VERSION ""

NS_ :

BS_:

BU_: SCM BC1 BC2 ECM PSC ABS Brakes__Drive_Axle_1 EPS IC GPS WCM VCM Seat_Control_1 ISC1 HCU IDT GMRS XM RH AUTON LHC CIM IMU BC3 IC2 EPC1 EPC2 EPC3 EPC4 BMC1 BMC2 APU2 APU1 SRVTOOL RHC RCM

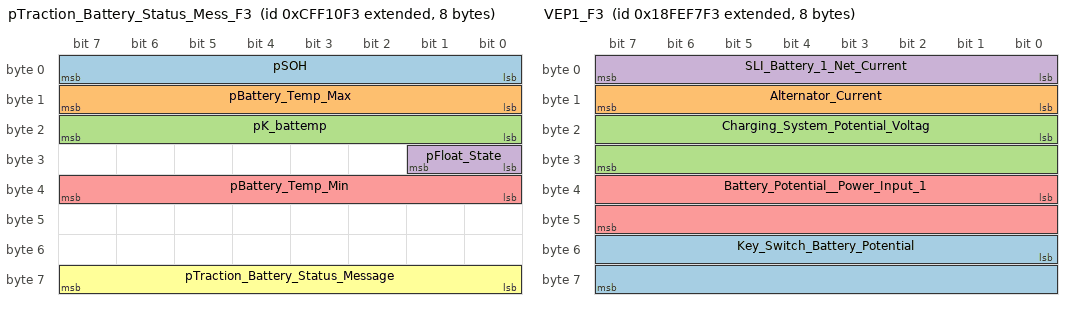
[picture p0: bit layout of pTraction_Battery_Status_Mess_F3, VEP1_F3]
BO_ 2365526259 pTraction_Battery_Status_Mess_F3: 8 BMC1
 SG_ pSOH : 0|8@1+ (0.5,0) [0|127] "%" Vector__XXX
 SG_ pBattery_Temp_Max : 8|8@1+ (1,-40) [-40|295] "deg C" Vector__XXX
 SG_ pK_battemp : 16|8@1+ (0.5,0) [0|127] "%" Vector__XXX
 SG_ pFloat_State : 24|2@1+ (1,0) [0|3] "state" Vector__XXX
 SG_ pBattery_Temp_Min : 32|8@1+ (1,-40) [-40|295] "deg C" Vector__XXX
 SG_ pTraction_Battery_Status_Message : 56|8@1+ (1,0) [0|255] "" Vector__XXX

BO_ 2566846451 VEP1_F3: 8 BMC1
 SG_ Key_Switch_Battery_Potential : 48|16@1+ (0.05,0) [0|3275.8] "V" Vector__XXX
 SG_ Alternator_Current : 8|8@1+ (1,0) [0|255] "A" Vector__XXX
 SG_ Charging_System_Potential_Voltag : 16|16@1+ (0.05,0) [0|3275.8] "V" Vector__XXX
 SG_ SLI_Battery_1_Net_Current : 0|8@1+ (1,-125) [-125|380] "A" Vector__XXX
 SG_ Battery_Potential__Power_Input_1 : 32|16@1+ (0.05,0) [0|3275.8] "V" Vector__XXX

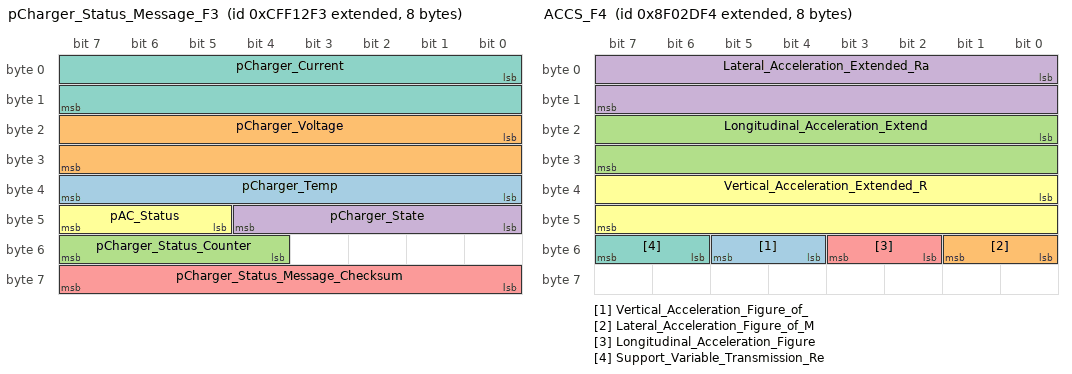
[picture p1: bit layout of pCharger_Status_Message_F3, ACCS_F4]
BO_ 2365526771 pCharger_Status_Message_F3: 8 BMC1
 SG_ pCharger_Temp : 32|8@1+ (1,-40) [-40|295] "deg C" Vector__XXX
 SG_ pCharger_Voltage : 16|16@1+ (0.05,0) [0|3275.8] "V" Vector__XXX
 SG_ pCharger_Status_Counter : 52|4@1+ (1,0) [0|15] "count" Vector__XXX
 SG_ pCharger_State : 40|5@1+ (1,0) [0|31] "state" Vector__XXX
 SG_ pCharger_Status_Message_Checksum : 56|8@1+ (1,0) [0|255] "" Vector__XXX
 SG_ pAC_Status : 45|3@1+ (1,0) [0|7] "state" Vector__XXX
 SG_ pCharger_Current : 0|16@1+ (0.05,-1600) [-1600|4875.8] "A" Vector__XXX

BO_ 2297441780 ACCS_F4: 8 BMC2
 SG_ Vertical_Acceleration_Figure_of_ : 52|2@1+ (1,0) [0|3] "bit" Vector__XXX
 SG_ Lateral_Acceleration_Figure_of_M : 48|2@1+ (1,0) [0|3] "bit" Vector__XXX
 SG_ Longitudinal_Acceleration_Extend : 16|16@1+ (0.01,-320) [-320|974.36] "m/s2" Vector__XXX
 SG_ Lateral_Acceleration_Extended_Ra : 0|16@1+ (0.01,-320) [-320|974.36] "m/s2" Vector__XXX
 SG_ Longitudinal_Acceleration_Figure : 50|2@1+ (1,0) [0|3] "bit" Vector__XXX
 SG_ Vertical_Acceleration_Extended_R : 32|16@1+ (0.01,-320) [-320|974.36] "m/s2" Vector__XXX
 SG_ Support_Variable_Transmission_Re : 54|2@1+ (1,0) [0|3] "bit" Vector__XXX

BO_ 2365526004 pEnergy_Message_F4: 8 BMC2
 SG_ pSOC : 0|8@1+ (0.5,0) [0|127] "%" Vector__XXX
 SG_ pAvailable_Wh : 8|16@1+ (4,0) [0|262143] "kWh" Vector__XXX
 SG_ pWh_in_Since_key_on : 24|32@1+ (1,-131.072) [-131.072|4294967426.072] "Watt-hour" Vector__XXX
 SG_ pEnergy_Message_Checksum : 56|8@1+ (1,0) [0|255] "" Vector__XXX

BO_ 2365525748 pBMC_Power_Message_F4: 8 BMC2
 SG_ pPack_Voltage : 16|16@1+ (0.05,0) [0|3275.8] "V" Vector__XXX
 SG_ pDischarge_Limit : 40|12@1+ (0.5,0) [0|2047] "A" Vector__XXX
 SG_ pPack_Current : 0|16@1+ (0.05,-1600) [-1600|4875.8] "A" Vector__XXX
 SG_ pBMC_Power_Message_Checksum : 56|8@1+ (1,0) [0|255] "" Vector__XXX
 SG_ pCharge_Limit : 44|12@1+ (0.5,0) [0|2047] "A" Vector__XXX

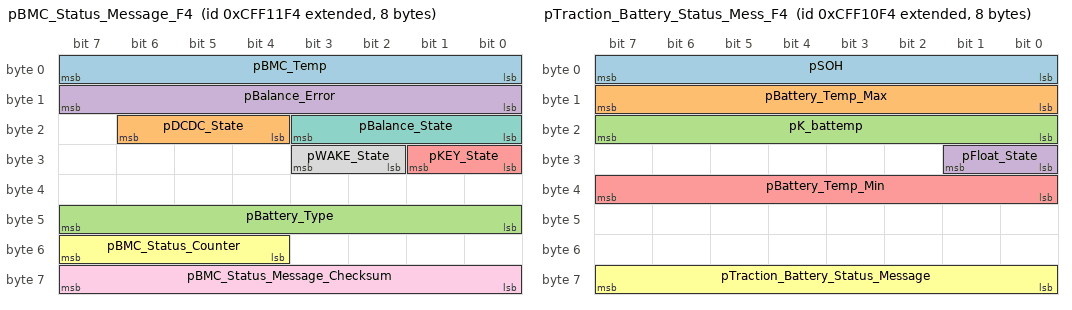
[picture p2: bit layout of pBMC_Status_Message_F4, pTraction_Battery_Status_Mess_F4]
BO_ 2365526516 pBMC_Status_Message_F4: 8 BMC2
 SG_ pBMC_Temp : 0|8@1+ (1,-40) [-40|295] "deg C" Vector__XXX
 SG_ pDCDC_State : 20|3@1+ (1,0) [0|7] "state" Vector__XXX
 SG_ pBattery_Type : 40|8@1+ (1,0) [0|255] "state" Vector__XXX
 SG_ pBalance_Error : 8|8@1+ (0.5,-6.4) [-6.4|133.4] "%" Vector__XXX
 SG_ pKEY_State : 24|2@1+ (1,0) [0|3] "state" Vector__XXX
 SG_ pBMC_Status_Counter : 52|4@1+ (1,0) [0|15] "count" Vector__XXX
 SG_ pBalance_State : 16|4@1+ (1,0) [0|15] "state" Vector__XXX
 SG_ pWAKE_State : 26|2@1+ (1,0) [0|3] "state" Vector__XXX
 SG_ pBMC_Status_Message_Checksum : 56|8@1+ (1,0) [0|255] "" Vector__XXX

BO_ 2365526260 pTraction_Battery_Status_Mess_F4: 8 BMC2
 SG_ pSOH : 0|8@1+ (0.5,0) [0|127] "%" Vector__XXX
 SG_ pBattery_Temp_Max : 8|8@1+ (1,-40) [-40|295] "deg C" Vector__XXX
 SG_ pK_battemp : 16|8@1+ (0.5,0) [0|127] "%" Vector__XXX
 SG_ pFloat_State : 24|2@1+ (1,0) [0|3] "state" Vector__XXX
 SG_ pBattery_Temp_Min : 32|8@1+ (1,-40) [-40|295] "deg C" Vector__XXX
 SG_ pTraction_Battery_Status_Message : 56|8@1+ (1,0) [0|255] "" Vector__XXX

BO_ 2566846452 VEP1_F4: 8 BMC2
 SG_ Key_Switch_Battery_Potential : 48|16@1+ (0.05,0) [0|3275.8] "V" Vector__XXX
 SG_ Alternator_Current : 8|8@1+ (1,0) [0|255] "A" Vector__XXX
 SG_ Charging_System_Potential_Voltag : 16|16@1+ (0.05,0) [0|3275.8] "V" Vector__XXX
 SG_ SLI_Battery_1_Net_Current : 0|8@1+ (1,-125) [-125|380] "A" Vector__XXX
 SG_ Battery_Potential__Power_Input_1 : 32|16@1+ (0.05,0) [0|3275.8] "V" Vector__XXX

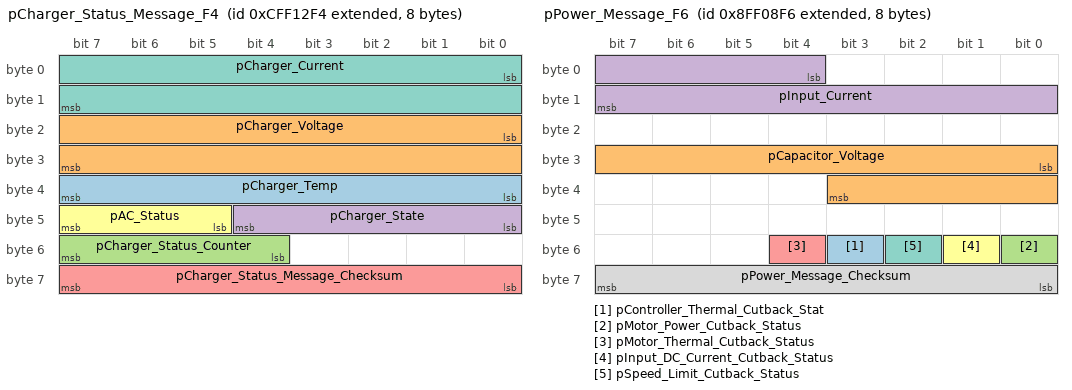
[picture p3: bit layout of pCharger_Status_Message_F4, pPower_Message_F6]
BO_ 2365526772 pCharger_Status_Message_F4: 8 BMC2
 SG_ pCharger_Temp : 32|8@1+ (1,-40) [-40|295] "deg C" Vector__XXX
 SG_ pCharger_Voltage : 16|16@1+ (0.05,0) [0|3275.8] "V" Vector__XXX
 SG_ pCharger_Status_Counter : 52|4@1+ (1,0) [0|15] "count" Vector__XXX
 SG_ pCharger_State : 40|5@1+ (1,0) [0|31] "state" Vector__XXX
 SG_ pCharger_Status_Message_Checksum : 56|8@1+ (1,0) [0|255] "" Vector__XXX
 SG_ pAC_Status : 45|3@1+ (1,0) [0|7] "state" Vector__XXX
 SG_ pCharger_Current : 0|16@1+ (0.05,-1600) [-1600|4875.8] "A" Vector__XXX

BO_ 2298415350 pPower_Message_F6: 8 APU2
 SG_ pController_Thermal_Cutback_Stat : 51|1@1+ (1,0) [0|1] "state" Vector__XXX
 SG_ pCapacitor_Voltage : 24|12@1+ (1,0) [0|4095] "V" Vector__XXX
 SG_ pMotor_Power_Cutback_Status : 48|1@1+ (1,0) [0|1] "state" Vector__XXX
 SG_ pInput_Current : 4|12@1+ (1,-2048) [-2048|6143] "A" Vector__XXX
 SG_ pMotor_Thermal_Cutback_Status : 52|1@1+ (1,0) [0|1] "state" Vector__XXX
 SG_ pInput_DC_Current_Cutback_Status : 49|1@1+ (1,0) [0|1] "state" Vector__XXX
 SG_ pSpeed_Limit_Cutback_Status : 50|1@1+ (1,0) [0|1] "state" Vector__XXX
 SG_ pPower_Message_Checksum : 56|8@1+ (1,0) [0|255] "" Vector__XXX

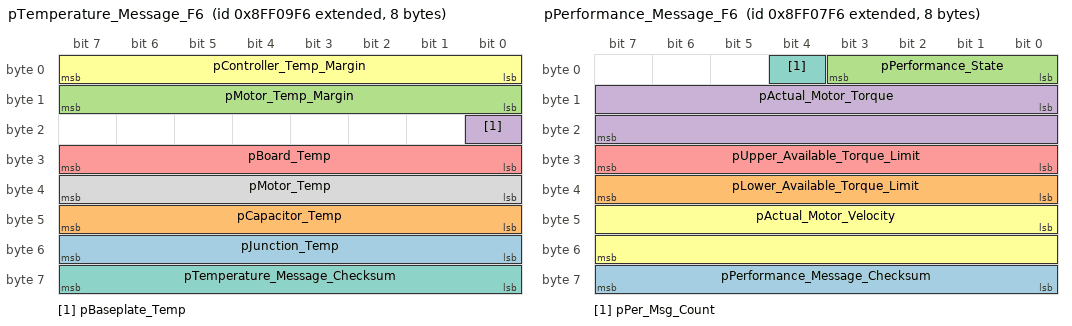
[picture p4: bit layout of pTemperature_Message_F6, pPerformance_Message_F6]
BO_ 2298415606 pTemperature_Message_F6: 8 APU2
 SG_ pJunction_Temp : 48|8@1+ (1,-40) [-40|295] "deg C" Vector__XXX
 SG_ pCapacitor_Temp : 40|8@1+ (1,-40) [-40|295] "deg C" Vector__XXX
 SG_ pMotor_Temp_Margin : 8|8@1+ (1,0) [0|255] "deg C" Vector__XXX
 SG_ pBaseplate_Temp : 16|1@1+ (1,-40) [-40|40] "deg C" Vector__XXX
 SG_ pBoard_Temp : 24|8@1+ (1,-40) [-40|295] "deg C" Vector__XXX
 SG_ pController_Temp_Margin : 0|8@1+ (1,0) [0|255] "deg C" Vector__XXX
 SG_ pTemperature_Message_Checksum : 56|8@1+ (1,0) [0|255] "" Vector__XXX
 SG_ pMotor_Temp : 32|8@1+ (1,-40) [-40|295] "deg C" Vector__XXX

BO_ 2298415094 pPerformance_Message_F6: 8 APU2
 SG_ pPerformance_Message_Checksum : 56|8@1+ (1,0) [0|255] "" Vector__XXX
 SG_ pLower_Available_Torque_Limit : 32|8@1+ (2.5,-312.5) [-312.5|951.5] "Nm" Vector__XXX
 SG_ pPerformance_State : 0|4@1+ (1,0) [0|15] "state" Vector__XXX
 SG_ pActual_Motor_Torque : 8|16@1+ (0.1,-3276.8) [-3276.8|9829.4] "Nm" Vector__XXX
 SG_ pUpper_Available_Torque_Limit : 24|8@1+ (2.5,-312.5) [-312.5|951.5] "Nm" Vector__XXX
 SG_ pActual_Motor_Velocity : 40|16@1+ (1,-32768) [-32768|98303] "rpm" Vector__XXX
 SG_ pPer_Msg_Count : 4|1@1+ (1,0) [0|0] "unknown" Vector__XXX

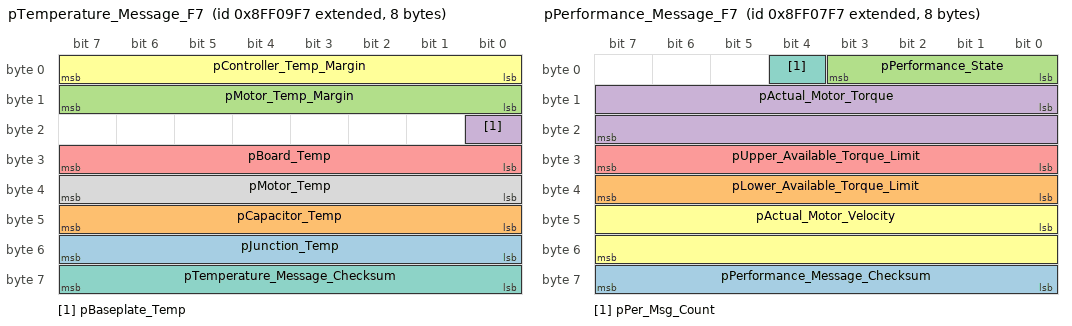
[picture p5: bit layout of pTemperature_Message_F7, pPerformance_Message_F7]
BO_ 2298415607 pTemperature_Message_F7: 8 APU1
 SG_ pJunction_Temp : 48|8@1+ (1,-40) [-40|295] "deg C" Vector__XXX
 SG_ pCapacitor_Temp : 40|8@1+ (1,-40) [-40|295] "deg C" Vector__XXX
 SG_ pMotor_Temp_Margin : 8|8@1+ (1,0) [0|255] "deg C" Vector__XXX
 SG_ pBaseplate_Temp : 16|1@1+ (1,-40) [-40|40] "deg C" Vector__XXX
 SG_ pBoard_Temp : 24|8@1+ (1,-40) [-40|295] "deg C" Vector__XXX
 SG_ pController_Temp_Margin : 0|8@1+ (1,0) [0|255] "deg C" Vector__XXX
 SG_ pTemperature_Message_Checksum : 56|8@1+ (1,0) [0|255] "" Vector__XXX
 SG_ pMotor_Temp : 32|8@1+ (1,-40) [-40|295] "deg C" Vector__XXX

BO_ 2298415095 pPerformance_Message_F7: 8 APU1
 SG_ pPerformance_Message_Checksum : 56|8@1+ (1,0) [0|255] "" Vector__XXX
 SG_ pLower_Available_Torque_Limit : 32|8@1+ (2.5,-312.5) [-312.5|951.5] "Nm" Vector__XXX
 SG_ pPerformance_State : 0|4@1+ (1,0) [0|15] "state" Vector__XXX
 SG_ pActual_Motor_Torque : 8|16@1+ (0.1,-3276.8) [-3276.8|9829.4] "Nm" Vector__XXX
 SG_ pUpper_Available_Torque_Limit : 24|8@1+ (2.5,-312.5) [-312.5|951.5] "Nm" Vector__XXX
 SG_ pActual_Motor_Velocity : 40|16@1+ (1,-32768) [-32768|98303] "rpm" Vector__XXX
 SG_ pPer_Msg_Count : 4|1@1+ (1,0) [0|0] "unknown" Vector__XXX

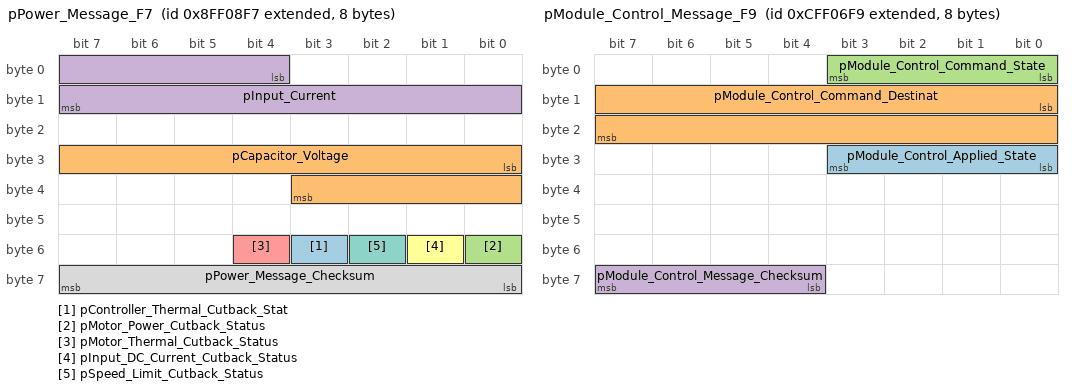
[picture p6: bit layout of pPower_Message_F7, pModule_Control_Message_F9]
BO_ 2298415351 pPower_Message_F7: 8 APU1
 SG_ pController_Thermal_Cutback_Stat : 51|1@1+ (1,0) [0|1] "state" Vector__XXX
 SG_ pCapacitor_Voltage : 24|12@1+ (1,0) [0|4095] "V" Vector__XXX
 SG_ pMotor_Power_Cutback_Status : 48|1@1+ (1,0) [0|1] "state" Vector__XXX
 SG_ pInput_Current : 4|12@1+ (1,-2048) [-2048|6143] "A" Vector__XXX
 SG_ pMotor_Thermal_Cutback_Status : 52|1@1+ (1,0) [0|1] "state" Vector__XXX
 SG_ pInput_DC_Current_Cutback_Status : 49|1@1+ (1,0) [0|1] "state" Vector__XXX
 SG_ pSpeed_Limit_Cutback_Status : 50|1@1+ (1,0) [0|1] "state" Vector__XXX
 SG_ pPower_Message_Checksum : 56|8@1+ (1,0) [0|255] "" Vector__XXX

BO_ 2566834937 DM1_F9: 42 SRVTOOL
 SG_ Flash_Malfunction_Indicator_Lamp : 14|2@1+ (1,0) [0|3] "" Vector__XXX
 SG_ Malfunction_Indicator_Lamp_Statu : 6|2@1+ (1,0) [0|3] "" Vector__XXX
 SG_ Red_Stop_Lamp_Status : 4|2@1+ (1,0) [0|3] "" Vector__XXX
 SG_ Amber_Warning_Lamp_Status : 2|2@1+ (1,0) [0|3] "" Vector__XXX
 SG_ Flash_Red_Stop_Lamp_RSL : 12|2@1+ (1,0) [0|3] "" Vector__XXX
 SG_ Flash_Amber_Warning_Lamp_AWL : 10|2@1+ (1,0) [0|3] "" Vector__XXX
 SG_ Flash_Protect_Lamp : 8|2@1+ (1,0) [0|3] "" Vector__XXX
 SG_ Protect_Lamp_Status : 0|2@1+ (1,0) [0|3] "" Vector__XXX
 SG_ DTC_1 : 16|32@1+ (1,0) [0|4294967295] "value" Vector__XXX
 SG_ DTC_2 : 48|32@1+ (1,0) [0|4294967295] "value" Vector__XXX
 SG_ DTC_3 : 80|32@1+ (1,0) [0|4294967295] "value" Vector__XXX
 SG_ DTC_4 : 112|32@1+ (1,0) [0|4294967295] "value" Vector__XXX
 SG_ DTC_5 : 144|32@1+ (1,0) [0|4294967295] "value" Vector__XXX
 SG_ DTC_6 : 176|32@1+ (1,0) [0|4294967295] "value" Vector__XXX
 SG_ DTC_7 : 208|32@1+ (1,0) [0|4294967295] "value" Vector__XXX
 SG_ DTC_8 : 240|32@1+ (1,0) [0|4294967295] "value" Vector__XXX
 SG_ DTC_9 : 272|32@1+ (1,0) [0|4294967295] "value" Vector__XXX
 SG_ DTC_10 : 304|32@1+ (1,0) [0|4294967295] "value" Vector__XXX

BO_ 2365523705 pModule_Control_Message_F9: 8 SRVTOOL
 SG_ pModule_Control_Applied_State : 24|4@1+ (1,0) [0|15] "state" Vector__XXX
 SG_ pModule_Control_Command_Destinat : 8|16@1+ (1,0) [0|65535] "count" Vector__XXX
 SG_ pModule_Control_Command_State : 0|4@1+ (1,0) [0|15] "state" Vector__XXX
 SG_ pModule_Control_Message_Checksum : 60|4@1+ (1,0) [0|15] "bit" Vector__XXX

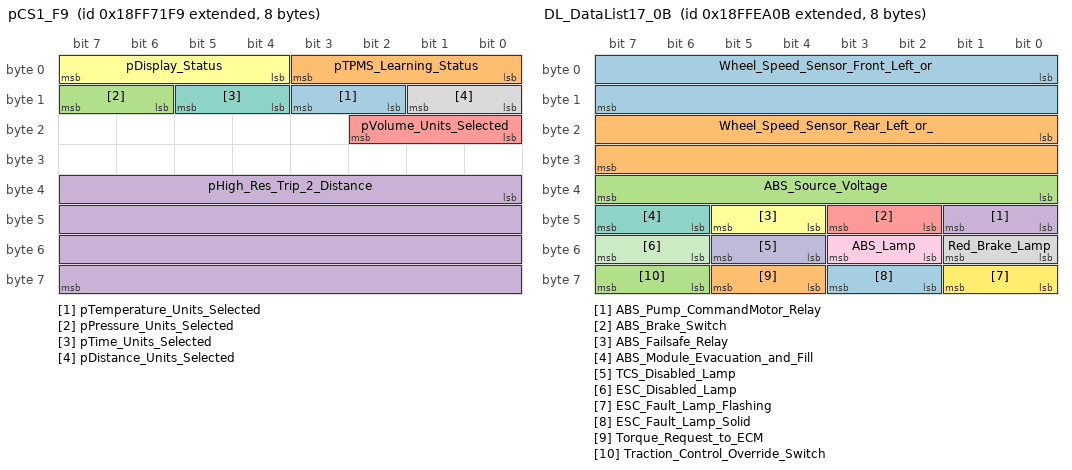
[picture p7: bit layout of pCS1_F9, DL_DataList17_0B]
BO_ 2566877689 pCS1_F9: 8 SRVTOOL
 SG_ pTemperature_Units_Selected : 10|2@1+ (1,0) [0|3] "state" Vector__XXX
 SG_ pTPMS_Learning_Status : 0|4@1+ (1,0) [0|15] "state" Vector__XXX
 SG_ pPressure_Units_Selected : 14|2@1+ (1,0) [0|3] "state" Vector__XXX
 SG_ pHigh_Res_Trip_2_Distance : 32|32@1+ (5,0) [0|21474836479] "km" Vector__XXX
 SG_ pVolume_Units_Selected : 16|3@1+ (1,0) [0|7] "state" Vector__XXX
 SG_ pDisplay_Status : 4|4@1+ (1,0) [0|15] "state" Vector__XXX
 SG_ pTime_Units_Selected : 12|2@1+ (1,0) [0|3] "state" Vector__XXX
 SG_ pDistance_Units_Selected : 8|2@1+ (1,0) [0|3] "state" Vector__XXX

BO_ 2566860071 pISM_27: 8 VCM
 SG_ pSpecial_Msg_12 : 22|2@1+ (1,0) [0|3] "state" Vector__XXX
 SG_ pSpecial_Msg_28 : 54|2@1+ (1,0) [0|3] "state" Vector__XXX
 SG_ pSpecial_Msg_11 : 20|2@1+ (1,0) [0|3] "state" Vector__XXX
 SG_ pSpecial_Msg_26 : 50|2@1+ (1,0) [0|3] "state" Vector__XXX
 SG_ pSpecial_Msg_24 : 46|2@1+ (1,0) [0|3] "state" Vector__XXX
 SG_ pSpecial_Msg_21 : 40|2@1+ (1,0) [0|3] "state" Vector__XXX
 SG_ pSpecial_Msg_18 : 34|2@1+ (1,0) [0|3] "state" Vector__XXX
 SG_ pSpecial_Msg_19 : 36|2@1+ (1,0) [0|3] "state" Vector__XXX
 SG_ pSpecial_Msg_1_Riding_with_Brake : 0|2@1+ (1,0) [0|3] "state" Vector__XXX
 SG_ pSpecial_Msg_2_Regulator_Overhea : 2|2@1+ (1,0) [0|3] "state" Vector__XXX
 SG_ pSpecial_Msg_3_Regulator_Overhea : 4|2@1+ (1,0) [0|3] "state" Vector__XXX
 SG_ pSpecial_Msg_4_Regulator_Overhea : 6|2@1+ (1,0) [0|3] "state" Vector__XXX
 SG_ pSpecial_Msg_5_Engine_Warmup_Com : 8|2@1+ (1,0) [0|3] "state" Vector__XXX
 SG_ pSpecial_Msg_6_Engine_Knock__Mod : 10|2@1+ (1,0) [0|3] "state" Vector__XXX
 SG_ pSpecial_Msg_8_Low_Coolant_Warni : 14|2@1+ (1,0) [0|3] "state" Vector__XXX
 SG_ pSpecial_Msg_7_Engine_Knock__Mos : 12|2@1+ (1,0) [0|3] "state" Vector__XXX
 SG_ pSpecial_Msg_9_Transmission_Temp : 16|2@1+ (1,0) [0|3] "state" Vector__XXX
 SG_ pSpecial_Msg_10_Reverse_Speed_Li : 18|2@1+ (1,0) [0|3] "state" Vector__XXX
 SG_ pSpecial_Msg_13_Belt_Burn_Warnin : 24|2@1+ (1,0) [0|3] "state" Vector__XXX
 SG_ pSpecial_Msg_14_Park_Brake_Warni : 26|2@1+ (1,0) [0|3] "state" Vector__XXX
 SG_ pSpecial_Msg_15_TCM_Comm_Loss : 28|2@1+ (1,0) [0|3] "state" Vector__XXX
 SG_ pSpecial_Msg_16_TCM_Pump_Priming : 30|2@1+ (1,0) [0|3] "state" Vector__XXX
 SG_ pSpecial_Msg_17_Request_User_to_ : 32|2@1+ (1,0) [0|3] "state" Vector__XXX
 SG_ pSpecial_MSG_20_Fuel_Door_Open_E : 38|2@1+ (1,0) [0|3] "state" Vector__XXX
 SG_ pSpecial_MSG_22_Clutch_Overtemp : 42|2@1+ (1,0) [0|3] "state" Vector__XXX
 SG_ pSpecial_MSG_23_Exhaust_Valve_Ch : 44|2@1+ (1,0) [0|3] "state" Vector__XXX
 SG_ pSpecial_MSG_25_Engine_Idle_Shut : 48|2@1+ (1,0) [0|3] "state" Vector__XXX
 SG_ pSpecial_MSG_27_Overboost_Condit : 52|2@1+ (1,0) [0|3] "state" Vector__XXX
 SG_ pSpecial_Msg_31_Engine_Tip_Over_ : 60|2@1+ (1,0) [0|3] "state" Vector__XXX
 SG_ pSpecial_Msg_32_Engine_Tip_Over_ : 62|2@1+ (1,0) [0|3] "state" Vector__XXX

BO_ 2566908427 DL_DataList17_0B: 8 ABS
 SG_ Wheel_Speed_Sensor_Front_Left_or : 0|16@1+ (0.00390625,0) [0|255] "km/h" Vector__XXX
 SG_ Wheel_Speed_Sensor_Rear_Left_or_ : 16|16@1+ (0.00390625,0) [0|255] "km/h" Vector__XXX
 SG_ ABS_Source_Voltage : 32|8@1+ (0.1,0) [0|24.6] "V" Vector__XXX
 SG_ ABS_Pump_CommandMotor_Relay : 40|2@1+ (0,0) [0|-1] "state" Vector__XXX
 SG_ ABS_Brake_Switch : 42|2@1+ (0,0) [0|-1] "state" Vector__XXX
 SG_ ABS_Failsafe_Relay : 44|2@1+ (0,0) [0|-1] "state" Vector__XXX
 SG_ ABS_Module_Evacuation_and_Fill : 46|2@1+ (0,0) [0|-1] "state" Vector__XXX
 SG_ Red_Brake_Lamp : 48|2@1+ (0,0) [0|-1] "state" Vector__XXX
 SG_ ABS_Lamp : 50|2@1+ (0,0) [0|-1] "state" Vector__XXX
 SG_ TCS_Disabled_Lamp : 52|2@1+ (0,0) [0|-1] "state" Vector__XXX
 SG_ ESC_Disabled_Lamp : 54|2@1+ (0,0) [0|-1] "state" Vector__XXX
 SG_ ESC_Fault_Lamp_Flashing : 56|2@1+ (0,0) [0|-1] "state" Vector__XXX
 SG_ ESC_Fault_Lamp_Solid : 58|2@1+ (0,0) [0|-1] "state" Vector__XXX
 SG_ Torque_Request_to_ECM : 60|2@1+ (0,0) [0|-1] "state" Vector__XXX
 SG_ Traction_Control_Override_Switch : 62|2@1+ (0,0) [0|-1] "state" Vector__XXX

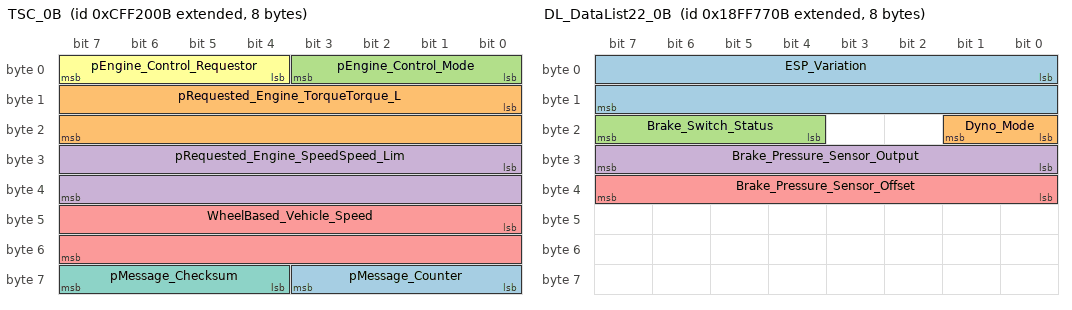
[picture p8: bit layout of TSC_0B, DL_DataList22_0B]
BO_ 2365530123 TSC_0B: 8 ABS
 SG_ pMessage_Counter : 56|4@1+ (1,0) [0|15] "count" Vector__XXX
 SG_ pRequested_Engine_TorqueTorque_L : 8|16@1+ (0.03125,-400) [-400|2447] "Nm" Vector__XXX
 SG_ pEngine_Control_Mode : 0|4@1+ (1,0) [0|15] "state" Vector__XXX
 SG_ pRequested_Engine_SpeedSpeed_Lim : 24|16@1+ (1,0) [0|65535] "rpm" Vector__XXX
 SG_ WheelBased_Vehicle_Speed : 40|16@1+ (0.00390625,0) [0|255] "km/h" Vector__XXX
 SG_ pEngine_Control_Requestor : 4|4@1+ (1,0) [0|15] "state" Vector__XXX
 SG_ pMessage_Checksum : 60|4@1+ (1,0) [0|15] "count" Vector__XXX

BO_ 2566879243 DL_DataList_0B: 8 ABS
 SG_ Wheel_Speed_Sensor_Front_Right : 0|16@1+ (0.00390625,0) [0|255] "km/h" Vector__XXX
 SG_ Wheel_Speed_Sensor_Rear_Right : 16|16@1+ (0.00390625,0) [0|255] "km/h" Vector__XXX
 SG_ Steering_Angle : 32|16@1+ (0.000976563,0) [0|63.000032768] "rad" Vector__XXX
 SG_ Yaw_Rate : 48|16@1+ (0.00012207,0) [0|6.99997952] "rad/s" Vector__XXX

BO_ 2566878987 DL_DataList22_0B: 8 ABS
 SG_ ESP_Variation : 0|16@1+ (0,0) [0|-1] "value" Vector__XXX
 SG_ Dyno_Mode : 16|2@1+ (0,0) [0|-1] "state" Vector__XXX
 SG_ Brake_Switch_Status : 20|4@1+ (0,0) [0|-1] "unknown" Vector__XXX
 SG_ Brake_Pressure_Sensor_Output : 24|8@1+ (100,0) [0|25599] "kPa" Vector__XXX
 SG_ Brake_Pressure_Sensor_Offset : 32|8@1+ (100,0) [0|25599] "kPa" Vector__XXX

BO_ 2566834721 DM1_21: 42 BC1
 SG_ Flash_Malfunction_Indicator_Lamp : 14|2@1+ (1,0) [0|3] "" Vector__XXX
 SG_ Malfunction_Indicator_Lamp_Statu : 6|2@1+ (1,0) [0|3] "" Vector__XXX
 SG_ Red_Stop_Lamp_Status : 4|2@1+ (1,0) [0|3] "" Vector__XXX
 SG_ Amber_Warning_Lamp_Status : 2|2@1+ (1,0) [0|3] "" Vector__XXX
 SG_ Flash_Red_Stop_Lamp_RSL : 12|2@1+ (1,0) [0|3] "" Vector__XXX
 SG_ Flash_Amber_Warning_Lamp_AWL : 10|2@1+ (1,0) [0|3] "" Vector__XXX
 SG_ Flash_Protect_Lamp : 8|2@1+ (1,0) [0|3] "" Vector__XXX
 SG_ Protect_Lamp_Status : 0|2@1+ (1,0) [0|3] "" Vector__XXX
 SG_ DTC_1 : 16|32@1+ (1,0) [0|4294967295] "value" Vector__XXX
 SG_ DTC_2 : 48|32@1+ (1,0) [0|4294967295] "value" Vector__XXX
 SG_ DTC_3 : 80|32@1+ (1,0) [0|4294967295] "value" Vector__XXX
 SG_ DTC_4 : 112|32@1+ (1,0) [0|4294967295] "value" Vector__XXX
 SG_ DTC_5 : 144|32@1+ (1,0) [0|4294967295] "value" Vector__XXX
 SG_ DTC_6 : 176|32@1+ (1,0) [0|4294967295] "value" Vector__XXX
 SG_ DTC_7 : 208|32@1+ (1,0) [0|4294967295] "value" Vector__XXX
 SG_ DTC_8 : 240|32@1+ (1,0) [0|4294967295] "value" Vector__XXX
 SG_ DTC_9 : 272|32@1+ (1,0) [0|4294967295] "value" Vector__XXX
 SG_ DTC_10 : 304|32@1+ (1,0) [0|4294967295] "value" Vector__XXX

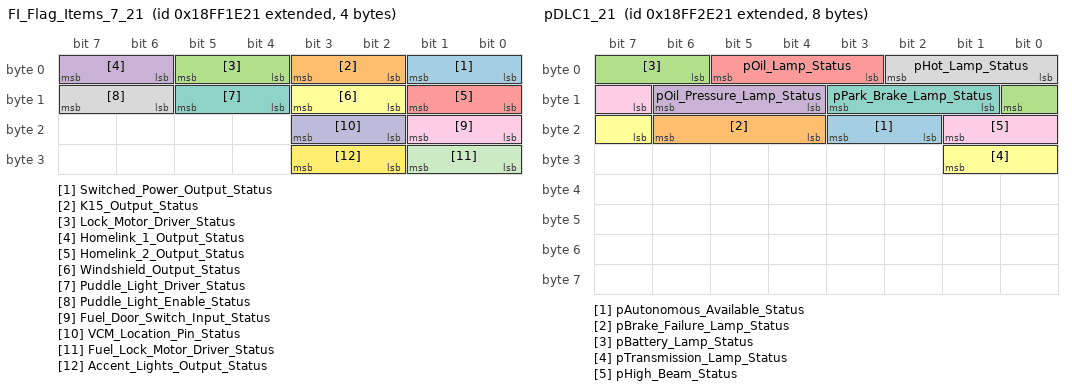
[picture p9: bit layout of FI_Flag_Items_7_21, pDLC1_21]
BO_ 2566856225 FI_Flag_Items_7_21: 4 BC1
 SG_ Switched_Power_Output_Status : 0|2@1+ (1,0) [0|3] "state" Vector__XXX
 SG_ K15_Output_Status : 2|2@1+ (1,0) [0|3] "state" Vector__XXX
 SG_ Lock_Motor_Driver_Status : 4|2@1+ (1,0) [0|3] "state" Vector__XXX
 SG_ Homelink_1_Output_Status : 6|2@1+ (1,0) [0|3] "state" Vector__XXX
 SG_ Homelink_2_Output_Status : 8|2@1+ (1,0) [0|3] "state" Vector__XXX
 SG_ Windshield_Output_Status : 10|2@1+ (1,0) [0|3] "state" Vector__XXX
 SG_ Puddle_Light_Driver_Status : 12|2@1+ (1,0) [0|3] "state" Vector__XXX
 SG_ Puddle_Light_Enable_Status : 14|2@1+ (1,0) [0|3] "state" Vector__XXX
 SG_ Fuel_Door_Switch_Input_Status : 16|2@1+ (1,0) [0|3] "state" Vector__XXX
 SG_ VCM_Location_Pin_Status : 18|2@1+ (1,0) [0|3] "state" Vector__XXX
 SG_ Fuel_Lock_Motor_Driver_Status : 24|2@1+ (1,0) [0|3] "state" Vector__XXX
 SG_ Accent_Lights_Output_Status : 26|2@1+ (1,0) [0|3] "state" Vector__XXX

BO_ 2566860321 pDLC1_21: 8 BC1
 SG_ pAutonomous_Available_Status : 18|2@1+ (1,0) [0|3] "state" Vector__XXX
 SG_ pBrake_Failure_Lamp_Status : 20|3@1+ (1,0) [0|7] "state" Vector__XXX
 SG_ pBattery_Lamp_Status : 6|3@1+ (1,0) [0|7] "state" Vector__XXX
 SG_ pOil_Pressure_Lamp_Status : 12|3@1+ (1,0) [0|7] "state" Vector__XXX
 SG_ pOil_Lamp_Status : 3|3@1+ (1,0) [0|7] "state" Vector__XXX
 SG_ pTransmission_Lamp_Status : 23|3@1+ (1,0) [0|7] "state" Vector__XXX
 SG_ pPark_Brake_Lamp_Status : 9|3@1+ (1,0) [0|7] "state" Vector__XXX
 SG_ pHot_Lamp_Status : 0|3@1+ (1,0) [0|7] "state" Vector__XXX
 SG_ pHigh_Beam_Status : 15|3@1+ (1,0) [0|7] "state" Vector__XXX

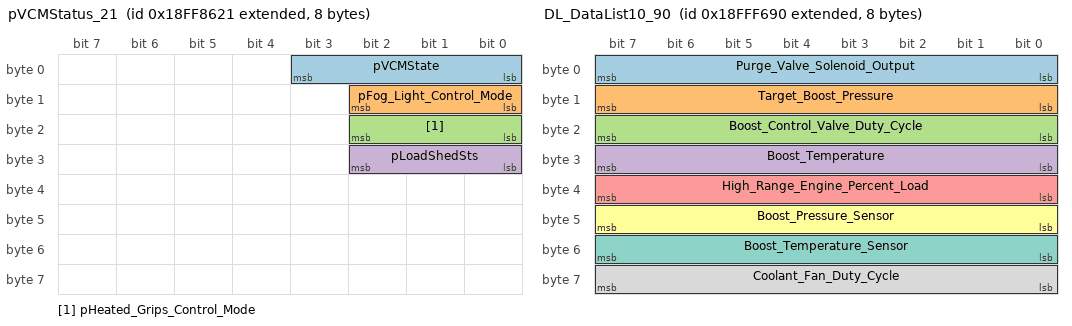
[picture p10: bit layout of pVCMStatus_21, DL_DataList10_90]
BO_ 2566882849 pVCMStatus_21: 8 BC1
 SG_ pVCMState : 0|4@1+ (1,0) [0|15] "state" Vector__XXX
 SG_ pFog_Light_Control_Mode : 8|3@1+ (1,0) [0|7] "state" Vector__XXX
 SG_ pHeated_Grips_Control_Mode : 16|3@1+ (1,0) [0|7] "state" Vector__XXX
 SG_ pLoadShedSts : 24|3@1+ (1,0) [0|7] "state" Vector__XXX

BO_ 2566910497 FI_FlagItems4_21: 8 BC1
 SG_ Hazard_Switch_Input : 0|2@1+ (1,0) [0|3] "state" Vector__XXX
 SG_ LowHigh_Beam_Input : 2|2@1+ (1,0) [0|3] "state" Vector__XXX
 SG_ Fog_Light_Input : 4|2@1+ (1,0) [0|3] "state" Vector__XXX
 SG_ Horn_Input : 6|2@1+ (1,0) [0|3] "state" Vector__XXX
 SG_ High_Beam_Output : 8|2@1+ (1,0) [0|3] "state" Vector__XXX
 SG_ Low_Beam_Output : 10|2@1+ (1,0) [0|3] "state" Vector__XXX
 SG_ Left_Fog_Light_Output : 12|2@1+ (1,0) [0|3] "state" Vector__XXX
 SG_ Right_Fog_Light_Output : 14|2@1+ (1,0) [0|3] "state" Vector__XXX
 SG_ Unlock_Input : 16|2@1+ (1,0) [0|3] "state" Vector__XXX
 SG_ Lock_Input : 18|2@1+ (1,0) [0|3] "state" Vector__XXX
 SG_ Windsheild_Switch_Up_Input : 20|2@1+ (1,0) [0|3] "state" Vector__XXX
 SG_ Windsheild_Switch_Down_Input : 22|2@1+ (1,0) [0|3] "state" Vector__XXX
 SG_ Horn_Output : 24|2@1+ (1,0) [0|3] "state" Vector__XXX
 SG_ Hazard_Light_Output : 26|2@1+ (1,0) [0|3] "state" Vector__XXX
 SG_ Tail_Light_Output : 28|2@1+ (1,0) [0|3] "state" Vector__XXX
 SG_ Brake_Light_Output : 30|2@1+ (1,0) [0|3] "state" Vector__XXX
 SG_ Left_Front_Turn_Signal_Output : 32|2@1+ (1,0) [0|3] "state" Vector__XXX
 SG_ Right_Front_Turn_Signal_Output : 34|2@1+ (1,0) [0|3] "state" Vector__XXX
 SG_ Left_Rear_Turn_Signal_Output : 36|2@1+ (1,0) [0|3] "state" Vector__XXX
 SG_ Right_Rear_Turn_Signal_Output : 38|2@1+ (1,0) [0|3] "state" Vector__XXX
 SG_ Secondary_Air_Valve_Output : 40|2@1+ (1,0) [0|3] "state" Vector__XXX
 SG_ Secondary_Air_Valve_Command : 42|2@1+ (1,0) [0|3] "state" Vector__XXX
 SG_ Heated_Grip_Heat_Increase_Switch : 44|2@1+ (1,0) [0|3] "state" Vector__XXX
 SG_ Heated_Grip_Heat_Decrease_Switch : 46|2@1+ (1,0) [0|3] "state" Vector__XXX
 SG_ pOperator_Button_1 : 48|2@1+ (1,0) [0|3] "state" Vector__XXX
 SG_ pOperator_Button_2 : 50|2@1+ (1,0) [0|3] "state" Vector__XXX
 SG_ pSide_Stand_Switch : 52|2@1+ (1,0) [0|3] "state" Vector__XXX
 SG_ Coolant_Fluid_Level_Switch : 54|2@1+ (1,0) [0|3] "state" Vector__XXX
 SG_ Driveline_Momentary_Left : 56|2@1+ (1,0) [0|3] "bit" Vector__XXX
 SG_ Driveline_Momentary_Right : 58|2@1+ (1,0) [0|3] "bit" Vector__XXX
 SG_ Seatbelt_Switch : 60|2@1+ (1,0) [0|3] "bit" Vector__XXX
 SG_ Brake_Fluid_Level_Switch : 62|2@1+ (1,0) [0|3] "bit" Vector__XXX

BO_ 2566911632 DL_DataList10_90: 8 BC2
 SG_ Purge_Valve_Solenoid_Output : 0|8@1+ (0.4,0) [0|101.4] "%" Vector__XXX
 SG_ Target_Boost_Pressure : 8|8@1+ (2,0) [0|511] "kPa" Vector__XXX
 SG_ Boost_Control_Valve_Duty_Cycle : 16|8@1+ (0.4,0) [0|101.4] "%" Vector__XXX
 SG_ Boost_Temperature : 24|8@1+ (1,0) [0|255] "deg C" Vector__XXX
 SG_ High_Range_Engine_Percent_Load : 32|8@1+ (2,0) [0|511] "%" Vector__XXX
 SG_ Boost_Pressure_Sensor : 40|8@1+ (0.025,0) [0|5.4] "V" Vector__XXX
 SG_ Boost_Temperature_Sensor : 48|8@1+ (0.025,0) [0|5.4] "V" Vector__XXX
 SG_ Coolant_Fan_Duty_Cycle : 56|8@1+ (0.4,0) [0|101.4] "%" Vector__XXX

BO_ 2566834832 DM1_90: 42 BC2
 SG_ Flash_Malfunction_Indicator_Lamp : 14|2@1+ (1,0) [0|3] "" Vector__XXX
 SG_ Malfunction_Indicator_Lamp_Statu : 6|2@1+ (1,0) [0|3] "" Vector__XXX
 SG_ Red_Stop_Lamp_Status : 4|2@1+ (1,0) [0|3] "" Vector__XXX
 SG_ Amber_Warning_Lamp_Status : 2|2@1+ (1,0) [0|3] "" Vector__XXX
 SG_ Flash_Red_Stop_Lamp_RSL : 12|2@1+ (1,0) [0|3] "" Vector__XXX
 SG_ Flash_Amber_Warning_Lamp_AWL : 10|2@1+ (1,0) [0|3] "" Vector__XXX
 SG_ Flash_Protect_Lamp : 8|2@1+ (1,0) [0|3] "" Vector__XXX
 SG_ Protect_Lamp_Status : 0|2@1+ (1,0) [0|3] "" Vector__XXX
 SG_ DTC_1 : 16|32@1+ (1,0) [0|4294967295] "value" Vector__XXX
 SG_ DTC_2 : 48|32@1+ (1,0) [0|4294967295] "value" Vector__XXX
 SG_ DTC_3 : 80|32@1+ (1,0) [0|4294967295] "value" Vector__XXX
 SG_ DTC_4 : 112|32@1+ (1,0) [0|4294967295] "value" Vector__XXX
 SG_ DTC_5 : 144|32@1+ (1,0) [0|4294967295] "value" Vector__XXX
 SG_ DTC_6 : 176|32@1+ (1,0) [0|4294967295] "value" Vector__XXX
 SG_ DTC_7 : 208|32@1+ (1,0) [0|4294967295] "value" Vector__XXX
 SG_ DTC_8 : 240|32@1+ (1,0) [0|4294967295] "value" Vector__XXX
 SG_ DTC_9 : 272|32@1+ (1,0) [0|4294967295] "value" Vector__XXX
 SG_ DTC_10 : 304|32@1+ (1,0) [0|4294967295] "value" Vector__XXX

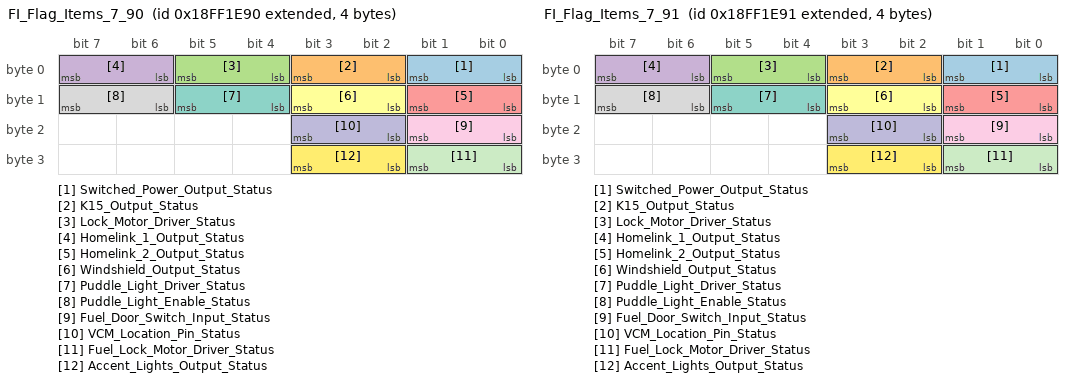
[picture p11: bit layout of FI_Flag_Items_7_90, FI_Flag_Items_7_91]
BO_ 2566856336 FI_Flag_Items_7_90: 4 BC2
 SG_ Switched_Power_Output_Status : 0|2@1+ (1,0) [0|3] "state" Vector__XXX
 SG_ K15_Output_Status : 2|2@1+ (1,0) [0|3] "state" Vector__XXX
 SG_ Lock_Motor_Driver_Status : 4|2@1+ (1,0) [0|3] "state" Vector__XXX
 SG_ Homelink_1_Output_Status : 6|2@1+ (1,0) [0|3] "state" Vector__XXX
 SG_ Homelink_2_Output_Status : 8|2@1+ (1,0) [0|3] "state" Vector__XXX
 SG_ Windshield_Output_Status : 10|2@1+ (1,0) [0|3] "state" Vector__XXX
 SG_ Puddle_Light_Driver_Status : 12|2@1+ (1,0) [0|3] "state" Vector__XXX
 SG_ Puddle_Light_Enable_Status : 14|2@1+ (1,0) [0|3] "state" Vector__XXX
 SG_ Fuel_Door_Switch_Input_Status : 16|2@1+ (1,0) [0|3] "state" Vector__XXX
 SG_ VCM_Location_Pin_Status : 18|2@1+ (1,0) [0|3] "state" Vector__XXX
 SG_ Fuel_Lock_Motor_Driver_Status : 24|2@1+ (1,0) [0|3] "state" Vector__XXX
 SG_ Accent_Lights_Output_Status : 26|2@1+ (1,0) [0|3] "state" Vector__XXX

BO_ 2566910608 FI_FlagItems4_90: 8 BC2
 SG_ Hazard_Switch_Input : 0|2@1+ (1,0) [0|3] "state" Vector__XXX
 SG_ LowHigh_Beam_Input : 2|2@1+ (1,0) [0|3] "state" Vector__XXX
 SG_ Fog_Light_Input : 4|2@1+ (1,0) [0|3] "state" Vector__XXX
 SG_ Horn_Input : 6|2@1+ (1,0) [0|3] "state" Vector__XXX
 SG_ High_Beam_Output : 8|2@1+ (1,0) [0|3] "state" Vector__XXX
 SG_ Low_Beam_Output : 10|2@1+ (1,0) [0|3] "state" Vector__XXX
 SG_ Left_Fog_Light_Output : 12|2@1+ (1,0) [0|3] "state" Vector__XXX
 SG_ Right_Fog_Light_Output : 14|2@1+ (1,0) [0|3] "state" Vector__XXX
 SG_ Unlock_Input : 16|2@1+ (1,0) [0|3] "state" Vector__XXX
 SG_ Lock_Input : 18|2@1+ (1,0) [0|3] "state" Vector__XXX
 SG_ Windsheild_Switch_Up_Input : 20|2@1+ (1,0) [0|3] "state" Vector__XXX
 SG_ Windsheild_Switch_Down_Input : 22|2@1+ (1,0) [0|3] "state" Vector__XXX
 SG_ Horn_Output : 24|2@1+ (1,0) [0|3] "state" Vector__XXX
 SG_ Hazard_Light_Output : 26|2@1+ (1,0) [0|3] "state" Vector__XXX
 SG_ Tail_Light_Output : 28|2@1+ (1,0) [0|3] "state" Vector__XXX
 SG_ Brake_Light_Output : 30|2@1+ (1,0) [0|3] "state" Vector__XXX
 SG_ Left_Front_Turn_Signal_Output : 32|2@1+ (1,0) [0|3] "state" Vector__XXX
 SG_ Right_Front_Turn_Signal_Output : 34|2@1+ (1,0) [0|3] "state" Vector__XXX
 SG_ Left_Rear_Turn_Signal_Output : 36|2@1+ (1,0) [0|3] "state" Vector__XXX
 SG_ Right_Rear_Turn_Signal_Output : 38|2@1+ (1,0) [0|3] "state" Vector__XXX
 SG_ Secondary_Air_Valve_Output : 40|2@1+ (1,0) [0|3] "state" Vector__XXX
 SG_ Secondary_Air_Valve_Command : 42|2@1+ (1,0) [0|3] "state" Vector__XXX
 SG_ Heated_Grip_Heat_Increase_Switch : 44|2@1+ (1,0) [0|3] "state" Vector__XXX
 SG_ Heated_Grip_Heat_Decrease_Switch : 46|2@1+ (1,0) [0|3] "state" Vector__XXX
 SG_ pOperator_Button_1 : 48|2@1+ (1,0) [0|3] "state" Vector__XXX
 SG_ pOperator_Button_2 : 50|2@1+ (1,0) [0|3] "state" Vector__XXX
 SG_ pSide_Stand_Switch : 52|2@1+ (1,0) [0|3] "state" Vector__XXX
 SG_ Coolant_Fluid_Level_Switch : 54|2@1+ (1,0) [0|3] "state" Vector__XXX
 SG_ Driveline_Momentary_Left : 56|2@1+ (1,0) [0|3] "bit" Vector__XXX
 SG_ Driveline_Momentary_Right : 58|2@1+ (1,0) [0|3] "bit" Vector__XXX
 SG_ Seatbelt_Switch : 60|2@1+ (1,0) [0|3] "bit" Vector__XXX
 SG_ Brake_Fluid_Level_Switch : 62|2@1+ (1,0) [0|3] "bit" Vector__XXX

BO_ 2566856337 FI_Flag_Items_7_91: 4 BC3
 SG_ Switched_Power_Output_Status : 0|2@1+ (1,0) [0|3] "state" Vector__XXX
 SG_ K15_Output_Status : 2|2@1+ (1,0) [0|3] "state" Vector__XXX
 SG_ Lock_Motor_Driver_Status : 4|2@1+ (1,0) [0|3] "state" Vector__XXX
 SG_ Homelink_1_Output_Status : 6|2@1+ (1,0) [0|3] "state" Vector__XXX
 SG_ Homelink_2_Output_Status : 8|2@1+ (1,0) [0|3] "state" Vector__XXX
 SG_ Windshield_Output_Status : 10|2@1+ (1,0) [0|3] "state" Vector__XXX
 SG_ Puddle_Light_Driver_Status : 12|2@1+ (1,0) [0|3] "state" Vector__XXX
 SG_ Puddle_Light_Enable_Status : 14|2@1+ (1,0) [0|3] "state" Vector__XXX
 SG_ Fuel_Door_Switch_Input_Status : 16|2@1+ (1,0) [0|3] "state" Vector__XXX
 SG_ VCM_Location_Pin_Status : 18|2@1+ (1,0) [0|3] "state" Vector__XXX
 SG_ Fuel_Lock_Motor_Driver_Status : 24|2@1+ (1,0) [0|3] "state" Vector__XXX
 SG_ Accent_Lights_Output_Status : 26|2@1+ (1,0) [0|3] "state" Vector__XXX

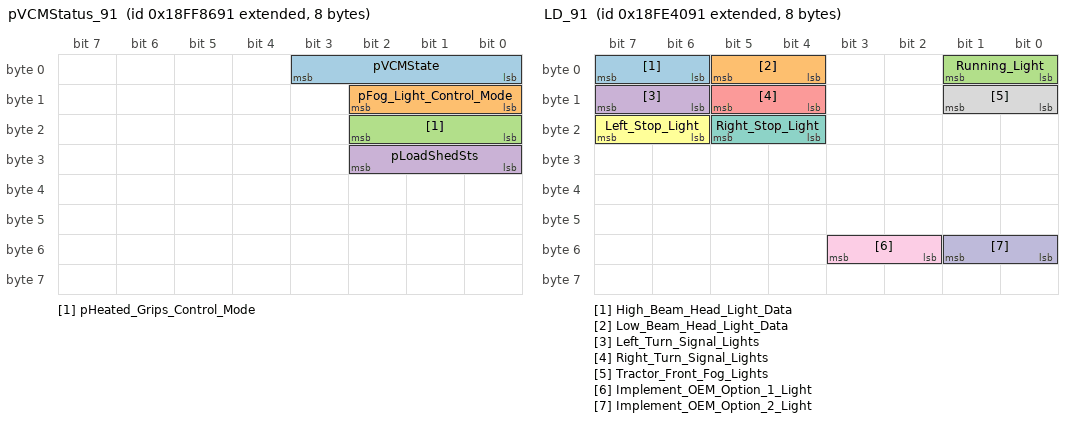
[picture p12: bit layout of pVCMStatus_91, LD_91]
BO_ 2566882961 pVCMStatus_91: 8 BC3
 SG_ pVCMState : 0|4@1+ (1,0) [0|15] "state" Vector__XXX
 SG_ pFog_Light_Control_Mode : 8|3@1+ (1,0) [0|7] "state" Vector__XXX
 SG_ pHeated_Grips_Control_Mode : 16|3@1+ (1,0) [0|7] "state" Vector__XXX
 SG_ pLoadShedSts : 24|3@1+ (1,0) [0|7] "state" Vector__XXX

BO_ 2566834833 DM1_91: 42 BC3
 SG_ Flash_Malfunction_Indicator_Lamp : 14|2@1+ (1,0) [0|3] "" Vector__XXX
 SG_ Malfunction_Indicator_Lamp_Statu : 6|2@1+ (1,0) [0|3] "" Vector__XXX
 SG_ Red_Stop_Lamp_Status : 4|2@1+ (1,0) [0|3] "" Vector__XXX
 SG_ Amber_Warning_Lamp_Status : 2|2@1+ (1,0) [0|3] "" Vector__XXX
 SG_ Flash_Red_Stop_Lamp_RSL : 12|2@1+ (1,0) [0|3] "" Vector__XXX
 SG_ Flash_Amber_Warning_Lamp_AWL : 10|2@1+ (1,0) [0|3] "" Vector__XXX
 SG_ Flash_Protect_Lamp : 8|2@1+ (1,0) [0|3] "" Vector__XXX
 SG_ Protect_Lamp_Status : 0|2@1+ (1,0) [0|3] "" Vector__XXX
 SG_ DTC_1 : 16|32@1+ (1,0) [0|4294967295] "value" Vector__XXX
 SG_ DTC_2 : 48|32@1+ (1,0) [0|4294967295] "value" Vector__XXX
 SG_ DTC_3 : 80|32@1+ (1,0) [0|4294967295] "value" Vector__XXX
 SG_ DTC_4 : 112|32@1+ (1,0) [0|4294967295] "value" Vector__XXX
 SG_ DTC_5 : 144|32@1+ (1,0) [0|4294967295] "value" Vector__XXX
 SG_ DTC_6 : 176|32@1+ (1,0) [0|4294967295] "value" Vector__XXX
 SG_ DTC_7 : 208|32@1+ (1,0) [0|4294967295] "value" Vector__XXX
 SG_ DTC_8 : 240|32@1+ (1,0) [0|4294967295] "value" Vector__XXX
 SG_ DTC_9 : 272|32@1+ (1,0) [0|4294967295] "value" Vector__XXX
 SG_ DTC_10 : 304|32@1+ (1,0) [0|4294967295] "value" Vector__XXX

BO_ 2566799505 LD_91: 8 BC3
 SG_ High_Beam_Head_Light_Data : 6|2@1+ (1,0) [0|3] "bit" Vector__XXX
 SG_ Low_Beam_Head_Light_Data : 4|2@1+ (1,0) [0|3] "bit" Vector__XXX
 SG_ Running_Light : 0|2@1+ (1,0) [0|3] "bit" Vector__XXX
 SG_ Left_Turn_Signal_Lights : 14|2@1+ (1,0) [0|3] "bit" Vector__XXX
 SG_ Right_Turn_Signal_Lights : 12|2@1+ (1,0) [0|3] "bit" Vector__XXX
 SG_ Left_Stop_Light : 22|2@1+ (1,0) [0|3] "bit" Vector__XXX
 SG_ Right_Stop_Light : 20|2@1+ (1,0) [0|3] "bit" Vector__XXX
 SG_ Tractor_Front_Fog_Lights : 8|2@1+ (1,0) [0|3] "bit" Vector__XXX
 SG_ Implement_OEM_Option_1_Light : 50|2@1+ (1,0) [0|3] "bit" Vector__XXX
 SG_ Implement_OEM_Option_2_Light : 48|2@1+ (1,0) [0|3] "bit" Vector__XXX

BO_ 2566909952 DL_DataList11_00: 8 ECM
 SG_ Lifetime_Engine_Running_Time_Acc : 0|16@1+ (2,0) [0|131071] "min" Vector__XXX
 SG_ Engine_Running_Time_Since_Key_On : 16|16@1+ (2,0) [0|131071] "min" Vector__XXX
 SG_ Engine_Oil_Pressure : 32|8@1+ (4,0) [0|1023] "kPa" Vector__XXX
 SG_ Engine_Oil_Pressure_Sensor : 40|8@1+ (0.025,0) [0|5.4] "V" Vector__XXX
 SG_ Intercooler_Fan_Driver_1_Duty_Cy : 48|8@1+ (0.4,0) [0|101.4] "%" Vector__XXX

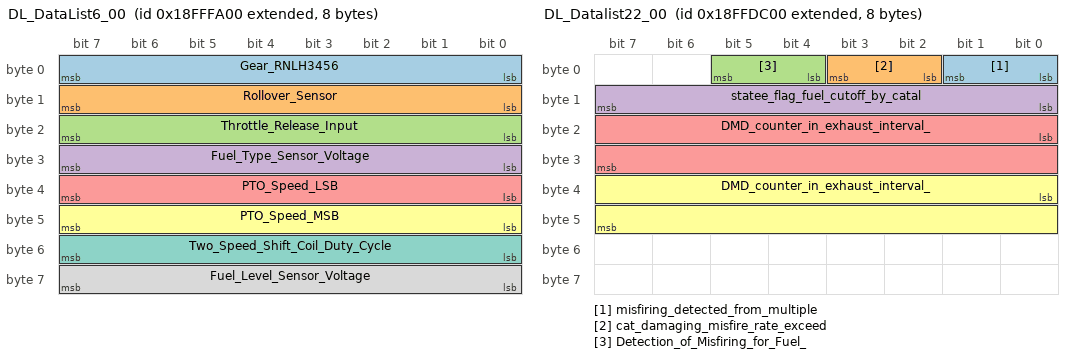
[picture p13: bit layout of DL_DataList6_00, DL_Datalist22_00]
BO_ 2566912512 DL_DataList6_00: 8 ECM
 SG_ Gear_RNLH3456 : 0|8@1+ (0.1,0) [0|24.6] "V" Vector__XXX
 SG_ Rollover_Sensor : 8|8@1+ (0.025,0) [0|5.4] "V" Vector__XXX
 SG_ Throttle_Release_Input : 16|8@1+ (0.1,0) [0|24.6] "V" Vector__XXX
 SG_ Fuel_Type_Sensor_Voltage : 24|8@1+ (0.1,0) [0|24.6] "V" Vector__XXX
 SG_ PTO_Speed_LSB : 32|8@1+ (1,0) [0|255] "rpm" Vector__XXX
 SG_ PTO_Speed_MSB : 40|8@1+ (1,0) [0|255] "rpm" Vector__XXX
 SG_ Two_Speed_Shift_Coil_Duty_Cycle : 48|8@1+ (0.4,0) [0|101.4] "%" Vector__XXX
 SG_ Fuel_Level_Sensor_Voltage : 56|8@1+ (0.05,0) [0|11.8] "V" Vector__XXX

BO_ 2566911232 FI_FlagItems1_00: 8 ECM
 SG_ Fuel_Pump_Driver_Circuit_OnOff : 0|2@1+ (1,0) [0|3] "state" Vector__XXX
 SG_ Rollover_Switch : 2|2@1+ (1,0) [0|3] "state" Vector__XXX
 SG_ Crankshaft_Sensor_Signal_SDI_2X : 4|2@1+ (1,0) [0|3] "state" Vector__XXX
 SG_ Camshaft_Sensor_Signal_SDI_5X : 6|2@1+ (1,0) [0|3] "state" Vector__XXX
 SG_ RPM_Limit_Active : 8|2@1+ (1,0) [0|3] "state" Vector__XXX
 SG_ Idle_Switch : 10|2@1+ (1,0) [0|3] "state" Vector__XXX
 SG_ Cycle_Synchronization : 12|2@1+ (1,0) [0|3] "state" Vector__XXX
 SG_ Idle_Speed_Control_Status : 14|2@1+ (1,0) [0|3] "state" Vector__XXX
 SG_ Ignition_Switch_Input : 16|2@1+ (1,0) [0|3] "state" Vector__XXX
 SG_ RunStop_Switch_Input : 18|2@1+ (1,0) [0|3] "state" Vector__XXX
 SG_ Start_Switch_Input : 20|2@1+ (1,0) [0|3] "state" Vector__XXX
 SG_ Throttle_Release_Switch_Input : 22|2@1+ (1,0) [0|3] "state" Vector__XXX
 SG_ Fan_Relay_Output : 24|2@1+ (1,0) [0|3] "state" Vector__XXX
 SG_ Intercooler_Fan_Output : 26|2@1+ (1,0) [0|3] "state" Vector__XXX
 SG_ Reverse_Alarm_Output : 28|2@1+ (1,0) [0|3] "state" Vector__XXX
 SG_ Main_Relay_Output : 30|2@1+ (1,0) [0|3] "state" Vector__XXX
 SG_ Start_Solenoid_OutputLSD : 32|2@1+ (1,0) [0|3] "state" Vector__XXX
 SG_ Ignition_Relay_Output : 34|2@1+ (1,0) [0|3] "state" Vector__XXX
 SG_ Chassis_Relay_Output : 36|2@1+ (1,0) [0|3] "state" Vector__XXX
 SG_ Starter_Enable_OutputHSD : 38|2@1+ (1,0) [0|3] "state" Vector__XXX
 SG_ Exhaust_Valve_Output : 40|2@1+ (1,0) [0|3] "state" Vector__XXX
 SG_ Battery_Charge_Relay_Output : 42|2@1+ (1,0) [0|3] "state" Vector__XXX
 SG_ HeaterAccessory_Relay : 44|2@1+ (1,0) [0|3] "state" Vector__XXX
 SG_ Intercooler_Pump_Driver_Circuit_ : 46|2@1+ (1,0) [0|3] "state" Vector__XXX
 SG_ MIL_Lamp_Output : 48|2@1+ (1,0) [0|3] "state" Vector__XXX
 SG_ Over_Temperature_Lamp_Output : 50|2@1+ (1,0) [0|3] "state" Vector__XXX
 SG_ KnockDetination_Lamp_Output : 52|2@1+ (1,0) [0|3] "state" Vector__XXX
 SG_ Clutch_Switch_Input_1BOT : 56|2@1+ (1,0) [0|3] "state" Vector__XXX
 SG_ Electronic_Oil_Pump_Driver_Circu : 58|2@1+ (1,0) [0|3] "state" Vector__XXX
 SG_ Fuel_Pull_Solenoid_Status : 60|2@1+ (1,0) [0|3] "state" Vector__XXX
 SG_ Clutch_Switch_Input_2TOT : 62|2@1+ (1,0) [0|3] "state" Vector__XXX
 SG_ Turbo_Oil_Pump_Driver_Circuit : 54|2@1+ (1,0) [0|3] "state" Vector__XXX

BO_ 2566904832 DL_Datalist22_00: 8 ECM
 SG_ misfiring_detected_from_multiple : 0|2@1+ (0,0) [0|-1] "state" Vector__XXX
 SG_ cat_damaging_misfire_rate_exceed : 2|2@1+ (0,0) [0|-1] "state" Vector__XXX
 SG_ Detection_of_Misfiring_for_Fuel_ : 4|2@1+ (0,0) [0|-1] "state" Vector__XXX
 SG_ statee_flag_fuel_cutoff_by_catal : 8|8@1+ (0,0) [0|-1] "count" Vector__XXX
 SG_ DMD_counter_in_exhaust_interval_ : 16|16@1+ (0,0) [0|-1] "count" Vector__XXX
 SG_ DMD_counter_in_exhaust_interval_ : 32|16@1+ (0,0) [0|-1] "count" Vector__XXX

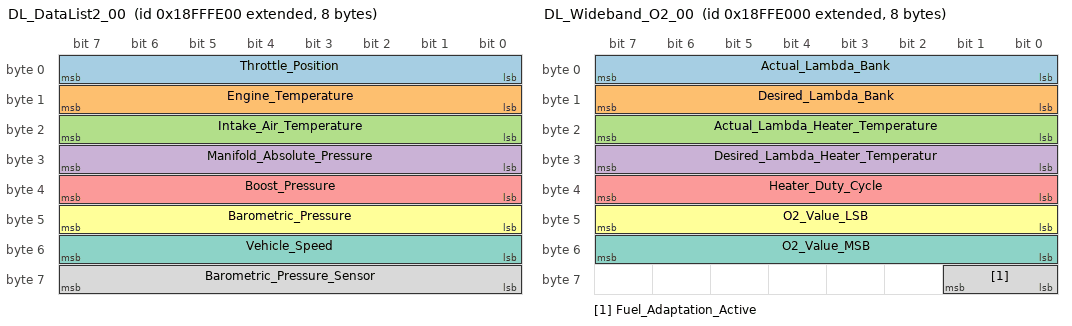
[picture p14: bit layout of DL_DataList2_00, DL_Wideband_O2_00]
BO_ 2566913536 DL_DataList2_00: 8 ECM
 SG_ Throttle_Position : 0|8@1+ (0.4,0) [0|101.4] "%" Vector__XXX
 SG_ Engine_Temperature : 8|8@1+ (1,0) [0|255] "deg C" Vector__XXX
 SG_ Intake_Air_Temperature : 16|8@1+ (1,0) [0|255] "deg C" Vector__XXX
 SG_ Manifold_Absolute_Pressure : 24|8@1+ (2,0) [0|511] "kPa" Vector__XXX
 SG_ Boost_Pressure : 32|8@1+ (2,0) [0|511] "kPa" Vector__XXX
 SG_ Barometric_Pressure : 40|8@1+ (0.5,0) [0|127] "kPa" Vector__XXX
 SG_ Vehicle_Speed : 48|8@1+ (1,0) [0|255] "km/h" Vector__XXX
 SG_ Barometric_Pressure_Sensor : 56|8@1+ (0.025,0) [0|5.4] "V" Vector__XXX

BO_ 2566905856 DL_Wideband_O2_00: 8 ECM
 SG_ Actual_Lambda_Bank : 0|8@1+ (0.064,0) [0|15.384] "unknown" Vector__XXX
 SG_ Desired_Lambda_Bank : 8|8@1+ (0.064,0) [0|15.384] "unknown" Vector__XXX
 SG_ Actual_Lambda_Heater_Temperature : 16|8@1+ (5,0) [0|1279] "deg C" Vector__XXX
 SG_ Desired_Lambda_Heater_Temperatur : 24|8@1+ (5,0) [0|1279] "deg C" Vector__XXX
 SG_ Heater_Duty_Cycle : 32|8@1+ (0.4,0) [0|101.4] "%" Vector__XXX
 SG_ O2_Value_LSB : 40|8@1+ (0.0025,0) [0|-0.36] "%" Vector__XXX
 SG_ O2_Value_MSB : 48|8@1+ (0.0025,0) [0|-0.36] "%" Vector__XXX
 SG_ Fuel_Adaptation_Active : 56|2@1+ (0,0) [0|-1] "state" Vector__XXX

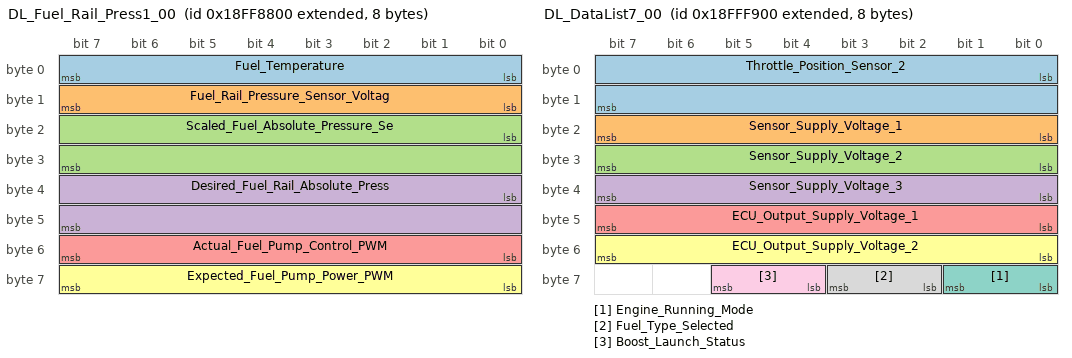
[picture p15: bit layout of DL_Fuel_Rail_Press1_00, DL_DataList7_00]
BO_ 2566883328 DL_Fuel_Rail_Press1_00: 8 ECM
 SG_ Fuel_Temperature : 0|8@1+ (1,0) [0|255] "deg C" Vector__XXX
 SG_ Fuel_Rail_Pressure_Sensor_Voltag : 8|8@1+ (0.01953,0) [0|3.99968] "V" Vector__XXX
 SG_ Scaled_Fuel_Absolute_Pressure_Se : 16|16@1+ (0.4883,0) [0|32000.2288] "kPa" Vector__XXX
 SG_ Desired_Fuel_Rail_Absolute_Press : 32|16@1+ (0.4883,0) [0|32000.2288] "kPa" Vector__XXX
 SG_ Actual_Fuel_Pump_Control_PWM : 48|8@1+ (0.4,0) [0|101.4] "%" Vector__XXX
 SG_ Expected_Fuel_Pump_Power_PWM : 56|8@1+ (0.4,0) [0|101.4] "%" Vector__XXX

BO_ 2566910720 FI_FlagItems3_00: 8 ECM
 SG_ Drive_Mode_1_Input : 0|2@1+ (1,0) [0|3] "state" Vector__XXX
 SG_ Drive_Mode_2_Input : 2|2@1+ (1,0) [0|3] "state" Vector__XXX
 SG_ Drive_Mode_3_Input : 4|2@1+ (1,0) [0|3] "state" Vector__XXX
 SG_ Drive_Mode_4_Input : 6|2@1+ (1,0) [0|3] "state" Vector__XXX
 SG_ Drive_Mode_1_Output : 8|2@1+ (1,0) [0|3] "state" Vector__XXX
 SG_ Drive_Mode_2_Output : 10|2@1+ (1,0) [0|3] "state" Vector__XXX
 SG_ Drive_Mode_3_Output : 12|2@1+ (1,0) [0|3] "state" Vector__XXX
 SG_ Drive_Mode_4_Output : 14|2@1+ (1,0) [0|3] "state" Vector__XXX
 SG_ PTO_Mode_Input : 16|2@1+ (1,0) [0|3] "state" Vector__XXX
 SG_ PTO_Mode_Output : 18|2@1+ (1,0) [0|3] "state" Vector__XXX
 SG_ Drivers_Net : 20|2@1+ (1,0) [0|3] "state" Vector__XXX
 SG_ Drivers_Seatbelt : 22|2@1+ (1,0) [0|3] "state" Vector__XXX
 SG_ Tilt_Lock_Input : 24|2@1+ (1,0) [0|3] "state" Vector__XXX
 SG_ Work_Group_Lock_Input : 26|2@1+ (1,0) [0|3] "state" Vector__XXX
 SG_ Operator_Presence_Input : 28|2@1+ (1,0) [0|3] "state" Vector__XXX
 SG_ Work_Mode_Input : 30|2@1+ (1,0) [0|3] "state" Vector__XXX
 SG_ Tilt_Lock_Output : 32|2@1+ (1,0) [0|3] "state" Vector__XXX
 SG_ Work_Group_Lock_Output : 34|2@1+ (1,0) [0|3] "state" Vector__XXX
 SG_ Operator_Presence_Output : 36|2@1+ (1,0) [0|3] "state" Vector__XXX
 SG_ Tether_Switch_Status : 38|2@1+ (1,0) [0|3] "state" Vector__XXX
 SG_ Foot_on_Cruise_Control_Input : 40|2@1+ (1,0) [0|3] "state" Vector__XXX
 SG_ Cruise_Input : 42|2@1+ (1,0) [0|3] "state" Vector__XXX
 SG_ Treadle_Input : 44|2@1+ (1,0) [0|3] "state" Vector__XXX
 SG_ Cruise_Speed_SetDecel_Input : 46|2@1+ (1,0) [0|3] "state" Vector__XXX
 SG_ Foot_on_Cruise_Control_Output : 48|2@1+ (1,0) [0|3] "state" Vector__XXX
 SG_ Cruise_Output : 50|2@1+ (1,0) [0|3] "state" Vector__XXX
 SG_ Cruise_Control_to_Set_Speed_Outp : 52|2@1+ (1,0) [0|3] "state" Vector__XXX
 SG_ Cruise_Control_ResumeAccel_Outpu : 54|2@1+ (1,0) [0|3] "state" Vector__XXX
 SG_ Cruise_Control_ResumeAccel_Input : 56|2@1+ (1,0) [0|3] "state" Vector__XXX
 SG_ Cruise_Control_Cancel_Input : 58|2@1+ (1,0) [0|3] "state" Vector__XXX
 SG_ Brake_Switch_2_Input : 60|2@1+ (1,0) [0|3] "state" Vector__XXX
 SG_ Oil_Pressure_Switch_Input : 62|2@1+ (1,0) [0|3] "state" Vector__XXX

BO_ 2566912256 DL_DataList7_00: 8 ECM
 SG_ Throttle_Position_Sensor_2 : 0|16@1+ (0.01,0) [0|654.36] "V" Vector__XXX
 SG_ Sensor_Supply_Voltage_1 : 16|8@1+ (0.05,0) [0|11.8] "V" Vector__XXX
 SG_ Sensor_Supply_Voltage_2 : 24|8@1+ (0.05,0) [0|11.8] "V" Vector__XXX
 SG_ Sensor_Supply_Voltage_3 : 32|8@1+ (0.05,0) [0|11.8] "V" Vector__XXX
 SG_ ECU_Output_Supply_Voltage_1 : 40|8@1+ (0.1,0) [0|24.6] "V" Vector__XXX
 SG_ ECU_Output_Supply_Voltage_2 : 48|8@1+ (0.1,0) [0|24.6] "V" Vector__XXX
 SG_ Engine_Running_Mode : 56|2@1+ (0,0) [0|-1] "state" Vector__XXX
 SG_ Fuel_Type_Selected : 58|2@1+ (0,0) [0|-1] "bit" Vector__XXX
 SG_ Boost_Launch_Status : 60|2@1+ (0,0) [0|-1] "state" Vector__XXX

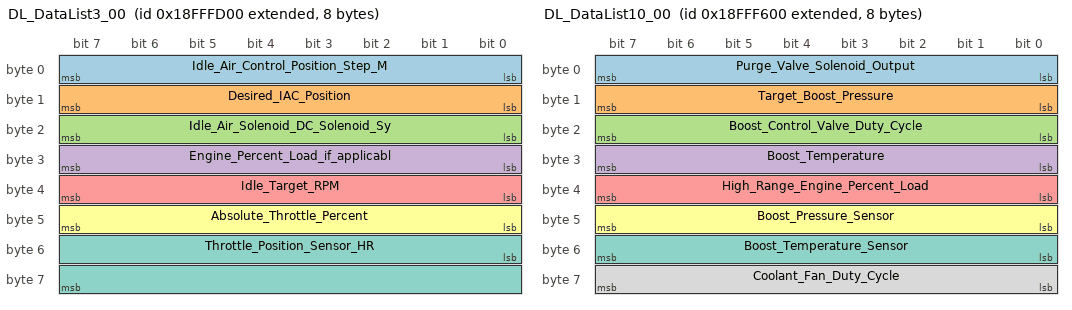
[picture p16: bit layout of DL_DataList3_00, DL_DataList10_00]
BO_ 2566913280 DL_DataList3_00: 8 ECM
 SG_ Idle_Air_Control_Position_Step_M : 0|8@1+ (1,0) [0|255] "bit" Vector__XXX
 SG_ Desired_IAC_Position : 8|8@1+ (1,0) [0|255] "bit" Vector__XXX
 SG_ Idle_Air_Solenoid_DC_Solenoid_Sy : 16|8@1+ (0.4,0) [0|101.4] "%" Vector__XXX
 SG_ Engine_Percent_Load_if_applicabl : 24|8@1+ (0.4,0) [0|101.4] "%" Vector__XXX
 SG_ Idle_Target_RPM : 32|8@1+ (10,0) [0|2559] "rpm" Vector__XXX
 SG_ Absolute_Throttle_Percent : 40|8@1+ (0.4,0) [0|101.4] "%" Vector__XXX
 SG_ Throttle_Position_Sensor_HR : 48|16@1+ (0.001,0) [0|64.536] "V" Vector__XXX

BO_ 2566908672 DL_DataList16_00: 8 ECM
 SG_ Accelerator_Position_Sensor_1 : 0|16@1+ (0.01,0) [0|654.36] "V" Vector__XXX
 SG_ Accelerator_Position_Sensor_2 : 16|16@1+ (0.01,0) [0|654.36] "V" Vector__XXX
 SG_ Brake_Position_Sensor_1 : 32|16@1+ (0.01,0) [0|654.36] "V" Vector__XXX
 SG_ Brake_Position_Sensor_2 : 48|16@1+ (0.01,0) [0|654.36] "V" Vector__XXX

BO_ 2566911488 DL_DataList10_00: 8 ECM
 SG_ Purge_Valve_Solenoid_Output : 0|8@1+ (0.4,0) [0|101.4] "%" Vector__XXX
 SG_ Target_Boost_Pressure : 8|8@1+ (2,0) [0|511] "kPa" Vector__XXX
 SG_ Boost_Control_Valve_Duty_Cycle : 16|8@1+ (0.4,0) [0|101.4] "%" Vector__XXX
 SG_ Boost_Temperature : 24|8@1+ (1,0) [0|255] "deg C" Vector__XXX
 SG_ High_Range_Engine_Percent_Load : 32|8@1+ (2,0) [0|511] "%" Vector__XXX
 SG_ Boost_Pressure_Sensor : 40|8@1+ (0.025,0) [0|5.4] "V" Vector__XXX
 SG_ Boost_Temperature_Sensor : 48|8@1+ (0.025,0) [0|5.4] "V" Vector__XXX
 SG_ Coolant_Fan_Duty_Cycle : 56|8@1+ (0.4,0) [0|101.4] "%" Vector__XXX

BO_ 2566910464 FI_FlagItems4_00: 8 ECM
 SG_ Hazard_Switch_Input : 0|2@1+ (1,0) [0|3] "state" Vector__XXX
 SG_ LowHigh_Beam_Input : 2|2@1+ (1,0) [0|3] "state" Vector__XXX
 SG_ Fog_Light_Input : 4|2@1+ (1,0) [0|3] "state" Vector__XXX
 SG_ Horn_Input : 6|2@1+ (1,0) [0|3] "state" Vector__XXX
 SG_ High_Beam_Output : 8|2@1+ (1,0) [0|3] "state" Vector__XXX
 SG_ Low_Beam_Output : 10|2@1+ (1,0) [0|3] "state" Vector__XXX
 SG_ Left_Fog_Light_Output : 12|2@1+ (1,0) [0|3] "state" Vector__XXX
 SG_ Right_Fog_Light_Output : 14|2@1+ (1,0) [0|3] "state" Vector__XXX
 SG_ Unlock_Input : 16|2@1+ (1,0) [0|3] "state" Vector__XXX
 SG_ Lock_Input : 18|2@1+ (1,0) [0|3] "state" Vector__XXX
 SG_ Windsheild_Switch_Up_Input : 20|2@1+ (1,0) [0|3] "state" Vector__XXX
 SG_ Windsheild_Switch_Down_Input : 22|2@1+ (1,0) [0|3] "state" Vector__XXX
 SG_ Horn_Output : 24|2@1+ (1,0) [0|3] "state" Vector__XXX
 SG_ Hazard_Light_Output : 26|2@1+ (1,0) [0|3] "state" Vector__XXX
 SG_ Tail_Light_Output : 28|2@1+ (1,0) [0|3] "state" Vector__XXX
 SG_ Brake_Light_Output : 30|2@1+ (1,0) [0|3] "state" Vector__XXX
 SG_ Left_Front_Turn_Signal_Output : 32|2@1+ (1,0) [0|3] "state" Vector__XXX
 SG_ Right_Front_Turn_Signal_Output : 34|2@1+ (1,0) [0|3] "state" Vector__XXX
 SG_ Left_Rear_Turn_Signal_Output : 36|2@1+ (1,0) [0|3] "state" Vector__XXX
 SG_ Right_Rear_Turn_Signal_Output : 38|2@1+ (1,0) [0|3] "state" Vector__XXX
 SG_ Secondary_Air_Valve_Output : 40|2@1+ (1,0) [0|3] "state" Vector__XXX
 SG_ Secondary_Air_Valve_Command : 42|2@1+ (1,0) [0|3] "state" Vector__XXX
 SG_ Heated_Grip_Heat_Increase_Switch : 44|2@1+ (1,0) [0|3] "state" Vector__XXX
 SG_ Heated_Grip_Heat_Decrease_Switch : 46|2@1+ (1,0) [0|3] "state" Vector__XXX
 SG_ pOperator_Button_1 : 48|2@1+ (1,0) [0|3] "state" Vector__XXX
 SG_ pOperator_Button_2 : 50|2@1+ (1,0) [0|3] "state" Vector__XXX
 SG_ pSide_Stand_Switch : 52|2@1+ (1,0) [0|3] "state" Vector__XXX
 SG_ Coolant_Fluid_Level_Switch : 54|2@1+ (1,0) [0|3] "state" Vector__XXX
 SG_ Driveline_Momentary_Left : 56|2@1+ (1,0) [0|3] "bit" Vector__XXX
 SG_ Driveline_Momentary_Right : 58|2@1+ (1,0) [0|3] "bit" Vector__XXX
 SG_ Seatbelt_Switch : 60|2@1+ (1,0) [0|3] "bit" Vector__XXX
 SG_ Brake_Fluid_Level_Switch : 62|2@1+ (1,0) [0|3] "bit" Vector__XXX

BO_ 2566908160 DL_DataList18_00: 8 ECM
 SG_ Desired_Torque_Change_for_Idle_S : 0|16@1+ (0.0030518,0) [0|199.0027648] "%" Vector__XXX
 SG_ Throttle_Angle_Mass_Flow_Correct : 16|16@1+ (6.1E-05,0) [0|2.997696] "unknown" Vector__XXX
 SG_ Drag_Torque_Adaptation : 32|16@1+ (0.0030518,0) [0|199.0027648] "%" Vector__XXX
 SG_ Throttle_Body_Learning_Step : 48|8@1+ (1,0) [0|255] "bit" Vector__XXX

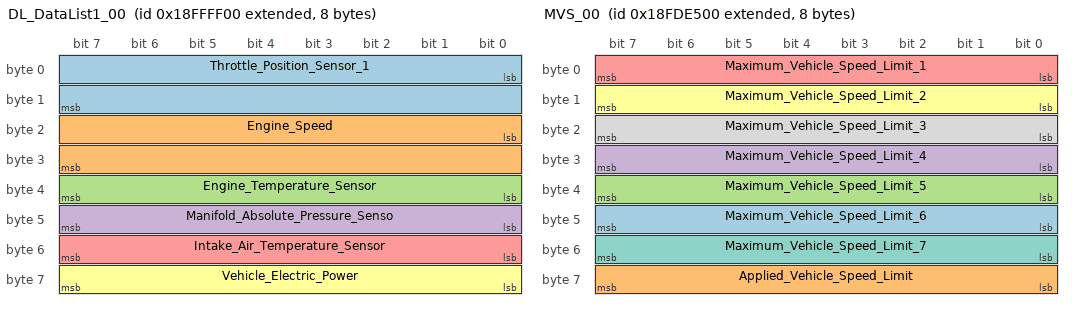
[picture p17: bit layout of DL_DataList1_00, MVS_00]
BO_ 2566913792 DL_DataList1_00: 8 ECM
 SG_ Throttle_Position_Sensor_1 : 0|16@1+ (0.01,0) [0|654.36] "V" Vector__XXX
 SG_ Engine_Speed : 16|16@1+ (1,0) [0|65535] "rpm" Vector__XXX
 SG_ Engine_Temperature_Sensor : 32|8@1+ (0.025,0) [0|5.4] "V" Vector__XXX
 SG_ Manifold_Absolute_Pressure_Senso : 40|8@1+ (0.025,0) [0|5.4] "V" Vector__XXX
 SG_ Intake_Air_Temperature_Sensor : 48|8@1+ (0.025,0) [0|5.4] "V" Vector__XXX
 SG_ Vehicle_Electric_Power : 56|8@1+ (0.1,0) [0|24.6] "V" Vector__XXX

BO_ 2566776064 MVS_00: 8 ECM
 SG_ Maximum_Vehicle_Speed_Limit_6 : 40|8@1+ (1,0) [0|255] "km/h" Vector__XXX
 SG_ Applied_Vehicle_Speed_Limit : 56|8@1+ (1,0) [0|255] "km/h" Vector__XXX
 SG_ Maximum_Vehicle_Speed_Limit_5 : 32|8@1+ (1,0) [0|255] "km/h" Vector__XXX
 SG_ Maximum_Vehicle_Speed_Limit_4 : 24|8@1+ (1,0) [0|255] "km/h" Vector__XXX
 SG_ Maximum_Vehicle_Speed_Limit_1 : 0|8@1+ (1,0) [0|255] "km/h" Vector__XXX
 SG_ Maximum_Vehicle_Speed_Limit_2 : 8|8@1+ (1,0) [0|255] "km/h" Vector__XXX
 SG_ Maximum_Vehicle_Speed_Limit_7 : 48|8@1+ (1,0) [0|255] "km/h" Vector__XXX
 SG_ Maximum_Vehicle_Speed_Limit_3 : 16|8@1+ (1,0) [0|255] "km/h" Vector__XXX

BO_ 2566905088 DL_Datalist_21_00: 8 ECM
 SG_ cylinder_0_weighted_misfire_coun : 0|16@1+ (0,0) [0|-1] "value" Vector__XXX
 SG_ cylinder_1_weighted_misfire_coun : 16|16@1+ (0,0) [0|-1] "value" Vector__XXX
 SG_ cylinder_2_weighted_misfire_coun : 32|16@1+ (0,0) [0|-1] "value" Vector__XXX
 SG_ cylinder_3_weighted_misfire_coun : 48|16@1+ (0,0) [0|-1] "value" Vector__XXX

BO_ 2566838784 DL_Software_Ident_00: 0 ECM

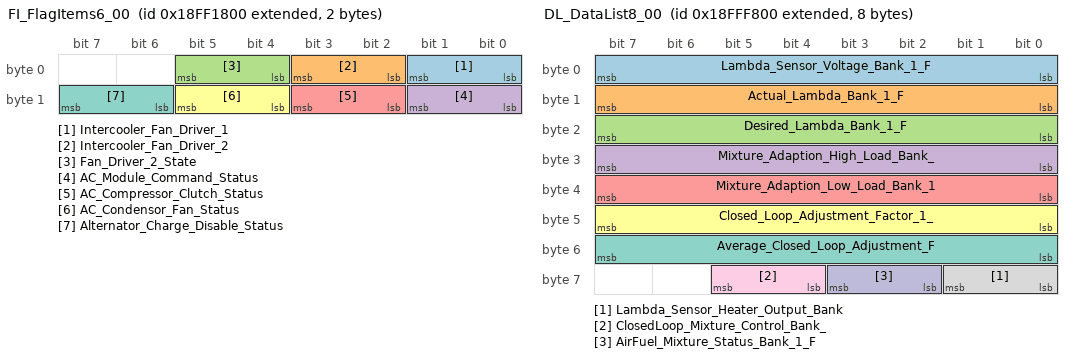
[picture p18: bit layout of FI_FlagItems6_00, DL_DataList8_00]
BO_ 2566854656 FI_FlagItems6_00: 2 ECM
 SG_ Intercooler_Fan_Driver_1 : 0|2@1+ (1,0) [0|3] "state" Vector__XXX
 SG_ Intercooler_Fan_Driver_2 : 2|2@1+ (1,0) [0|3] "state" Vector__XXX
 SG_ Fan_Driver_2_State : 4|2@1+ (1,0) [0|3] "state" Vector__XXX
 SG_ AC_Module_Command_Status : 8|2@1+ (1,0) [0|3] "state" Vector__XXX
 SG_ AC_Compressor_Clutch_Status : 10|2@1+ (1,0) [0|3] "state" Vector__XXX
 SG_ AC_Condensor_Fan_Status : 12|2@1+ (1,0) [0|3] "state" Vector__XXX
 SG_ Alternator_Charge_Disable_Status : 14|2@1+ (1,0) [0|3] "state" Vector__XXX

BO_ 2566912000 DL_DataList8_00: 8 ECM
 SG_ Lambda_Sensor_Voltage_Bank_1_F : 0|8@1+ (0.02,0) [0|4.12] "V" Vector__XXX
 SG_ Actual_Lambda_Bank_1_F : 8|8@1+ (0.0078125,0) [0|1] "Ratio" Vector__XXX
 SG_ Desired_Lambda_Bank_1_F : 16|8@1+ (0.0078125,0) [0|1] "Ratio" Vector__XXX
 SG_ Mixture_Adaption_High_Load_Bank_ : 24|8@1+ (0.0078125,0) [0|1] "unknown" Vector__XXX
 SG_ Mixture_Adaption_Low_Load_Bank_1 : 32|8@1+ (0.078,-10) [-10|28.968] "%" Vector__XXX
 SG_ Closed_Loop_Adjustment_Factor_1_ : 40|8@1+ (0.0078125,0) [0|1] "Ratio" Vector__XXX
 SG_ Average_Closed_Loop_Adjustment_F : 48|8@1+ (0.0078125,0) [0|1] "Ratio" Vector__XXX
 SG_ Lambda_Sensor_Heater_Output_Bank : 56|2@1+ (0,0) [0|-1] "state" Vector__XXX
 SG_ ClosedLoop_Mixture_Control_Bank_ : 60|2@1+ (0,0) [0|-1] "state" Vector__XXX
 SG_ AirFuel_Mixture_Status_Bank_1_F : 58|2@1+ (0,0) [0|-1] "state" Vector__XXX

BO_ 2566910976 FI_FlagItems2_00: 8 ECM
 SG_ ADC_Output : 0|2@1+ (1,0) [0|3] "state" Vector__XXX
 SG_ Turf_Mode_Output_diff_unlocked : 2|2@1+ (1,0) [0|3] "state" Vector__XXX
 SG_ AWD_Output : 4|2@1+ (1,0) [0|3] "state" Vector__XXX
 SG_ Brake_Switch_1_Input : 8|2@1+ (1,0) [0|3] "state" Vector__XXX
 SG_ ADC_Switch_Input : 10|2@1+ (1,0) [0|3] "state" Vector__XXX
 SG_ Turf_Mode_Input : 12|2@1+ (1,0) [0|3] "state" Vector__XXX
 SG_ AWD_Switch_Input : 14|2@1+ (1,0) [0|3] "state" Vector__XXX
 SG_ Reverse_Switch_Input : 16|2@1+ (1,0) [0|3] "state" Vector__XXX
 SG_ Reverse_Limit_Switch_Input : 18|2@1+ (1,0) [0|3] "state" Vector__XXX
 SG_ Forward_Limit_Switch_Input : 20|2@1+ (1,0) [0|3] "state" Vector__XXX
 SG_ Engine_Direction : 22|2@1+ (1,0) [0|3] "state" Vector__XXX
 SG_ Reverse_Speed_Limit_Override_Inp : 24|2@1+ (1,0) [0|3] "state" Vector__XXX
 SG_ Reverse_Overspeed_Signal : 26|2@1+ (1,0) [0|3] "state" Vector__XXX
 SG_ Reverse_Motor_Drive_Input : 28|2@1+ (1,0) [0|3] "state" Vector__XXX
 SG_ Low_Range_Switch_Input : 30|2@1+ (1,0) [0|3] "state" Vector__XXX
 SG_ Right_Turn_Signal_Input : 32|2@1+ (1,0) [0|3] "state" Vector__XXX
 SG_ Left_Turn_Signal_Input : 34|2@1+ (1,0) [0|3] "state" Vector__XXX
 SG_ Park_Brake_Switch_Input : 36|2@1+ (1,0) [0|3] "state" Vector__XXX
 SG_ PTO_Engagement_Status : 38|2@1+ (1,0) [0|3] "state" Vector__XXX
 SG_ Kickstand_Switch_Input : 40|2@1+ (1,0) [0|3] "state" Vector__XXX
 SG_ System_On_Input : 42|2@1+ (1,0) [0|3] "state" Vector__XXX
 SG_ Neutral_Switch_Input : 44|2@1+ (1,0) [0|3] "state" Vector__XXX
 SG_ Throttle_Limphome_Operation_Cond : 46|2@1+ (1,0) [0|3] "state" Vector__XXX
 SG_ Reflash_Enable_Input_Signal : 48|2@1+ (1,0) [0|3] "state" Vector__XXX
 SG_ TPS_Learn_Input_Signal : 50|2@1+ (1,0) [0|3] "state" Vector__XXX
 SG_ Throttle_Body_Initialization__Le : 52|2@1+ (1,0) [0|3] "bit" Vector__XXX
 SG_ Throttle_Body_Initialization__Le : 54|2@1+ (1,0) [0|3] "bit" Vector__XXX
 SG_ Safety_Fuel_Cutoff_Condition : 56|2@1+ (1,0) [0|3] "state" Vector__XXX
 SG_ Reversible_Injection_Cutoff_Cond : 58|2@1+ (1,0) [0|3] "state" Vector__XXX
 SG_ Irreversible_Injection_Cutoff_Co : 60|2@1+ (1,0) [0|3] "state" Vector__XXX
 SG_ ETC_Function_Monitoring_Irrevers : 62|2@1+ (1,0) [0|3] "state" Vector__XXX

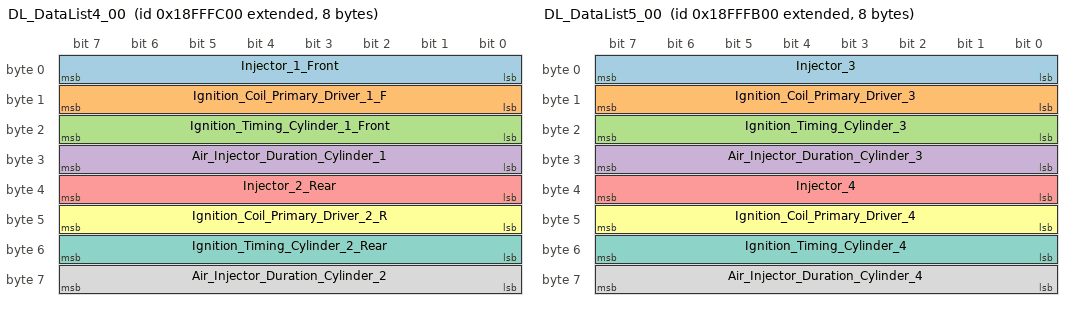
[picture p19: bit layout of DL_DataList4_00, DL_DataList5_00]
BO_ 2566913024 DL_DataList4_00: 8 ECM
 SG_ Injector_1_Front : 0|8@1+ (1,0) [0|255] "ms" Vector__XXX
 SG_ Ignition_Coil_Primary_Driver_1_F : 8|8@1+ (0.1,0) [0|24.6] "ms" Vector__XXX
 SG_ Ignition_Timing_Cylinder_1_Front : 16|8@1+ (1,0) [0|255] "deg" Vector__XXX
 SG_ Air_Injector_Duration_Cylinder_1 : 24|8@1+ (1,0) [0|255] "ms" Vector__XXX
 SG_ Injector_2_Rear : 32|8@1+ (1,0) [0|255] "ms" Vector__XXX
 SG_ Ignition_Coil_Primary_Driver_2_R : 40|8@1+ (0.1,0) [0|24.6] "ms" Vector__XXX
 SG_ Ignition_Timing_Cylinder_2_Rear : 48|8@1+ (1,0) [0|255] "deg" Vector__XXX
 SG_ Air_Injector_Duration_Cylinder_2 : 56|8@1+ (1,0) [0|255] "ms" Vector__XXX

BO_ 2566912768 DL_DataList5_00: 8 ECM
 SG_ Injector_3 : 0|8@1+ (1,0) [0|255] "ms" Vector__XXX
 SG_ Ignition_Coil_Primary_Driver_3 : 8|8@1+ (0.1,0) [0|24.6] "ms" Vector__XXX
 SG_ Ignition_Timing_Cylinder_3 : 16|8@1+ (1,0) [0|255] "deg" Vector__XXX
 SG_ Air_Injector_Duration_Cylinder_3 : 24|8@1+ (1,0) [0|255] "ms" Vector__XXX
 SG_ Injector_4 : 32|8@1+ (1,0) [0|255] "ms" Vector__XXX
 SG_ Ignition_Coil_Primary_Driver_4 : 40|8@1+ (0.1,0) [0|24.6] "ms" Vector__XXX
 SG_ Ignition_Timing_Cylinder_4 : 48|8@1+ (1,0) [0|255] "deg" Vector__XXX
 SG_ Air_Injector_Duration_Cylinder_4 : 56|8@1+ (1,0) [0|255] "ms" Vector__XXX

CM_ BO_ 2365526259 "Name: pTraction Battery Status Message
Description: Parsed from -014. ";
CM_ SG_ 2365526259 pSOH "Description: The State of Health (SOH) &ndash; percent of the battery&rsquo;s nominal capacity remaining due to aging effects &ndash; of the battery pack monitored by the Battery Management Controller (BMC).

Could not parse SPN data type, please ";
CM_ SG_ 2365526259 pBattery_Temp_Max "Description: The maximum temperature of the battery pack monitored by the Battery Management Controller (BMC).

Could not parse SPN data type, please add:Type: Measured
Parsed from -014. ";
CM_ SG_ 2365526259 pK_battemp "Description: The percent of energy capacity at 25&deg;C and current State of Health (SOH) that is available at useful discharge rates at the current battery temperature of the battery pack monitored by the Battery Management Controller (BMC).
";
CM_ SG_ 2365526259 pFloat_State "Description: The status bits indicating the electrolyte level of the battery pack monitored by the Battery Management Controller (BMC). ";
CM_ SG_ 2365526259 pBattery_Temp_Min "Description: The minimum temperature of the battery pack monitored by the Battery Management Controller (BMC).

Could not parse SPN data type, please add:Type: Measured
Parsed from -014. ";
CM_ SG_ 2365526259 pTraction_Battery_Status_Message "Description: Checksum is calculated by taking XOR of bytes from 1 to 7.
Could not parse SPN data type, please add:Type: Status
Parsed from -014. ";
CM_ BO_ 2566846451 "Name: Vehicle Electrical Power 1
Description: Parsed from -014. ";
CM_ SG_ 2566846451 Key_Switch_Battery_Potential "Description:Battery potential measured at the input of the electronic control unit supplied through a key switch or similar switching device.
Note: Parsed from J1939DA.";
CM_ SG_ 2566846451 Alternator_Current "Description:Measure of electrical current flow from the alternator. Alternator Current (High Range/Resolution) parameter SPN 1795 has a higher range and resolution of the same parameter.
Note: Parsed from J1939DA.";
CM_ SG_ 2566846451 Charging_System_Potential_Voltag "Description:Electrical potential measured at the charging system output. The charging system may be any device charging the batteries. This includes alternators, generators, solid state charger and other charging devices.";
CM_ SG_ 2566846451 SLI_Battery_1_Net_Current "Description:Net flow of electrical current into/out of the first battery or first set of batteries used for starting the engine, for lighting, and for ignition (SLI). If more than one battery is included in the first set of batt";
CM_ SG_ 2566846451 Battery_Potential__Power_Input_1 "Description:This parameter measures the first source of battery potential as measured at the input of the ECU/actuator etc. coming from one or more batteries, irrespective of the distance between the component and the bat";
CM_ BO_ 2365526771 "Name: pCharger Status Message
Description: Parsed from -014. ";
CM_ SG_ 2365526771 pCharger_Temp "Description: The temperature of the battery charger.

Could not parse SPN data type, please add:Type: Measured
Parsed from -014. ";
CM_ SG_ 2365526771 pCharger_Voltage "Description: The voltage output of the battery charger.

Could not parse SPN data type, please add:Type: Measured
Parsed from -014. ";
CM_ SG_ 2365526771 pCharger_Status_Counter "Description: Counter to verify latest message, counts 0-15

Could not parse SPN data type, please add:Type: Measured
Parsed from -014. ";
CM_ SG_ 2365526771 pCharger_State "Description: State of the battery charging process.  ";
CM_ SG_ 2365526771 pCharger_Status_Message_Checksum "Description: Checksum is calculated by taking XOR of bytes from 1 to 7.
Could not parse SPN data type, please add:Type: Status
Parsed from -014. ";
CM_ SG_ 2365526771 pAC_Status "Description: State signifying the presence of an AC Supply on the battery charger. ";
CM_ SG_ 2365526771 pCharger_Current "Description: The output current of the battery charger.

Could not parse SPN data type, please add:Type: Measured
Parsed from -014. ";
CM_ BO_ 2297441780 "Name: Acceleration Sensor
Description: The acceleration sensor message shall provide a measurement of the vehicle�s acceleration in the lateral, longitudinal, and vertical axes. The vehicle dynamics and measurements in this message shall be according to";
CM_ SG_ 2297441780 Vertical_Acceleration_Figure_of_ "Description:Figure of merit for vertical acceleration measurement. 00b = vertical acceleration is fully functional. Data is within sensor specification 01b = verticalacceleration is degraded. Data is suspect due to enviro";
CM_ SG_ 2297441780 Lateral_Acceleration_Figure_of_M "Description:Figure of merit for lateral acceleration measurement. 00b = lateral acceleration is fully functional. Data is within sensor specification 01b = lateral acceleration is degraded. Data is suspect due to envirome";
CM_ SG_ 2297441780 Longitudinal_Acceleration_Extend "Description:Indicates longitudinal acceleration of the vehicle (the component of vehicle acceleration vector along the X-axis). A positive longitudinal acceleration signal results when the vehicle speed increases in the f";
CM_ SG_ 2297441780 Lateral_Acceleration_Extended_Ra "Description:Indicates lateral acceleration of the vehicle (the component of vehicle acceleration vector along the Y-axis). A positive lateral acceleration signal results when the vehicle is accelerated to the left. This p";
CM_ SG_ 2297441780 Longitudinal_Acceleration_Figure "Description:Figure of merit for longitudinal acceleration measurement. 00b = longitudinal acceleration is fully functional. Data is within sensor specification 01b = longitudinal acceleration is degraded. Data is suspect ";
CM_ SG_ 2297441780 Vertical_Acceleration_Extended_R "Description:Indicates vertical acceleration of the vehicle and the effect of gravity (the component of vehicle acceleration vector along the Z-axis). A positive vertical acceleration signal of 1 gravity results when the v";
CM_ SG_ 2297441780 Support_Variable_Transmission_Re "Description:Indicates which acceleration transmission rate are supported by the ECU in addition to the required 10 ms transmission rate. 00 = Reserve for SAE assignment 01 = Reserved for SAE assignment 10 to 20 = ms rate ";
CM_ BO_ 2365526004 "Name: pEnergy Message
Description: Parsed from -014. ";
CM_ SG_ 2365526004 pSOC "Description: The State of Charge (SOC) &ndash; percent of battery capacity available at current battery health and temperature &ndash; of the battery pack monitored by the Battery Management Controller (BMC).

Could not parse SPN data type, please";
CM_ SG_ 2365526004 pAvailable_Wh "Description: The capacity, in Watt hours, of the battery pack monitored by the Battery Management Controller (BMC).

Could not parse SPN data type, please add:Type: Status
Parsed from -014. ";
CM_ SG_ 2365526004 pWh_in_Since_key_on "Description: The capacity in Watt hours delivered to the battery pack monitored by the Battery Management Controller (BMC), negative for net energy removed from the battery pack.

Could not parse SPN data type, please add:Type: Meas";
CM_ SG_ 2365526004 pEnergy_Message_Checksum "Description: Checksum is calculated by taking XOR of bytes from 1 to 7.
Could not parse SPN data type, please add:Type: Status
Parsed from -014. ";
CM_ BO_ 2365525748 "Name: pBMC Power Message
Description: Parsed from -014. ";
CM_ SG_ 2365525748 pPack_Voltage "Description: The voltage of the battery pack monitored by the Battery Management Controller (BMC).

Could not parse SPN data type, please add:Type: Measured
Parsed from -014. ";
CM_ SG_ 2365525748 pDischarge_Limit "Description: The discharge limit of the battery pack monitored by the Battery Management Controller (BMC).

Could not parse SPN data type, please add:Type: Status
Parsed from -014. ";
CM_ SG_ 2365525748 pPack_Current "Description: The current of the battery pack monitored by the Battery Management Controller (BMC).

Could not parse SPN data type, please add:Type: Measured
Parsed from -014. ";
CM_ SG_ 2365525748 pBMC_Power_Message_Checksum "Description: Checksum is calculated by taking XOR of bytes from 1 to 7.
Could not parse SPN data type, please add:Type: Status
Parsed from -014. ";
CM_ SG_ 2365525748 pCharge_Limit "Description: The Charge limit of the battery pack monitored by the Battery Management Controller (BMC).

Could not parse SPN data type, please add:Type: Status
Parsed from -014. ";
CM_ BO_ 2365526516 "Name: pBMC Status Message
Description: Parsed from -014. ";
CM_ SG_ 2365526516 pBMC_Temp "Description: The temperature of the Battery Management Controller (BMC).

Could not parse SPN data type, please add:Type: Measured
Parsed from -014. ";
CM_ SG_ 2365526516 pDCDC_State "Description: Operating state of the DC-DC converter controlled by the Battery Management Controller (BMC).  ";
CM_ SG_ 2365526516 pBattery_Type "Description: Type of traction battery pack installed on the vehicle
Type defined as follows:
Flooded Lead Acid 12V:       04h
Flooded Lead Acid 6V:         06h 
AGM Lead Acid 12V:           44h
AGM Lead Acid 6V:             46h
Li-Ion";
CM_ SG_ 2365526516 pBalance_Error "Description: The error in state of charge existing between the bottom battery and the top battery balanced by the Battery Management Controller (BMC). Positive error corresponds to the lower battery being at a higher state of charge.

Co";
CM_ SG_ 2365526516 pKEY_State "Description: State signifying the presence of an activated Key switch.  ";
CM_ SG_ 2365526516 pBMC_Status_Counter "Description: Counter to verify latest message, counts 0-15

Could not parse SPN data type, please add:Type: Measured
Parsed from -014. ";
CM_ SG_ 2365526516 pBalance_State "Description: The state of the BMC in terms of balancing the state of charge of the bottom battery and the top battery.  ";
CM_ SG_ 2365526516 pWAKE_State "Description: The state of the BMC&rsquo;s WAKE input.  ";
CM_ SG_ 2365526516 pBMC_Status_Message_Checksum "Description: Checksum is calculated by taking XOR of bytes from 1 to 7.
Could not parse SPN data type, please add:Type: Status
Parsed from -014. ";
CM_ BO_ 2365526260 "Name: pTraction Battery Status Message
Description: Parsed from -014. ";
CM_ SG_ 2365526260 pSOH "Description: The State of Health (SOH) &ndash; percent of the battery&rsquo;s nominal capacity remaining due to aging effects &ndash; of the battery pack monitored by the Battery Management Controller (BMC).

Could not parse SPN data type, please ";
CM_ SG_ 2365526260 pBattery_Temp_Max "Description: The maximum temperature of the battery pack monitored by the Battery Management Controller (BMC).

Could not parse SPN data type, please add:Type: Measured
Parsed from -014. ";
CM_ SG_ 2365526260 pK_battemp "Description: The percent of energy capacity at 25&deg;C and current State of Health (SOH) that is available at useful discharge rates at the current battery temperature of the battery pack monitored by the Battery Management Controller (BMC).
";
CM_ SG_ 2365526260 pFloat_State "Description: The status bits indicating the electrolyte level of the battery pack monitored by the Battery Management Controller (BMC). ";
CM_ SG_ 2365526260 pBattery_Temp_Min "Description: The minimum temperature of the battery pack monitored by the Battery Management Controller (BMC).

Could not parse SPN data type, please add:Type: Measured
Parsed from -014. ";
CM_ SG_ 2365526260 pTraction_Battery_Status_Message "Description: Checksum is calculated by taking XOR of bytes from 1 to 7.
Could not parse SPN data type, please add:Type: Status
Parsed from -014. ";
CM_ BO_ 2566846452 "Name: Vehicle Electrical Power 1
Description: Parsed from -014. ";
CM_ SG_ 2566846452 Key_Switch_Battery_Potential "Description:Battery potential measured at the input of the electronic control unit supplied through a key switch or similar switching device.
Note: Parsed from J1939DA.";
CM_ SG_ 2566846452 Alternator_Current "Description:Measure of electrical current flow from the alternator. Alternator Current (High Range/Resolution) parameter SPN 1795 has a higher range and resolution of the same parameter.
Note: Parsed from J1939DA.";
CM_ SG_ 2566846452 Charging_System_Potential_Voltag "Description:Electrical potential measured at the charging system output. The charging system may be any device charging the batteries. This includes alternators, generators, solid state charger and other charging devices.";
CM_ SG_ 2566846452 SLI_Battery_1_Net_Current "Description:Net flow of electrical current into/out of the first battery or first set of batteries used for starting the engine, for lighting, and for ignition (SLI). If more than one battery is included in the first set of batt";
CM_ SG_ 2566846452 Battery_Potential__Power_Input_1 "Description:This parameter measures the first source of battery potential as measured at the input of the ECU/actuator etc. coming from one or more batteries, irrespective of the distance between the component and the bat";
CM_ BO_ 2365526772 "Name: pCharger Status Message
Description: Parsed from -014. ";
CM_ SG_ 2365526772 pCharger_Temp "Description: The temperature of the battery charger.

Could not parse SPN data type, please add:Type: Measured
Parsed from -014. ";
CM_ SG_ 2365526772 pCharger_Voltage "Description: The voltage output of the battery charger.

Could not parse SPN data type, please add:Type: Measured
Parsed from -014. ";
CM_ SG_ 2365526772 pCharger_Status_Counter "Description: Counter to verify latest message, counts 0-15

Could not parse SPN data type, please add:Type: Measured
Parsed from -014. ";
CM_ SG_ 2365526772 pCharger_State "Description: State of the battery charging process.  ";
CM_ SG_ 2365526772 pCharger_Status_Message_Checksum "Description: Checksum is calculated by taking XOR of bytes from 1 to 7.
Could not parse SPN data type, please add:Type: Status
Parsed from -014. ";
CM_ SG_ 2365526772 pAC_Status "Description: State signifying the presence of an AC Supply on the battery charger. ";
CM_ SG_ 2365526772 pCharger_Current "Description: The output current of the battery charger.

Could not parse SPN data type, please add:Type: Measured
Parsed from -014. ";
CM_ BO_ 2298415350 "Name: pPower Message
Description: Parsed from -014. ";
CM_ SG_ 2298415350 pController_Thermal_Cutback_Stat "Description: Status bit indicating the ramp down of motor control output and subsequent vehicle performance due to the temperature of the motor controller exceeding a predefined value. ";
CM_ SG_ 2298415350 pCapacitor_Voltage "Description: Capacitor Voltage of the Electric Propulsion Control Unit or Auxiliary Power Control Unit from which the message is sent.

Could not parse SPN data type, please add:Type: Measured
Parsed from -014. ";
CM_ SG_ 2298415350 pMotor_Power_Cutback_Status "Description: Status bit indicating the ramp down of motor control output and subsequent vehicle performance due to low power availability. ";
CM_ SG_ 2298415350 pInput_Current "Description: Input DC Current of the Electric Propulsion Control Unit or Auxiliary Power Control Unit from which the message is sent.

Could not parse SPN data type, please add:Type: Measured
Parsed from -014. ";
CM_ SG_ 2298415350 pMotor_Thermal_Cutback_Status "Description: Status bit indicating the ramp down of motor control output and subsequent vehicle performance due to the temperature of the motor exceeding a predefined value. ";
CM_ SG_ 2298415350 pInput_DC_Current_Cutback_Status "Description: Status bit indicating the ramp down of motor control output and subsequent vehicle performance due to low Input Current. ";
CM_ SG_ 2298415350 pSpeed_Limit_Cutback_Status "Description: Status bit indicating the ramp down of motor control output and subsequent vehicle performance due to the motor speed exceeding the limits set for the motor.  ";
CM_ SG_ 2298415350 pPower_Message_Checksum "Description: Checksum is calculated by taking XOR of bytes from 1 to 7.
Could not parse SPN data type, please add:Type: Status
Parsed from -014. ";
CM_ BO_ 2298415606 "Name: pTemperature Message
Description: Parsed from -014. ";
CM_ SG_ 2298415606 pJunction_Temp "Description: Actual junction temperature of the Electric Propulsion Control Unit or Auxiliary Power Unit from which the message is sent

Could not parse SPN data type, please add:Type: Measured
Parsed from -014. ";
CM_ SG_ 2298415606 pCapacitor_Temp "Description: Actual capacitor temperature of the Electric Propulsion Control Unit or Auxiliary Power Unit from which the message is sent

Could not parse SPN data type, please add:Type: Measured
Parsed from -014. ";
CM_ SG_ 2298415606 pMotor_Temp_Margin "Description: The smallest difference between an internal motor component and its thermal limit for the Electric Propulsion Control Unit or Auxiliary Power Control Unit from which the message is sent

Could not parse SPN data type, pl";
CM_ SG_ 2298415606 pBaseplate_Temp "Description: Actual baseplate temperature of the Electric Propulsion Control Unit or Auxiliary Power Unit from which the message is sent

Data Length: 1 byte 
Start Position: 3.1
Type: Measured
PGN: 65289
Parsed from -014. ";
CM_ SG_ 2298415606 pBoard_Temp "Description: Board temperature of the Electric Propulsion Control Unit or Auxiliary Power Unit from which the message is sent

Could not parse SPN data type, please add:Type: Measured
Parsed from -014. ";
CM_ SG_ 2298415606 pController_Temp_Margin "Description: The smallest difference between an internal component and its thermal limit for the Electric Propulsion Control Unit or Auxiliary Power Control Unit from which the message is sent

Could not parse SPN data type, ple";
CM_ SG_ 2298415606 pTemperature_Message_Checksum "Description: Checksum is calculated by taking XOR of bytes from 1 to 7.
Could not parse SPN data type, please add:Type: Status
Parsed from -014. ";
CM_ SG_ 2298415606 pMotor_Temp "Description: Actual motor temperature of the Electric Propulsion Unit or Auxiliary Power Unit from which the message is sent

Could not parse SPN data type, please add:Type: Measured
Parsed from -014. ";
CM_ BO_ 2298415094 "Name: pPerformance Message
Description: Parsed from -014. ";
CM_ SG_ 2298415094 pPerformance_Message_Checksum "Description: Checksum is calculated by taking XOR of bytes from 1 to 7.
Could not parse SPN data type, please add:Type: Status
Parsed from -014. ";
CM_ SG_ 2298415094 pLower_Available_Torque_Limit "Description: The maximum torque available in the reverse direction. Lower available torque is normally negative but can be positive in a negative overspeed condition.

Could not parse SPN data type, please add:Type: Status";
CM_ SG_ 2298415094 pPerformance_State "Description: Bits dictating the state of the Electric Propulsion Control Unit or Auxiliary Power Unit from which the message is sent. ";
CM_ SG_ 2298415094 pActual_Motor_Torque "Description: Actual generated torque from Electronic Propulsion unit

Could not parse SPN data type, please add:Type: Status
Parsed from -014. ";
CM_ SG_ 2298415094 pUpper_Available_Torque_Limit "Description: The maximum torque available in the positive direction. Upper available torque is normally negative but can be positive in a negative overspeed condition.

Could not parse SPN data type, please add:Type: Statu";
CM_ SG_ 2298415094 pActual_Motor_Velocity "Description: Actual RPM of the Electric Propulsion Control Unit or Auxiliary Power Unit from which the message is sent.

Could not parse SPN data type, please add:Type: Measured
Parsed from -014. ";
CM_ SG_ 2298415094 pPer_Msg_Count "Description:Created due to CMS fault code using this SPN";
CM_ BO_ 2298415607 "Name: pTemperature Message
Description: Parsed from -014. ";
CM_ SG_ 2298415607 pJunction_Temp "Description: Actual junction temperature of the Electric Propulsion Control Unit or Auxiliary Power Unit from which the message is sent

Could not parse SPN data type, please add:Type: Measured
Parsed from -014. ";
CM_ SG_ 2298415607 pCapacitor_Temp "Description: Actual capacitor temperature of the Electric Propulsion Control Unit or Auxiliary Power Unit from which the message is sent

Could not parse SPN data type, please add:Type: Measured
Parsed from -014. ";
CM_ SG_ 2298415607 pMotor_Temp_Margin "Description: The smallest difference between an internal motor component and its thermal limit for the Electric Propulsion Control Unit or Auxiliary Power Control Unit from which the message is sent

Could not parse SPN data type, pl";
CM_ SG_ 2298415607 pBaseplate_Temp "Description: Actual baseplate temperature of the Electric Propulsion Control Unit or Auxiliary Power Unit from which the message is sent

Data Length: 1 byte 
Start Position: 3.1
Type: Measured
PGN: 65289
Parsed from -014. ";
CM_ SG_ 2298415607 pBoard_Temp "Description: Board temperature of the Electric Propulsion Control Unit or Auxiliary Power Unit from which the message is sent

Could not parse SPN data type, please add:Type: Measured
Parsed from -014. ";
CM_ SG_ 2298415607 pController_Temp_Margin "Description: The smallest difference between an internal component and its thermal limit for the Electric Propulsion Control Unit or Auxiliary Power Control Unit from which the message is sent

Could not parse SPN data type, ple";
CM_ SG_ 2298415607 pTemperature_Message_Checksum "Description: Checksum is calculated by taking XOR of bytes from 1 to 7.
Could not parse SPN data type, please add:Type: Status
Parsed from -014. ";
CM_ SG_ 2298415607 pMotor_Temp "Description: Actual motor temperature of the Electric Propulsion Unit or Auxiliary Power Unit from which the message is sent

Could not parse SPN data type, please add:Type: Measured
Parsed from -014. ";
CM_ BO_ 2298415095 "Name: pPerformance Message
Description: Parsed from -014. ";
CM_ SG_ 2298415095 pPerformance_Message_Checksum "Description: Checksum is calculated by taking XOR of bytes from 1 to 7.
Could not parse SPN data type, please add:Type: Status
Parsed from -014. ";
CM_ SG_ 2298415095 pLower_Available_Torque_Limit "Description: The maximum torque available in the reverse direction. Lower available torque is normally negative but can be positive in a negative overspeed condition.

Could not parse SPN data type, please add:Type: Status";
CM_ SG_ 2298415095 pPerformance_State "Description: Bits dictating the state of the Electric Propulsion Control Unit or Auxiliary Power Unit from which the message is sent. ";
CM_ SG_ 2298415095 pActual_Motor_Torque "Description: Actual generated torque from Electronic Propulsion unit

Could not parse SPN data type, please add:Type: Status
Parsed from -014. ";
CM_ SG_ 2298415095 pUpper_Available_Torque_Limit "Description: The maximum torque available in the positive direction. Upper available torque is normally negative but can be positive in a negative overspeed condition.

Could not parse SPN data type, please add:Type: Statu";
CM_ SG_ 2298415095 pActual_Motor_Velocity "Description: Actual RPM of the Electric Propulsion Control Unit or Auxiliary Power Unit from which the message is sent.

Could not parse SPN data type, please add:Type: Measured
Parsed from -014. ";
CM_ SG_ 2298415095 pPer_Msg_Count "Description:Created due to CMS fault code using this SPN";
CM_ BO_ 2298415351 "Name: pPower Message
Description: Parsed from -014. ";
CM_ SG_ 2298415351 pController_Thermal_Cutback_Stat "Description: Status bit indicating the ramp down of motor control output and subsequent vehicle performance due to the temperature of the motor controller exceeding a predefined value. ";
CM_ SG_ 2298415351 pCapacitor_Voltage "Description: Capacitor Voltage of the Electric Propulsion Control Unit or Auxiliary Power Control Unit from which the message is sent.

Could not parse SPN data type, please add:Type: Measured
Parsed from -014. ";
CM_ SG_ 2298415351 pMotor_Power_Cutback_Status "Description: Status bit indicating the ramp down of motor control output and subsequent vehicle performance due to low power availability. ";
CM_ SG_ 2298415351 pInput_Current "Description: Input DC Current of the Electric Propulsion Control Unit or Auxiliary Power Control Unit from which the message is sent.

Could not parse SPN data type, please add:Type: Measured
Parsed from -014. ";
CM_ SG_ 2298415351 pMotor_Thermal_Cutback_Status "Description: Status bit indicating the ramp down of motor control output and subsequent vehicle performance due to the temperature of the motor exceeding a predefined value. ";
CM_ SG_ 2298415351 pInput_DC_Current_Cutback_Status "Description: Status bit indicating the ramp down of motor control output and subsequent vehicle performance due to low Input Current. ";
CM_ SG_ 2298415351 pSpeed_Limit_Cutback_Status "Description: Status bit indicating the ramp down of motor control output and subsequent vehicle performance due to the motor speed exceeding the limits set for the motor.  ";
CM_ SG_ 2298415351 pPower_Message_Checksum "Description: Checksum is calculated by taking XOR of bytes from 1 to 7.
Could not parse SPN data type, please add:Type: Status
Parsed from -014. ";
CM_ BO_ 2566834937 "Name: Active Diagnostic Trouble Codes
Description:DM1 provides diagnostic lamp status and Diagnostic Trouble Codes (DTCs). Together, the lamp and DTC information
convey the diagnostic condition of the transmitting electronic component to other componen";
CM_ SG_ 2566834937 Flash_Malfunction_Indicator_Lamp "Description:This parameter provides the capability to flash the MIL. For OBD systems which are required to flash the SPN for specific malfunctions shall use the “slow flash” rate. 
See J1939-73 for complete reference
Pa";
CM_ SG_ 2566834937 Malfunction_Indicator_Lamp_Statu "Description:Used to relay only emissions-related trouble code information. This lamp is only illuminated when there is an emission-related trouble code active.
See J1939-71 for complete reference

Parsed from -014.";
CM_ SG_ 2566834937 Red_Stop_Lamp_Status "Description:Used to relay trouble code information that is of a severe enough condition that it warrants stopping the vehicle.
See J1939-71 for complete reference

Parsed from -014.";
CM_ SG_ 2566834937 Amber_Warning_Lamp_Status "Description:Used to relay trouble code information that is reporting a problem with the vehicle system but the vehicle need not be immediately stopped.
See J1939-71 for complete reference

Parsed from -014.";
CM_ SG_ 2566834937 Flash_Red_Stop_Lamp_RSL "Description:This parameter provides the capability to flash the RSL.
See J1939-73 for complete reference
Parsed from -014.";
CM_ SG_ 2566834937 Flash_Amber_Warning_Lamp_AWL "Description:This parameter provides the capability to flash the AWL. 
See J1939-73 for complete reference
Parsed from -014.";
CM_ SG_ 2566834937 Flash_Protect_Lamp "Description:This parameter provides the capability to flash the protect lamp. 
See J1939-73 for complete reference
Parsed from -014.";
CM_ SG_ 2566834937 Protect_Lamp_Status "Description:Used to relay trouble code information that is reporting a problem with a vehicle system that is most probably not electronic subsystem related. For instance, engine coolant temperature is exceeding its prescribed temperat";
CM_ SG_ 2566834937 DTC_1 "Description:This signal is a combination of 4 SPNs. To decode this signal, navigate to MCS tools.
Byte: 1 bits 8-1 SPN, 8 least significant bits of SPN (most significant at bit 8, SPN 1214)
Byte: 2 bits 8-1 SPN, second byte of SPN (most significa";
CM_ SG_ 2566834937 DTC_2 "Description:This signal is a combination of 4 SPNs. To decode this signal, navigate to MCS tools.
Byte: 1 bits 8-1 SPN, 8 least significant bits of SPN (most significant at bit 8, SPN 1214)
Byte: 2 bits 8-1 SPN, second byte of SPN (most significa";
CM_ SG_ 2566834937 DTC_3 "Description:This signal is a combination of 4 SPNs. To decode this signal, navigate to MCS tools.
Byte: 1 bits 8-1 SPN, 8 least significant bits of SPN (most significant at bit 8, SPN 1214)
Byte: 2 bits 8-1 SPN, second byte of SPN (most significa";
CM_ SG_ 2566834937 DTC_4 "Description:This signal is a combination of 4 SPNs. To decode this signal, navigate to MCS tools.
Byte: 1 bits 8-1 SPN, 8 least significant bits of SPN (most significant at bit 8, SPN 1214)
Byte: 2 bits 8-1 SPN, second byte of SPN (most significa";
CM_ SG_ 2566834937 DTC_5 "Description:This signal is a combination of 4 SPNs. To decode this signal, navigate to MCS tools.
Byte: 1 bits 8-1 SPN, 8 least significant bits of SPN (most significant at bit 8, SPN 1214)
Byte: 2 bits 8-1 SPN, second byte of SPN (most significa";
CM_ SG_ 2566834937 DTC_6 "Description:This signal is a combination of 4 SPNs. To decode this signal, navigate to MCS tools.
Byte: 1 bits 8-1 SPN, 8 least significant bits of SPN (most significant at bit 8, SPN 1214)
Byte: 2 bits 8-1 SPN, second byte of SPN (most significa";
CM_ SG_ 2566834937 DTC_7 "Description:This signal is a combination of 4 SPNs. To decode this signal, navigate to MCS tools.
Byte: 1 bits 8-1 SPN, 8 least significant bits of SPN (most significant at bit 8, SPN 1214)
Byte: 2 bits 8-1 SPN, second byte of SPN (most significa";
CM_ SG_ 2566834937 DTC_8 "Description:This signal is a combination of 4 SPNs. To decode this signal, navigate to MCS tools.
Byte: 1 bits 8-1 SPN, 8 least significant bits of SPN (most significant at bit 8, SPN 1214)
Byte: 2 bits 8-1 SPN, second byte of SPN (most significa";
CM_ SG_ 2566834937 DTC_9 "Description:This signal is a combination of 4 SPNs. To decode this signal, navigate to MCS tools.
Byte: 1 bits 8-1 SPN, 8 least significant bits of SPN (most significant at bit 8, SPN 1214)
Byte: 2 bits 8-1 SPN, second byte of SPN (most significa";
CM_ SG_ 2566834937 DTC_10 "Description:This signal is a combination of 4 SPNs. To decode this signal, navigate to MCS tools.
Byte: 1 bits 8-1 SPN, 8 least significant bits of SPN (most significant at bit 8, SPN 1214)
Byte: 2 bits 8-1 SPN, second byte of SPN (most signific";
CM_ BO_ 2365523705 "Name: pModule Control Message
Description: Parsed from -014. ";
CM_ SG_ 2365523705 pModule_Control_Applied_State "Description: Indicates the requester&rsquo;s command to control wake state of other modules. Partial Wakeup and Full Wakeup are to be defined per each module.

 ";
CM_ SG_ 2365523705 pModule_Control_Command_Destinat "Description: Indicates which source address the requester is commanding. Destination address FFh is used to indicate that all source addresses should obey the Module Control Command State signal. FFFFh indicates &ldquo;no";
CM_ SG_ 2365523705 pModule_Control_Command_State "Description: Indicates the requester&rsquo;s command to control wake state of other modules. Each state to be defined per each module. ";
CM_ SG_ 2365523705 pModule_Control_Message_Checksum "Description: Message checksum that is calculated as follows:
Intermediate Checksum =
Byte1 + Byte2 + Byte3 + Byte4 + Byte5 + Byte6 + Byte7 + (8.1 Nibble & 0x0F) + Message ID Low Byte + Message ID Mid Low Byte + Message ";
CM_ BO_ 2566877689 "Name: pCluster Status 1
Description: Parsed from -014. ";
CM_ SG_ 2566877689 pTemperature_Units_Selected "Description: Active display temperature units beased on user selection or auto-configuration. ";
CM_ SG_ 2566877689 pTPMS_Learning_Status "Description: Indicates the status of the tire pressure monitoring sensor learning process. ";
CM_ SG_ 2566877689 pPressure_Units_Selected "Description: Active display pressure units beased on user selection or auto-configuration. ";
CM_ SG_ 2566877689 pHigh_Res_Trip_2_Distance "Description: Secondary distance travled during all or part of a journey.
Could not parse SPN data type, please add:Type: Measured
Parsed from -014. ";
CM_ SG_ 2566877689 pVolume_Units_Selected "Description: Active display volume units beased on user selection or auto-configuration. ";
CM_ SG_ 2566877689 pDisplay_Status "Description: Status of display. ";
CM_ SG_ 2566877689 pTime_Units_Selected "Description: Active display time units beased on user selection or auto-configuration. ";
CM_ SG_ 2566877689 pDistance_Units_Selected "Description: Active display distance units beased on user selection or auto-configuration. ";
CM_ BO_ 2566860071 "Name: pInstrument Special Message
Description: Used to command special messages for the specific LCD Display using 2 bit status SPN�s only. The intention is to command specific warnings to the user when the vehicle is in specific states determined by th";
CM_ SG_ 2566860071 pSpecial_Msg_12 "Description: SPN Grouping contain Special Instruction Messages for LCD Display. See breakdown of PGN 65325 for further definition. ";
CM_ SG_ 2566860071 pSpecial_Msg_28 "Description: SPN Grouping contain Special Instruction Messages for LCD Display. See breakdown of PGN 65325 for further definition. ";
CM_ SG_ 2566860071 pSpecial_Msg_11 "Description: SPN Grouping contain Special Instruction Messages for LCD Display. See breakdown of PGN 65325 for further definition. ";
CM_ SG_ 2566860071 pSpecial_Msg_26 "Description: SPN Grouping contain Special Instruction Messages for LCD Display. See breakdown of PGN 65325 for further definition. ";
CM_ SG_ 2566860071 pSpecial_Msg_24 "Description: SPN Grouping contain Special Instruction Messages for LCD Display. See breakdown of PGN 65325 for further definition. ";
CM_ SG_ 2566860071 pSpecial_Msg_21 "Description: SPN Grouping contain Special Instruction Messages for LCD Display. See breakdown of PGN 65325 for further definition. ";
CM_ SG_ 2566860071 pSpecial_Msg_18 "Description: SPN Grouping contain Special Instruction Messages for LCD Display. See breakdown of PGN 65325 for further definition. ";
CM_ SG_ 2566860071 pSpecial_Msg_19 "Description: SPN Grouping contain Special Instruction Messages for LCD Display. See breakdown of PGN 65325 for further definition. ";
CM_ SG_ 2566860071 pSpecial_Msg_1_Riding_with_Brake "Description: SPN Grouping contain Special Instruction Messages for LCD Display. See breakdown of PGN 65325 for further definition. ";
CM_ SG_ 2566860071 pSpecial_Msg_2_Regulator_Overhea "Description: SPN Grouping contain Special Instruction Messages for LCD Display. See breakdown of PGN 65325 for further definition. ";
CM_ SG_ 2566860071 pSpecial_Msg_3_Regulator_Overhea "Description: SPN Grouping contain Special Instruction Messages for LCD Display. See breakdown of PGN 65325 for further definition. ";
CM_ SG_ 2566860071 pSpecial_Msg_4_Regulator_Overhea "Description: SPN Grouping contain Special Instruction Messages for LCD Display. See breakdown of PGN 65325 for further definition. ";
CM_ SG_ 2566860071 pSpecial_Msg_5_Engine_Warmup_Com "Description: SPN Grouping contain Special Instruction Messages for LCD Display. See breakdown of PGN 65325 for further definition. ";
CM_ SG_ 2566860071 pSpecial_Msg_6_Engine_Knock__Mod "Description: SPN Grouping contain Special Instruction Messages for LCD Display. See breakdown of PGN 65325 for further definition. ";
CM_ SG_ 2566860071 pSpecial_Msg_8_Low_Coolant_Warni "Description: SPN Grouping contain Special Instruction Messages for LCD Display. See breakdown of PGN 65325 for further definition. ";
CM_ SG_ 2566860071 pSpecial_Msg_7_Engine_Knock__Mos "Description: SPN Grouping contain Special Instruction Messages for LCD Display. See breakdown of PGN 65325 for further definition. ";
CM_ SG_ 2566860071 pSpecial_Msg_9_Transmission_Temp "Description: SPN Grouping contain Special Instruction Messages for LCD Display. See breakdown of PGN 65325 for further definition. ";
CM_ SG_ 2566860071 pSpecial_Msg_10_Reverse_Speed_Li "Description: SPN Grouping contain Special Instruction Messages for LCD Display. See breakdown of PGN 65325 for further definition. ";
CM_ SG_ 2566860071 pSpecial_Msg_13_Belt_Burn_Warnin "Description: SPN Grouping contain Special Instruction Messages for LCD Display. See breakdown of PGN 65325 for further definition. ";
CM_ SG_ 2566860071 pSpecial_Msg_14_Park_Brake_Warni "Description: SPN Grouping contain Special Instruction Messages for LCD Display. See breakdown of PGN 65325 for further definition. ";
CM_ SG_ 2566860071 pSpecial_Msg_15_TCM_Comm_Loss "Description: SPN Grouping contain Special Instruction Messages for LCD Display. See breakdown of PGN 65325 for further definition. ";
CM_ SG_ 2566860071 pSpecial_Msg_16_TCM_Pump_Priming "Description: SPN Grouping contain Special Instruction Messages for LCD Display. See breakdown of PGN 65325 for further definition. ";
CM_ SG_ 2566860071 pSpecial_Msg_17_Request_User_to_ "Description: SPN Grouping contain Special Instruction Messages for LCD Display. See breakdown of PGN 65325 for further definition. ";
CM_ SG_ 2566860071 pSpecial_MSG_20_Fuel_Door_Open_E "Description: SPN Grouping contain Special Instruction Messages for LCD Display. See breakdown of PGN 65325 for further definition. ";
CM_ SG_ 2566860071 pSpecial_MSG_22_Clutch_Overtemp "Description: SPN Grouping contain Special Instruction Messages for LCD Display. See breakdown of PGN 65325 for further definition. ";
CM_ SG_ 2566860071 pSpecial_MSG_23_Exhaust_Valve_Ch "Description: SPN Grouping contain Special Instruction Messages for LCD Display. See breakdown of PGN 65325 for further definition. ";
CM_ SG_ 2566860071 pSpecial_MSG_25_Engine_Idle_Shut "Description: SPN Grouping contain Special Instruction Messages for LCD Display. See breakdown of PGN 65325 for further definition. ";
CM_ SG_ 2566860071 pSpecial_MSG_27_Overboost_Condit "Description: SPN Grouping contain Special Instruction Messages for LCD Display. See breakdown of PGN 65325 for further definition. ";
CM_ SG_ 2566860071 pSpecial_Msg_31_Engine_Tip_Over_ "Description: Engine Tip Over Lockout Special Message designed to indicate to the instrument cluster that an engine tip over condition is present and that the engine is currently preventing the user from starting the engin";
CM_ SG_ 2566860071 pSpecial_Msg_32_Engine_Tip_Over_ "Description: Engine Tip Over Lockout - Heal State Special Message designed to communicate to the instrument cluster that the vehicle is still currently in a engine tip over condition but is in the process of it being heal";
CM_ BO_ 2566908427 "Name: DL: DataList17
Description:";
CM_ SG_ 2566908427 Wheel_Speed_Sensor_Front_Left_or "Description:Slingshot ESP: Front Right Wheel Speed Data";
CM_ SG_ 2566908427 Wheel_Speed_Sensor_Rear_Left_or_ "Description:Slingshot ESP: Rear Wheel Speed Data";
CM_ SG_ 2566908427 ABS_Source_Voltage "Description:";
CM_ SG_ 2566908427 ABS_Pump_CommandMotor_Relay "Description:ESP: Motor relay will be switched on to make the Return flow pump run. This signal will indicate whether Motor relay is on.";
CM_ SG_ 2566908427 ABS_Brake_Switch "Description:ESP: Rawbrakestatus received from ECM node pRawBrakeStatus. This will represent whether the brake released\Pressed";
CM_ SG_ 2566908427 ABS_Failsafe_Relay "Description:Slingshot ESP: Indicated ABS functionality is not available & system is in EBD backup mode";
CM_ SG_ 2566908427 ABS_Module_Evacuation_and_Fill "Description:";
CM_ SG_ 2566908427 Red_Brake_Lamp "Description:";
CM_ SG_ 2566908427 ABS_Lamp "Description:";
CM_ SG_ 2566908427 TCS_Disabled_Lamp "Description:";
CM_ SG_ 2566908427 ESC_Disabled_Lamp "Description:";
CM_ SG_ 2566908427 ESC_Fault_Lamp_Flashing "Description:";
CM_ SG_ 2566908427 ESC_Fault_Lamp_Solid "Description:";
CM_ SG_ 2566908427 Torque_Request_to_ECM "Description:Torque reduction\increase request is placed to ECM this will be set";
CM_ SG_ 2566908427 Traction_Control_Override_Switch "Description:Slingshot ESP: Denotes whether PATA switch is pressed";
CM_ BO_ 2365530123 "Name: pTorque/Speed Control
Description: Used to request/limit torque and speed of an engine or motor. To be used with PGN 65313 and PGN 65314.
Parsed from -014. ";
CM_ SG_ 2365530123 pMessage_Counter "Description: Message counter that increments by one for each transmission from 0 to 15 and then rolls over.
Could not parse SPN data type, please add:Type: Status
Parsed from -014. ";
CM_ SG_ 2365530123 pRequested_Engine_TorqueTorque_L "Description: This is the value used when the pEngine Control Mode is in a torque request or limit mode. This value shall be ignored by the controller when pEngine Control Mode is set to No Control Request, Engine Speed Re";
CM_ SG_ 2365530123 pEngine_Control_Mode "Description: Used to tell the engine or motor controller the type of torque/speed request or limit to use. ";
CM_ SG_ 2365530123 pRequested_Engine_SpeedSpeed_Lim "Description: This is the value used when the pEngine Control Mode is in a speed request or limit mode. This value shall be ignored by the controller when pEngine Control Mode is set to No Control Request, Engine Torque Re";
CM_ SG_ 2365530123 WheelBased_Vehicle_Speed "Description:Speed of the vehicle as calculated from wheel or tailshaft speed.
Note: Parsed from J1939DA.";
CM_ SG_ 2365530123 pEngine_Control_Requestor "Description: Used to tell the engine or motor controller what function is the requestor of the torque/speed request or limit. ";
CM_ SG_ 2365530123 pMessage_Checksum "Description: Message checksum that is calculated as follows:
Intermediate Checksum =
Byte1 + Byte2 + Byte3 + Byte4 + Byte5 + Byte6 + Byte7 + (Message Counter & 0x0F) + Message ID Low Byte + Message ID Mid Low Byte + Message ID Mid Hig";
CM_ BO_ 2566879243 "Name: DL: DataList
Description:";
CM_ SG_ 2566879243 Wheel_Speed_Sensor_Front_Right "Description:";
CM_ SG_ 2566879243 Wheel_Speed_Sensor_Rear_Right "Description:";
CM_ SG_ 2566879243 Steering_Angle "Description:";
CM_ SG_ 2566879243 Yaw_Rate "Description:";
CM_ BO_ 2566878987 "Name: DL: DataList22
Description:";
CM_ SG_ 2566878987 ESP_Variation "Description:";
CM_ SG_ 2566878987 Dyno_Mode "Description:";
CM_ SG_ 2566878987 Brake_Switch_Status "Description:0000b – no brake; 0001b – one switch closed/ one open; 0010b – both switches closed ; 0011b – 1101b : reserved; 1110b –error; 1111b - unavailable";
CM_ SG_ 2566878987 Brake_Pressure_Sensor_Output "Description:";
CM_ SG_ 2566878987 Brake_Pressure_Sensor_Offset "Description:";
CM_ BO_ 2566834721 "Name: Active Diagnostic Trouble Codes
Description:DM1 provides diagnostic lamp status and Diagnostic Trouble Codes (DTCs). Together, the lamp and DTC information
convey the diagnostic condition of the transmitting electronic component to other componen";
CM_ SG_ 2566834721 Flash_Malfunction_Indicator_Lamp "Description:This parameter provides the capability to flash the MIL. For OBD systems which are required to flash the SPN for specific malfunctions shall use the “slow flash” rate. 
See J1939-73 for complete reference
Pa";
CM_ SG_ 2566834721 Malfunction_Indicator_Lamp_Statu "Description:Used to relay only emissions-related trouble code information. This lamp is only illuminated when there is an emission-related trouble code active.
See J1939-71 for complete reference

Parsed from -014.";
CM_ SG_ 2566834721 Red_Stop_Lamp_Status "Description:Used to relay trouble code information that is of a severe enough condition that it warrants stopping the vehicle.
See J1939-71 for complete reference

Parsed from -014.";
CM_ SG_ 2566834721 Amber_Warning_Lamp_Status "Description:Used to relay trouble code information that is reporting a problem with the vehicle system but the vehicle need not be immediately stopped.
See J1939-71 for complete reference

Parsed from -014.";
CM_ SG_ 2566834721 Flash_Red_Stop_Lamp_RSL "Description:This parameter provides the capability to flash the RSL.
See J1939-73 for complete reference
Parsed from -014.";
CM_ SG_ 2566834721 Flash_Amber_Warning_Lamp_AWL "Description:This parameter provides the capability to flash the AWL. 
See J1939-73 for complete reference
Parsed from -014.";
CM_ SG_ 2566834721 Flash_Protect_Lamp "Description:This parameter provides the capability to flash the protect lamp. 
See J1939-73 for complete reference
Parsed from -014.";
CM_ SG_ 2566834721 Protect_Lamp_Status "Description:Used to relay trouble code information that is reporting a problem with a vehicle system that is most probably not electronic subsystem related. For instance, engine coolant temperature is exceeding its prescribed temperat";
CM_ SG_ 2566834721 DTC_1 "Description:This signal is a combination of 4 SPNs. To decode this signal, navigate to MCS tools.
Byte: 1 bits 8-1 SPN, 8 least significant bits of SPN (most significant at bit 8, SPN 1214)
Byte: 2 bits 8-1 SPN, second byte of SPN (most significa";
CM_ SG_ 2566834721 DTC_2 "Description:This signal is a combination of 4 SPNs. To decode this signal, navigate to MCS tools.
Byte: 1 bits 8-1 SPN, 8 least significant bits of SPN (most significant at bit 8, SPN 1214)
Byte: 2 bits 8-1 SPN, second byte of SPN (most significa";
CM_ SG_ 2566834721 DTC_3 "Description:This signal is a combination of 4 SPNs. To decode this signal, navigate to MCS tools.
Byte: 1 bits 8-1 SPN, 8 least significant bits of SPN (most significant at bit 8, SPN 1214)
Byte: 2 bits 8-1 SPN, second byte of SPN (most significa";
CM_ SG_ 2566834721 DTC_4 "Description:This signal is a combination of 4 SPNs. To decode this signal, navigate to MCS tools.
Byte: 1 bits 8-1 SPN, 8 least significant bits of SPN (most significant at bit 8, SPN 1214)
Byte: 2 bits 8-1 SPN, second byte of SPN (most significa";
CM_ SG_ 2566834721 DTC_5 "Description:This signal is a combination of 4 SPNs. To decode this signal, navigate to MCS tools.
Byte: 1 bits 8-1 SPN, 8 least significant bits of SPN (most significant at bit 8, SPN 1214)
Byte: 2 bits 8-1 SPN, second byte of SPN (most significa";
CM_ SG_ 2566834721 DTC_6 "Description:This signal is a combination of 4 SPNs. To decode this signal, navigate to MCS tools.
Byte: 1 bits 8-1 SPN, 8 least significant bits of SPN (most significant at bit 8, SPN 1214)
Byte: 2 bits 8-1 SPN, second byte of SPN (most significa";
CM_ SG_ 2566834721 DTC_7 "Description:This signal is a combination of 4 SPNs. To decode this signal, navigate to MCS tools.
Byte: 1 bits 8-1 SPN, 8 least significant bits of SPN (most significant at bit 8, SPN 1214)
Byte: 2 bits 8-1 SPN, second byte of SPN (most significa";
CM_ SG_ 2566834721 DTC_8 "Description:This signal is a combination of 4 SPNs. To decode this signal, navigate to MCS tools.
Byte: 1 bits 8-1 SPN, 8 least significant bits of SPN (most significant at bit 8, SPN 1214)
Byte: 2 bits 8-1 SPN, second byte of SPN (most significa";
CM_ SG_ 2566834721 DTC_9 "Description:This signal is a combination of 4 SPNs. To decode this signal, navigate to MCS tools.
Byte: 1 bits 8-1 SPN, 8 least significant bits of SPN (most significant at bit 8, SPN 1214)
Byte: 2 bits 8-1 SPN, second byte of SPN (most significa";
CM_ SG_ 2566834721 DTC_10 "Description:This signal is a combination of 4 SPNs. To decode this signal, navigate to MCS tools.
Byte: 1 bits 8-1 SPN, 8 least significant bits of SPN (most significant at bit 8, SPN 1214)
Byte: 2 bits 8-1 SPN, second byte of SPN (most signific";
CM_ BO_ 2566856225 "Name: FI: Flag Items 7
Description:     ";
CM_ SG_ 2566856225 Switched_Power_Output_Status "Description:0 = INACTIVE 1 = ACTIVE 2 = ERROR 3 = NOT AVAILABLE";
CM_ SG_ 2566856225 K15_Output_Status "Description:0 = INACTIVE 1 = ACTIVE 2 = ERROR 3 = NOT AVAILABLE";
CM_ SG_ 2566856225 Lock_Motor_Driver_Status "Description:0 = INACTIVE 1 = ACTIVE 2 = ERROR 3 = NOT AVAILABLE";
CM_ SG_ 2566856225 Homelink_1_Output_Status "Description:0 = INACTIVE 1 = ACTIVE 2 = ERROR 3 = NOT AVAILABLE";
CM_ SG_ 2566856225 Homelink_2_Output_Status "Description:0 = INACTIVE 1 = ACTIVE 2 = ERROR 3 = NOT AVAILABLE";
CM_ SG_ 2566856225 Windshield_Output_Status "Description:0 = INACTIVE 1 = ACTIVE 2 = ERROR 3 = NOT AVAILABLE";
CM_ SG_ 2566856225 Puddle_Light_Driver_Status "Description:0 = INACTIVE 1 = ACTIVE 2 = ERROR 3 = NOT AVAILABLE";
CM_ SG_ 2566856225 Puddle_Light_Enable_Status "Description:0 = DIABLED 1 = ENABLED 2 = ERROR 3 = NOT AVAILABLE";
CM_ SG_ 2566856225 Fuel_Door_Switch_Input_Status "Description:0 = INACTIVE 1 = ACTIVE 2 = ERROR 3 = NOT AVAILABLE";
CM_ SG_ 2566856225 VCM_Location_Pin_Status "Description:0 = OPEN 1 = GND 2 = VBAT 3 = H-BRIDGE";
CM_ SG_ 2566856225 Fuel_Lock_Motor_Driver_Status "Description:0 = INACTIVE 1 = ACTIVE 2 = ERROR 3 = NOT AVAILABLE";
CM_ SG_ 2566856225 Accent_Lights_Output_Status "Description:0 = INACTIVE 1 = ACTIVE 2 = ERROR 3 = NOT AVAILABLE";
CM_ BO_ 2566860321 "Name: pDirect Lamp Control 1
Description: Used to directly control lamp states in the gauge using 3 bit status SPNs.
Parsed from -014. ";
CM_ SG_ 2566860321 pAutonomous_Available_Status "Description: Autonomous Available Status ";
CM_ SG_ 2566860321 pBrake_Failure_Lamp_Status "Description: Indicating Brake Failure (Red Circle w/ an Exclamation Mark Inside). ";
CM_ SG_ 2566860321 pBattery_Lamp_Status "Description: Battery lamp indicator status.  ";
CM_ SG_ 2566860321 pOil_Pressure_Lamp_Status "Description: 
Low Oil Pressure lamp indicator status.  ";
CM_ SG_ 2566860321 pOil_Lamp_Status "Description: Oil lamp indicator status.  ";
CM_ SG_ 2566860321 pTransmission_Lamp_Status "Description: Indicating Transmission Fault (Amber Gear w/ an Exclamation Mark Inside). ";
CM_ SG_ 2566860321 pPark_Brake_Lamp_Status "Description: Indicating Park Brake Set (Red Circle w/ a P Inside) ";
CM_ SG_ 2566860321 pHot_Lamp_Status "Description: Hot lamp indicator status.  ";
CM_ SG_ 2566860321 pHigh_Beam_Status "Description: High Beam indicator status ";
CM_ BO_ 2566882849 "Name: pVCMStatus
Description: Parsed from -014. ";
CM_ SG_ 2566882849 pVCMState "Description: Broadcasting the current operating state of the VCM.  ";
CM_ SG_ 2566882849 pFog_Light_Control_Mode "Description: User Setting for Fog Light Function
Start Position : 2.5
Type: Status
PGN: 65414
Parsed from -014. ";
CM_ SG_ 2566882849 pHeated_Grips_Control_Mode "Description: User Setting for Fog Light Function
Start Position : 
Type: Status
PGN: 65414
Parsed from -014. ";
CM_ SG_ 2566882849 pLoadShedSts "Description: Load shed level as determined by load shedding function.   ";
CM_ BO_ 2566910497 "Name: FI: FlagItems4
Description:";
CM_ SG_ 2566910497 Hazard_Switch_Input "Description:";
CM_ SG_ 2566910497 LowHigh_Beam_Input "Description:";
CM_ SG_ 2566910497 Fog_Light_Input "Description:";
CM_ SG_ 2566910497 Horn_Input "Description:";
CM_ SG_ 2566910497 High_Beam_Output "Description:";
CM_ SG_ 2566910497 Low_Beam_Output "Description:";
CM_ SG_ 2566910497 Left_Fog_Light_Output "Description:";
CM_ SG_ 2566910497 Right_Fog_Light_Output "Description:";
CM_ SG_ 2566910497 Unlock_Input "Description:";
CM_ SG_ 2566910497 Lock_Input "Description:";
CM_ SG_ 2566910497 Windsheild_Switch_Up_Input "Description:";
CM_ SG_ 2566910497 Windsheild_Switch_Down_Input "Description:";
CM_ SG_ 2566910497 Horn_Output "Description:";
CM_ SG_ 2566910497 Hazard_Light_Output "Description:";
CM_ SG_ 2566910497 Tail_Light_Output "Description:";
CM_ SG_ 2566910497 Brake_Light_Output "Description:";
CM_ SG_ 2566910497 Left_Front_Turn_Signal_Output "Description:";
CM_ SG_ 2566910497 Right_Front_Turn_Signal_Output "Description:";
CM_ SG_ 2566910497 Left_Rear_Turn_Signal_Output "Description:";
CM_ SG_ 2566910497 Right_Rear_Turn_Signal_Output "Description:";
CM_ SG_ 2566910497 Secondary_Air_Valve_Output "Description:";
CM_ SG_ 2566910497 Secondary_Air_Valve_Command "Description:";
CM_ SG_ 2566910497 Heated_Grip_Heat_Increase_Switch "Description:";
CM_ SG_ 2566910497 Heated_Grip_Heat_Decrease_Switch "Description:";
CM_ SG_ 2566910497 pOperator_Button_1 "Description:";
CM_ SG_ 2566910497 pOperator_Button_2 "Description:";
CM_ SG_ 2566910497 pSide_Stand_Switch "Description:";
CM_ SG_ 2566910497 Coolant_Fluid_Level_Switch "Description:";
CM_ SG_ 2566910497 Driveline_Momentary_Left "Description:";
CM_ SG_ 2566910497 Driveline_Momentary_Right "Description:";
CM_ SG_ 2566910497 Seatbelt_Switch "Description:";
CM_ SG_ 2566910497 Brake_Fluid_Level_Switch "Description:";
CM_ BO_ 2566911632 "Name: DL: DataList10
Description:";
CM_ SG_ 2566911632 Purge_Valve_Solenoid_Output "Description:";
CM_ SG_ 2566911632 Target_Boost_Pressure "Description:";
CM_ SG_ 2566911632 Boost_Control_Valve_Duty_Cycle "Description:";
CM_ SG_ 2566911632 Boost_Temperature "Description:Offset: -40degC";
CM_ SG_ 2566911632 High_Range_Engine_Percent_Load "Description:";
CM_ SG_ 2566911632 Boost_Pressure_Sensor "Description:";
CM_ SG_ 2566911632 Boost_Temperature_Sensor "Description:";
CM_ SG_ 2566911632 Coolant_Fan_Duty_Cycle "Description:";
CM_ BO_ 2566834832 "Name: Active Diagnostic Trouble Codes
Description:DM1 provides diagnostic lamp status and Diagnostic Trouble Codes (DTCs). Together, the lamp and DTC information
convey the diagnostic condition of the transmitting electronic component to other componen";
CM_ SG_ 2566834832 Flash_Malfunction_Indicator_Lamp "Description:This parameter provides the capability to flash the MIL. For OBD systems which are required to flash the SPN for specific malfunctions shall use the “slow flash” rate. 
See J1939-73 for complete reference
Pa";
CM_ SG_ 2566834832 Malfunction_Indicator_Lamp_Statu "Description:Used to relay only emissions-related trouble code information. This lamp is only illuminated when there is an emission-related trouble code active.
See J1939-71 for complete reference

Parsed from -014.";
CM_ SG_ 2566834832 Red_Stop_Lamp_Status "Description:Used to relay trouble code information that is of a severe enough condition that it warrants stopping the vehicle.
See J1939-71 for complete reference

Parsed from -014.";
CM_ SG_ 2566834832 Amber_Warning_Lamp_Status "Description:Used to relay trouble code information that is reporting a problem with the vehicle system but the vehicle need not be immediately stopped.
See J1939-71 for complete reference

Parsed from -014.";
CM_ SG_ 2566834832 Flash_Red_Stop_Lamp_RSL "Description:This parameter provides the capability to flash the RSL.
See J1939-73 for complete reference
Parsed from -014.";
CM_ SG_ 2566834832 Flash_Amber_Warning_Lamp_AWL "Description:This parameter provides the capability to flash the AWL. 
See J1939-73 for complete reference
Parsed from -014.";
CM_ SG_ 2566834832 Flash_Protect_Lamp "Description:This parameter provides the capability to flash the protect lamp. 
See J1939-73 for complete reference
Parsed from -014.";
CM_ SG_ 2566834832 Protect_Lamp_Status "Description:Used to relay trouble code information that is reporting a problem with a vehicle system that is most probably not electronic subsystem related. For instance, engine coolant temperature is exceeding its prescribed temperat";
CM_ SG_ 2566834832 DTC_1 "Description:This signal is a combination of 4 SPNs. To decode this signal, navigate to MCS tools.
Byte: 1 bits 8-1 SPN, 8 least significant bits of SPN (most significant at bit 8, SPN 1214)
Byte: 2 bits 8-1 SPN, second byte of SPN (most significa";
CM_ SG_ 2566834832 DTC_2 "Description:This signal is a combination of 4 SPNs. To decode this signal, navigate to MCS tools.
Byte: 1 bits 8-1 SPN, 8 least significant bits of SPN (most significant at bit 8, SPN 1214)
Byte: 2 bits 8-1 SPN, second byte of SPN (most significa";
CM_ SG_ 2566834832 DTC_3 "Description:This signal is a combination of 4 SPNs. To decode this signal, navigate to MCS tools.
Byte: 1 bits 8-1 SPN, 8 least significant bits of SPN (most significant at bit 8, SPN 1214)
Byte: 2 bits 8-1 SPN, second byte of SPN (most significa";
CM_ SG_ 2566834832 DTC_4 "Description:This signal is a combination of 4 SPNs. To decode this signal, navigate to MCS tools.
Byte: 1 bits 8-1 SPN, 8 least significant bits of SPN (most significant at bit 8, SPN 1214)
Byte: 2 bits 8-1 SPN, second byte of SPN (most significa";
CM_ SG_ 2566834832 DTC_5 "Description:This signal is a combination of 4 SPNs. To decode this signal, navigate to MCS tools.
Byte: 1 bits 8-1 SPN, 8 least significant bits of SPN (most significant at bit 8, SPN 1214)
Byte: 2 bits 8-1 SPN, second byte of SPN (most significa";
CM_ SG_ 2566834832 DTC_6 "Description:This signal is a combination of 4 SPNs. To decode this signal, navigate to MCS tools.
Byte: 1 bits 8-1 SPN, 8 least significant bits of SPN (most significant at bit 8, SPN 1214)
Byte: 2 bits 8-1 SPN, second byte of SPN (most significa";
CM_ SG_ 2566834832 DTC_7 "Description:This signal is a combination of 4 SPNs. To decode this signal, navigate to MCS tools.
Byte: 1 bits 8-1 SPN, 8 least significant bits of SPN (most significant at bit 8, SPN 1214)
Byte: 2 bits 8-1 SPN, second byte of SPN (most significa";
CM_ SG_ 2566834832 DTC_8 "Description:This signal is a combination of 4 SPNs. To decode this signal, navigate to MCS tools.
Byte: 1 bits 8-1 SPN, 8 least significant bits of SPN (most significant at bit 8, SPN 1214)
Byte: 2 bits 8-1 SPN, second byte of SPN (most significa";
CM_ SG_ 2566834832 DTC_9 "Description:This signal is a combination of 4 SPNs. To decode this signal, navigate to MCS tools.
Byte: 1 bits 8-1 SPN, 8 least significant bits of SPN (most significant at bit 8, SPN 1214)
Byte: 2 bits 8-1 SPN, second byte of SPN (most significa";
CM_ SG_ 2566834832 DTC_10 "Description:This signal is a combination of 4 SPNs. To decode this signal, navigate to MCS tools.
Byte: 1 bits 8-1 SPN, 8 least significant bits of SPN (most significant at bit 8, SPN 1214)
Byte: 2 bits 8-1 SPN, second byte of SPN (most signific";
CM_ BO_ 2566856336 "Name: FI: Flag Items 7
Description:     ";
CM_ SG_ 2566856336 Switched_Power_Output_Status "Description:0 = INACTIVE 1 = ACTIVE 2 = ERROR 3 = NOT AVAILABLE";
CM_ SG_ 2566856336 K15_Output_Status "Description:0 = INACTIVE 1 = ACTIVE 2 = ERROR 3 = NOT AVAILABLE";
CM_ SG_ 2566856336 Lock_Motor_Driver_Status "Description:0 = INACTIVE 1 = ACTIVE 2 = ERROR 3 = NOT AVAILABLE";
CM_ SG_ 2566856336 Homelink_1_Output_Status "Description:0 = INACTIVE 1 = ACTIVE 2 = ERROR 3 = NOT AVAILABLE";
CM_ SG_ 2566856336 Homelink_2_Output_Status "Description:0 = INACTIVE 1 = ACTIVE 2 = ERROR 3 = NOT AVAILABLE";
CM_ SG_ 2566856336 Windshield_Output_Status "Description:0 = INACTIVE 1 = ACTIVE 2 = ERROR 3 = NOT AVAILABLE";
CM_ SG_ 2566856336 Puddle_Light_Driver_Status "Description:0 = INACTIVE 1 = ACTIVE 2 = ERROR 3 = NOT AVAILABLE";
CM_ SG_ 2566856336 Puddle_Light_Enable_Status "Description:0 = DIABLED 1 = ENABLED 2 = ERROR 3 = NOT AVAILABLE";
CM_ SG_ 2566856336 Fuel_Door_Switch_Input_Status "Description:0 = INACTIVE 1 = ACTIVE 2 = ERROR 3 = NOT AVAILABLE";
CM_ SG_ 2566856336 VCM_Location_Pin_Status "Description:0 = OPEN 1 = GND 2 = VBAT 3 = H-BRIDGE";
CM_ SG_ 2566856336 Fuel_Lock_Motor_Driver_Status "Description:0 = INACTIVE 1 = ACTIVE 2 = ERROR 3 = NOT AVAILABLE";
CM_ SG_ 2566856336 Accent_Lights_Output_Status "Description:0 = INACTIVE 1 = ACTIVE 2 = ERROR 3 = NOT AVAILABLE";
CM_ BO_ 2566910608 "Name: FI: FlagItems4
Description:";
CM_ SG_ 2566910608 Hazard_Switch_Input "Description:";
CM_ SG_ 2566910608 LowHigh_Beam_Input "Description:";
CM_ SG_ 2566910608 Fog_Light_Input "Description:";
CM_ SG_ 2566910608 Horn_Input "Description:";
CM_ SG_ 2566910608 High_Beam_Output "Description:";
CM_ SG_ 2566910608 Low_Beam_Output "Description:";
CM_ SG_ 2566910608 Left_Fog_Light_Output "Description:";
CM_ SG_ 2566910608 Right_Fog_Light_Output "Description:";
CM_ SG_ 2566910608 Unlock_Input "Description:";
CM_ SG_ 2566910608 Lock_Input "Description:";
CM_ SG_ 2566910608 Windsheild_Switch_Up_Input "Description:";
CM_ SG_ 2566910608 Windsheild_Switch_Down_Input "Description:";
CM_ SG_ 2566910608 Horn_Output "Description:";
CM_ SG_ 2566910608 Hazard_Light_Output "Description:";
CM_ SG_ 2566910608 Tail_Light_Output "Description:";
CM_ SG_ 2566910608 Brake_Light_Output "Description:";
CM_ SG_ 2566910608 Left_Front_Turn_Signal_Output "Description:";
CM_ SG_ 2566910608 Right_Front_Turn_Signal_Output "Description:";
CM_ SG_ 2566910608 Left_Rear_Turn_Signal_Output "Description:";
CM_ SG_ 2566910608 Right_Rear_Turn_Signal_Output "Description:";
CM_ SG_ 2566910608 Secondary_Air_Valve_Output "Description:";
CM_ SG_ 2566910608 Secondary_Air_Valve_Command "Description:";
CM_ SG_ 2566910608 Heated_Grip_Heat_Increase_Switch "Description:";
CM_ SG_ 2566910608 Heated_Grip_Heat_Decrease_Switch "Description:";
CM_ SG_ 2566910608 pOperator_Button_1 "Description:";
CM_ SG_ 2566910608 pOperator_Button_2 "Description:";
CM_ SG_ 2566910608 pSide_Stand_Switch "Description:";
CM_ SG_ 2566910608 Coolant_Fluid_Level_Switch "Description:";
CM_ SG_ 2566910608 Driveline_Momentary_Left "Description:";
CM_ SG_ 2566910608 Driveline_Momentary_Right "Description:";
CM_ SG_ 2566910608 Seatbelt_Switch "Description:";
CM_ SG_ 2566910608 Brake_Fluid_Level_Switch "Description:";
CM_ BO_ 2566856337 "Name: FI: Flag Items 7
Description:     ";
CM_ SG_ 2566856337 Switched_Power_Output_Status "Description:0 = INACTIVE 1 = ACTIVE 2 = ERROR 3 = NOT AVAILABLE";
CM_ SG_ 2566856337 K15_Output_Status "Description:0 = INACTIVE 1 = ACTIVE 2 = ERROR 3 = NOT AVAILABLE";
CM_ SG_ 2566856337 Lock_Motor_Driver_Status "Description:0 = INACTIVE 1 = ACTIVE 2 = ERROR 3 = NOT AVAILABLE";
CM_ SG_ 2566856337 Homelink_1_Output_Status "Description:0 = INACTIVE 1 = ACTIVE 2 = ERROR 3 = NOT AVAILABLE";
CM_ SG_ 2566856337 Homelink_2_Output_Status "Description:0 = INACTIVE 1 = ACTIVE 2 = ERROR 3 = NOT AVAILABLE";
CM_ SG_ 2566856337 Windshield_Output_Status "Description:0 = INACTIVE 1 = ACTIVE 2 = ERROR 3 = NOT AVAILABLE";
CM_ SG_ 2566856337 Puddle_Light_Driver_Status "Description:0 = INACTIVE 1 = ACTIVE 2 = ERROR 3 = NOT AVAILABLE";
CM_ SG_ 2566856337 Puddle_Light_Enable_Status "Description:0 = DIABLED 1 = ENABLED 2 = ERROR 3 = NOT AVAILABLE";
CM_ SG_ 2566856337 Fuel_Door_Switch_Input_Status "Description:0 = INACTIVE 1 = ACTIVE 2 = ERROR 3 = NOT AVAILABLE";
CM_ SG_ 2566856337 VCM_Location_Pin_Status "Description:0 = OPEN 1 = GND 2 = VBAT 3 = H-BRIDGE";
CM_ SG_ 2566856337 Fuel_Lock_Motor_Driver_Status "Description:0 = INACTIVE 1 = ACTIVE 2 = ERROR 3 = NOT AVAILABLE";
CM_ SG_ 2566856337 Accent_Lights_Output_Status "Description:0 = INACTIVE 1 = ACTIVE 2 = ERROR 3 = NOT AVAILABLE";
CM_ BO_ 2566882961 "Name: pVCMStatus
Description: Parsed from -014. ";
CM_ SG_ 2566882961 pVCMState "Description: Broadcasting the current operating state of the VCM.  ";
CM_ SG_ 2566882961 pFog_Light_Control_Mode "Description: User Setting for Fog Light Function
Start Position : 2.5
Type: Status
PGN: 65414
Parsed from -014. ";
CM_ SG_ 2566882961 pHeated_Grips_Control_Mode "Description: User Setting for Fog Light Function
Start Position : 
Type: Status
PGN: 65414
Parsed from -014. ";
CM_ SG_ 2566882961 pLoadShedSts "Description: Load shed level as determined by load shedding function.   ";
CM_ BO_ 2566834833 "Name: Active Diagnostic Trouble Codes
Description:DM1 provides diagnostic lamp status and Diagnostic Trouble Codes (DTCs). Together, the lamp and DTC information
convey the diagnostic condition of the transmitting electronic component to other componen";
CM_ SG_ 2566834833 Flash_Malfunction_Indicator_Lamp "Description:This parameter provides the capability to flash the MIL. For OBD systems which are required to flash the SPN for specific malfunctions shall use the “slow flash” rate. 
See J1939-73 for complete reference
Pa";
CM_ SG_ 2566834833 Malfunction_Indicator_Lamp_Statu "Description:Used to relay only emissions-related trouble code information. This lamp is only illuminated when there is an emission-related trouble code active.
See J1939-71 for complete reference

Parsed from -014.";
CM_ SG_ 2566834833 Red_Stop_Lamp_Status "Description:Used to relay trouble code information that is of a severe enough condition that it warrants stopping the vehicle.
See J1939-71 for complete reference

Parsed from -014.";
CM_ SG_ 2566834833 Amber_Warning_Lamp_Status "Description:Used to relay trouble code information that is reporting a problem with the vehicle system but the vehicle need not be immediately stopped.
See J1939-71 for complete reference

Parsed from -014.";
CM_ SG_ 2566834833 Flash_Red_Stop_Lamp_RSL "Description:This parameter provides the capability to flash the RSL.
See J1939-73 for complete reference
Parsed from -014.";
CM_ SG_ 2566834833 Flash_Amber_Warning_Lamp_AWL "Description:This parameter provides the capability to flash the AWL. 
See J1939-73 for complete reference
Parsed from -014.";
CM_ SG_ 2566834833 Flash_Protect_Lamp "Description:This parameter provides the capability to flash the protect lamp. 
See J1939-73 for complete reference
Parsed from -014.";
CM_ SG_ 2566834833 Protect_Lamp_Status "Description:Used to relay trouble code information that is reporting a problem with a vehicle system that is most probably not electronic subsystem related. For instance, engine coolant temperature is exceeding its prescribed temperat";
CM_ SG_ 2566834833 DTC_1 "Description:This signal is a combination of 4 SPNs. To decode this signal, navigate to MCS tools.
Byte: 1 bits 8-1 SPN, 8 least significant bits of SPN (most significant at bit 8, SPN 1214)
Byte: 2 bits 8-1 SPN, second byte of SPN (most significa";
CM_ SG_ 2566834833 DTC_2 "Description:This signal is a combination of 4 SPNs. To decode this signal, navigate to MCS tools.
Byte: 1 bits 8-1 SPN, 8 least significant bits of SPN (most significant at bit 8, SPN 1214)
Byte: 2 bits 8-1 SPN, second byte of SPN (most significa";
CM_ SG_ 2566834833 DTC_3 "Description:This signal is a combination of 4 SPNs. To decode this signal, navigate to MCS tools.
Byte: 1 bits 8-1 SPN, 8 least significant bits of SPN (most significant at bit 8, SPN 1214)
Byte: 2 bits 8-1 SPN, second byte of SPN (most significa";
CM_ SG_ 2566834833 DTC_4 "Description:This signal is a combination of 4 SPNs. To decode this signal, navigate to MCS tools.
Byte: 1 bits 8-1 SPN, 8 least significant bits of SPN (most significant at bit 8, SPN 1214)
Byte: 2 bits 8-1 SPN, second byte of SPN (most significa";
CM_ SG_ 2566834833 DTC_5 "Description:This signal is a combination of 4 SPNs. To decode this signal, navigate to MCS tools.
Byte: 1 bits 8-1 SPN, 8 least significant bits of SPN (most significant at bit 8, SPN 1214)
Byte: 2 bits 8-1 SPN, second byte of SPN (most significa";
CM_ SG_ 2566834833 DTC_6 "Description:This signal is a combination of 4 SPNs. To decode this signal, navigate to MCS tools.
Byte: 1 bits 8-1 SPN, 8 least significant bits of SPN (most significant at bit 8, SPN 1214)
Byte: 2 bits 8-1 SPN, second byte of SPN (most significa";
CM_ SG_ 2566834833 DTC_7 "Description:This signal is a combination of 4 SPNs. To decode this signal, navigate to MCS tools.
Byte: 1 bits 8-1 SPN, 8 least significant bits of SPN (most significant at bit 8, SPN 1214)
Byte: 2 bits 8-1 SPN, second byte of SPN (most significa";
CM_ SG_ 2566834833 DTC_8 "Description:This signal is a combination of 4 SPNs. To decode this signal, navigate to MCS tools.
Byte: 1 bits 8-1 SPN, 8 least significant bits of SPN (most significant at bit 8, SPN 1214)
Byte: 2 bits 8-1 SPN, second byte of SPN (most significa";
CM_ SG_ 2566834833 DTC_9 "Description:This signal is a combination of 4 SPNs. To decode this signal, navigate to MCS tools.
Byte: 1 bits 8-1 SPN, 8 least significant bits of SPN (most significant at bit 8, SPN 1214)
Byte: 2 bits 8-1 SPN, second byte of SPN (most significa";
CM_ SG_ 2566834833 DTC_10 "Description:This signal is a combination of 4 SPNs. To decode this signal, navigate to MCS tools.
Byte: 1 bits 8-1 SPN, 8 least significant bits of SPN (most significant at bit 8, SPN 1214)
Byte: 2 bits 8-1 SPN, second byte of SPN (most signific";
CM_ BO_ 2566799505 "Name: Lighting Data
Description:";
CM_ SG_ 2566799505 High_Beam_Head_Light_Data "Description:This parameter provides measured data from the tractor high beam head light lamps. 00b = De-activated 01b = Activated 10b = Fault Detected 11b = Not Available
Note: Parsed from J1939DA.";
CM_ SG_ 2566799505 Low_Beam_Head_Light_Data "Description:This parameter provides measured data from the tractor low beam head light lamps. 00b = De-activated 01b = Activated 10b = Fault Detected 11b = Not Available
Note: Parsed from J1939DA.";
CM_ SG_ 2566799505 Running_Light "Description:This parameter provides measured data from the vehicle's running lights. 00b = De-activated 01b = Activated 10b = Fault Detected 11b = Not Available
Note: Parsed from J1939DA.";
CM_ SG_ 2566799505 Left_Turn_Signal_Lights "Description:This parameter provides measured data from the tractor and attached implement left turn signal lights. 00b = De-activated 01b = Activated 10b = Fault Detected 11b = Not Available
Note: Parsed from J1939DA.";
CM_ SG_ 2566799505 Right_Turn_Signal_Lights "Description:This parameter provides measured data from the tractor and attached implement right turn signal lights. 00b = De-activated 01b = Activated 10b = Fault Detected 11b = Not Available
Note: Parsed from J1939DA.";
CM_ SG_ 2566799505 Left_Stop_Light "Description:This parameter provides measured data from the tractor and attached implement left stop lights. 00b = De-activated 01b = Activated 10b = Fault Detected 11b = Not Available
Note: Parsed from J1939DA.";
CM_ SG_ 2566799505 Right_Stop_Light "Description:This parameter provides measured data from the tractor and attached implement right stop lights. 00b = De-activated 01b = Activated 10b = Fault Detected 11b = Not Available
Note: Parsed from J1939DA.";
CM_ SG_ 2566799505 Tractor_Front_Fog_Lights "Description:This parameter provides measured data from the tractor front fog lights. 00b = De-activated 01b = Activated 10b = Fault Detected 11b = Not Available
Note: Parsed from J1939DA.";
CM_ SG_ 2566799505 Implement_OEM_Option_1_Light "Description:This parameter provides measured data from the implement OEM option 1 light. 00b = De-activated 01b = Activated 10b = Fault Detected 11b = Not Available
Note: Parsed from J1939DA.";
CM_ SG_ 2566799505 Implement_OEM_Option_2_Light "Description:This parameter provides measured data from the implement OEM option 2 light. 00b = De-activated 01b = Activated 10b = Fault Detected 11b = Not Available
Note: Parsed from J1939DA.";
CM_ BO_ 2566909952 "Name: DL: DataList11
Description:";
CM_ SG_ 2566909952 Lifetime_Engine_Running_Time_Acc "Description:";
CM_ SG_ 2566909952 Engine_Running_Time_Since_Key_On "Description:";
CM_ SG_ 2566909952 Engine_Oil_Pressure "Description:";
CM_ SG_ 2566909952 Engine_Oil_Pressure_Sensor "Description:";
CM_ SG_ 2566909952 Intercooler_Fan_Driver_1_Duty_Cy "Description:";
CM_ BO_ 2566912512 "Name: DL: DataList6
Description:";
CM_ SG_ 2566912512 Gear_RNLH3456 "Description:";
CM_ SG_ 2566912512 Rollover_Sensor "Description:";
CM_ SG_ 2566912512 Throttle_Release_Input "Description:";
CM_ SG_ 2566912512 Fuel_Type_Sensor_Voltage "Description:";
CM_ SG_ 2566912512 PTO_Speed_LSB "Description:";
CM_ SG_ 2566912512 PTO_Speed_MSB "Description:";
CM_ SG_ 2566912512 Two_Speed_Shift_Coil_Duty_Cycle "Description:";
CM_ SG_ 2566912512 Fuel_Level_Sensor_Voltage "Description:";
CM_ BO_ 2566911232 "Name: FI: FlagItems1
Description:     ";
CM_ SG_ 2566911232 Fuel_Pump_Driver_Circuit_OnOff "Description:";
CM_ SG_ 2566911232 Rollover_Switch "Description:Active = tipover/rollover detected";
CM_ SG_ 2566911232 Crankshaft_Sensor_Signal_SDI_2X "Description:";
CM_ SG_ 2566911232 Camshaft_Sensor_Signal_SDI_5X "Description:";
CM_ SG_ 2566911232 RPM_Limit_Active "Description:";
CM_ SG_ 2566911232 Idle_Switch "Description:";
CM_ SG_ 2566911232 Cycle_Synchronization "Description:";
CM_ SG_ 2566911232 Idle_Speed_Control_Status "Description:";
CM_ SG_ 2566911232 Ignition_Switch_Input "Description:";
CM_ SG_ 2566911232 RunStop_Switch_Input "Description:";
CM_ SG_ 2566911232 Start_Switch_Input "Description:";
CM_ SG_ 2566911232 Throttle_Release_Switch_Input "Description:";
CM_ SG_ 2566911232 Fan_Relay_Output "Description:";
CM_ SG_ 2566911232 Intercooler_Fan_Output "Description:";
CM_ SG_ 2566911232 Reverse_Alarm_Output "Description:";
CM_ SG_ 2566911232 Main_Relay_Output "Description:";
CM_ SG_ 2566911232 Start_Solenoid_OutputLSD "Description:Start solenoid low side drive.";
CM_ SG_ 2566911232 Ignition_Relay_Output "Description:";
CM_ SG_ 2566911232 Chassis_Relay_Output "Description:For SNO: Engine DC (EV) Relay";
CM_ SG_ 2566911232 Starter_Enable_OutputHSD "Description:When equipped(on Slingshot G4 for example) this flag item shall mirror the high side driven starter relay output.";
CM_ SG_ 2566911232 Exhaust_Valve_Output "Description:";
CM_ SG_ 2566911232 Battery_Charge_Relay_Output "Description:";
CM_ SG_ 2566911232 HeaterAccessory_Relay "Description:";
CM_ SG_ 2566911232 Intercooler_Pump_Driver_Circuit_ "Description:";
CM_ SG_ 2566911232 MIL_Lamp_Output "Description:";
CM_ SG_ 2566911232 Over_Temperature_Lamp_Output "Description:";
CM_ SG_ 2566911232 KnockDetination_Lamp_Output "Description:";
CM_ SG_ 2566911232 Clutch_Switch_Input_1BOT "Description:Clutch switch input on motorcycles. Bottom of travel clutch switch on Slingshot.";
CM_ SG_ 2566911232 Electronic_Oil_Pump_Driver_Circu "Description:";
CM_ SG_ 2566911232 Fuel_Pull_Solenoid_Status "Description:";
CM_ SG_ 2566911232 Clutch_Switch_Input_2TOT "Description:Clutch switch top of travel. For Slingshot cruise cancel and start strategy. Not used on motorcycles.";
CM_ SG_ 2566911232 Turbo_Oil_Pump_Driver_Circuit "Description:This is the indicator flag for the status of the Turbo Oil Pump Driver Circuit";
CM_ BO_ 2566904832 "Name: DL: Datalist22
Description:";
CM_ SG_ 2566904832 misfiring_detected_from_multiple "Description:";
CM_ SG_ 2566904832 cat_damaging_misfire_rate_exceed "Description:";
CM_ SG_ 2566904832 Detection_of_Misfiring_for_Fuel_ "Description:fofstat=00=learned fofstat=01=not defined fofstat=10=not learned fofstat=11=not defined";
CM_ SG_ 2566904832 statee_flag_fuel_cutoff_by_catal "Description:";
CM_ SG_ 2566904832 DMD_counter_in_exhaust_interval_ "Description:";
CM_ SG_ 2566904832 DMD_counter_in_exhaust_interval_ "Description:";
CM_ BO_ 2566913536 "Name: DL: DataList2
Description:";
CM_ SG_ 2566913536 Throttle_Position "Description:";
CM_ SG_ 2566913536 Engine_Temperature "Description:";
CM_ SG_ 2566913536 Intake_Air_Temperature "Description:";
CM_ SG_ 2566913536 Manifold_Absolute_Pressure "Description:";
CM_ SG_ 2566913536 Boost_Pressure "Description:";
CM_ SG_ 2566913536 Barometric_Pressure "Description:";
CM_ SG_ 2566913536 Vehicle_Speed "Description:";
CM_ SG_ 2566913536 Barometric_Pressure_Sensor "Description:";
CM_ BO_ 2566905856 "Name: DL: Wideband O2
Description:";
CM_ SG_ 2566905856 Actual_Lambda_Bank "Description:";
CM_ SG_ 2566905856 Desired_Lambda_Bank "Description:";
CM_ SG_ 2566905856 Actual_Lambda_Heater_Temperature "Description:";
CM_ SG_ 2566905856 Desired_Lambda_Heater_Temperatur "Description:";
CM_ SG_ 2566905856 Heater_Duty_Cycle "Description:";
CM_ SG_ 2566905856 O2_Value_LSB "Description:";
CM_ SG_ 2566905856 O2_Value_MSB "Description:";
CM_ SG_ 2566905856 Fuel_Adaptation_Active "Description:";
CM_ BO_ 2566883328 "Name: DL: Fuel Rail Press1
Description:";
CM_ SG_ 2566883328 Fuel_Temperature "Description:";
CM_ SG_ 2566883328 Fuel_Rail_Pressure_Sensor_Voltag "Description:";
CM_ SG_ 2566883328 Scaled_Fuel_Absolute_Pressure_Se "Description:";
CM_ SG_ 2566883328 Desired_Fuel_Rail_Absolute_Press "Description:";
CM_ SG_ 2566883328 Actual_Fuel_Pump_Control_PWM "Description:The PWM duty cycle that is transmitted to the fuel pump controller. This is before the transfer function is applied by the fuel pump controller";
CM_ SG_ 2566883328 Expected_Fuel_Pump_Power_PWM "Description:The expected PWM duty cycle after the transfer function has been applied by fuel pump controller.";
CM_ BO_ 2566910720 "Name: FI: FlagItems3
Description:";
CM_ SG_ 2566910720 Drive_Mode_1_Input "Description:";
CM_ SG_ 2566910720 Drive_Mode_2_Input "Description:";
CM_ SG_ 2566910720 Drive_Mode_3_Input "Description:";
CM_ SG_ 2566910720 Drive_Mode_4_Input "Description:";
CM_ SG_ 2566910720 Drive_Mode_1_Output "Description:";
CM_ SG_ 2566910720 Drive_Mode_2_Output "Description:";
CM_ SG_ 2566910720 Drive_Mode_3_Output "Description:";
CM_ SG_ 2566910720 Drive_Mode_4_Output "Description:";
CM_ SG_ 2566910720 PTO_Mode_Input "Description:";
CM_ SG_ 2566910720 PTO_Mode_Output "Description:";
CM_ SG_ 2566910720 Drivers_Net "Description:";
CM_ SG_ 2566910720 Drivers_Seatbelt "Description:";
CM_ SG_ 2566910720 Tilt_Lock_Input "Description:";
CM_ SG_ 2566910720 Work_Group_Lock_Input "Description:";
CM_ SG_ 2566910720 Operator_Presence_Input "Description:Active=Present=High Voltage";
CM_ SG_ 2566910720 Work_Mode_Input "Description:";
CM_ SG_ 2566910720 Tilt_Lock_Output "Description:Active=Locked=Solenoid Unpowered";
CM_ SG_ 2566910720 Work_Group_Lock_Output "Description:Active=Locked=Solenoid Unpowered";
CM_ SG_ 2566910720 Operator_Presence_Output "Description:Active=Present";
CM_ SG_ 2566910720 Tether_Switch_Status "Description:";
CM_ SG_ 2566910720 Foot_on_Cruise_Control_Input "Description:";
CM_ SG_ 2566910720 Cruise_Input "Description:on/off";
CM_ SG_ 2566910720 Treadle_Input "Description:Neutral = Active";
CM_ SG_ 2566910720 Cruise_Speed_SetDecel_Input "Description:";
CM_ SG_ 2566910720 Foot_on_Cruise_Control_Output "Description:";
CM_ SG_ 2566910720 Cruise_Output "Description:on/off";
CM_ SG_ 2566910720 Cruise_Control_to_Set_Speed_Outp "Description:";
CM_ SG_ 2566910720 Cruise_Control_ResumeAccel_Outpu "Description:";
CM_ SG_ 2566910720 Cruise_Control_ResumeAccel_Input "Description:";
CM_ SG_ 2566910720 Cruise_Control_Cancel_Input "Description:";
CM_ SG_ 2566910720 Brake_Switch_2_Input "Description:";
CM_ SG_ 2566910720 Oil_Pressure_Switch_Input "Description:";
CM_ BO_ 2566912256 "Name: DL: DataList7
Description:";
CM_ SG_ 2566912256 Throttle_Position_Sensor_2 "Description:";
CM_ SG_ 2566912256 Sensor_Supply_Voltage_1 "Description:DC-SDI TPS/TMAP PWR; DI = TPS1; Piranha: Fuel Pressure.TPS.TMAP";
CM_ SG_ 2566912256 Sensor_Supply_Voltage_2 "Description:DC-SDI Ground Speed Sensor PWR; DI TPS2/BAP/TMAP; Piranha: Kokusan Comm";
CM_ SG_ 2566912256 Sensor_Supply_Voltage_3 "Description:DI Ground Speed Sensor Power; Piranha: Ground Speed Sensor";
CM_ SG_ 2566912256 ECU_Output_Supply_Voltage_1 "Description:DI Ignition Supply PWR";
CM_ SG_ 2566912256 ECU_Output_Supply_Voltage_2 "Description:DC-SDI Injection Supply PWR";
CM_ SG_ 2566912256 Engine_Running_Mode "Description:SNO: do NOT display in digital wrench";
CM_ SG_ 2566912256 Fuel_Type_Selected "Description:0000 (E0) 0001 (E5) 0010 (E7) 0011 (E10) 0100 (E15) 0101 (E20) 0110 (E85) 0111 (E95) 1000F(E100)";
CM_ SG_ 2566912256 Boost_Launch_Status "Description:";
CM_ BO_ 2566913280 "Name: DL: DataList3
Description:";
CM_ SG_ 2566913280 Idle_Air_Control_Position_Step_M "Description:";
CM_ SG_ 2566913280 Desired_IAC_Position "Description:";
CM_ SG_ 2566913280 Idle_Air_Solenoid_DC_Solenoid_Sy "Description:";
CM_ SG_ 2566913280 Engine_Percent_Load_if_applicabl "Description:";
CM_ SG_ 2566913280 Idle_Target_RPM "Description:";
CM_ SG_ 2566913280 Absolute_Throttle_Percent "Description:";
CM_ SG_ 2566913280 Throttle_Position_Sensor_HR "Description:";
CM_ BO_ 2566908672 "Name: DL: DataList16
Description:";
CM_ SG_ 2566908672 Accelerator_Position_Sensor_1 "Description:";
CM_ SG_ 2566908672 Accelerator_Position_Sensor_2 "Description:";
CM_ SG_ 2566908672 Brake_Position_Sensor_1 "Description:";
CM_ SG_ 2566908672 Brake_Position_Sensor_2 "Description:";
CM_ BO_ 2566911488 "Name: DL: DataList10
Description:";
CM_ SG_ 2566911488 Purge_Valve_Solenoid_Output "Description:";
CM_ SG_ 2566911488 Target_Boost_Pressure "Description:";
CM_ SG_ 2566911488 Boost_Control_Valve_Duty_Cycle "Description:";
CM_ SG_ 2566911488 Boost_Temperature "Description:Offset: -40degC";
CM_ SG_ 2566911488 High_Range_Engine_Percent_Load "Description:";
CM_ SG_ 2566911488 Boost_Pressure_Sensor "Description:";
CM_ SG_ 2566911488 Boost_Temperature_Sensor "Description:";
CM_ SG_ 2566911488 Coolant_Fan_Duty_Cycle "Description:";
CM_ BO_ 2566910464 "Name: FI: FlagItems4
Description:";
CM_ SG_ 2566910464 Hazard_Switch_Input "Description:";
CM_ SG_ 2566910464 LowHigh_Beam_Input "Description:";
CM_ SG_ 2566910464 Fog_Light_Input "Description:";
CM_ SG_ 2566910464 Horn_Input "Description:";
CM_ SG_ 2566910464 High_Beam_Output "Description:";
CM_ SG_ 2566910464 Low_Beam_Output "Description:";
CM_ SG_ 2566910464 Left_Fog_Light_Output "Description:";
CM_ SG_ 2566910464 Right_Fog_Light_Output "Description:";
CM_ SG_ 2566910464 Unlock_Input "Description:";
CM_ SG_ 2566910464 Lock_Input "Description:";
CM_ SG_ 2566910464 Windsheild_Switch_Up_Input "Description:";
CM_ SG_ 2566910464 Windsheild_Switch_Down_Input "Description:";
CM_ SG_ 2566910464 Horn_Output "Description:";
CM_ SG_ 2566910464 Hazard_Light_Output "Description:";
CM_ SG_ 2566910464 Tail_Light_Output "Description:";
CM_ SG_ 2566910464 Brake_Light_Output "Description:";
CM_ SG_ 2566910464 Left_Front_Turn_Signal_Output "Description:";
CM_ SG_ 2566910464 Right_Front_Turn_Signal_Output "Description:";
CM_ SG_ 2566910464 Left_Rear_Turn_Signal_Output "Description:";
CM_ SG_ 2566910464 Right_Rear_Turn_Signal_Output "Description:";
CM_ SG_ 2566910464 Secondary_Air_Valve_Output "Description:";
CM_ SG_ 2566910464 Secondary_Air_Valve_Command "Description:";
CM_ SG_ 2566910464 Heated_Grip_Heat_Increase_Switch "Description:";
CM_ SG_ 2566910464 Heated_Grip_Heat_Decrease_Switch "Description:";
CM_ SG_ 2566910464 pOperator_Button_1 "Description:";
CM_ SG_ 2566910464 pOperator_Button_2 "Description:";
CM_ SG_ 2566910464 pSide_Stand_Switch "Description:";
CM_ SG_ 2566910464 Coolant_Fluid_Level_Switch "Description:";
CM_ SG_ 2566910464 Driveline_Momentary_Left "Description:";
CM_ SG_ 2566910464 Driveline_Momentary_Right "Description:";
CM_ SG_ 2566910464 Seatbelt_Switch "Description:";
CM_ SG_ 2566910464 Brake_Fluid_Level_Switch "Description:";
CM_ BO_ 2566908160 "Name: DL: DataList18
Description:";
CM_ SG_ 2566908160 Desired_Torque_Change_for_Idle_S "Description:";
CM_ SG_ 2566908160 Throttle_Angle_Mass_Flow_Correct "Description:";
CM_ SG_ 2566908160 Drag_Torque_Adaptation "Description:";
CM_ SG_ 2566908160 Throttle_Body_Learning_Step "Description:";
CM_ BO_ 2566913792 "Name: DL: DataList1
Description:";
CM_ SG_ 2566913792 Throttle_Position_Sensor_1 "Description:";
CM_ SG_ 2566913792 Engine_Speed "Description:";
CM_ SG_ 2566913792 Engine_Temperature_Sensor "Description:";
CM_ SG_ 2566913792 Manifold_Absolute_Pressure_Senso "Description:";
CM_ SG_ 2566913792 Intake_Air_Temperature_Sensor "Description:";
CM_ SG_ 2566913792 Vehicle_Electric_Power "Description:SNO: Engine DC Voltage";
CM_ BO_ 2566776064 "Name: Maximum Vehicle Speed Limit
Description: Parsed from -014. ";
CM_ SG_ 2566776064 Maximum_Vehicle_Speed_Limit_6 "Description:The highest of the six lowest vehicle speed limits
Note: Parsed from J1939DA.";
CM_ SG_ 2566776064 Applied_Vehicle_Speed_Limit "Description:The vehicle speed limit in effect. 251 (FBh) is used to indicate that a maximum vehicle speed limit is not selected. See SPN 7420 for alternate resolution.
Note: Parsed from J1939DA.";
CM_ SG_ 2566776064 Maximum_Vehicle_Speed_Limit_5 "Description:The highest of the five lowest vehicle speed limits
Note: Parsed from J1939DA.";
CM_ SG_ 2566776064 Maximum_Vehicle_Speed_Limit_4 "Description:The highest of the four lowest vehicle speed limits
Note: Parsed from J1939DA.";
CM_ SG_ 2566776064 Maximum_Vehicle_Speed_Limit_1 "Description:The lowest Maximum Vehicle Speed Limit. This value is the similar to SPN 74. However, SPN 74 was not specifically defined to convey the applied vehicle speed limit or what was possible to be applied. This new SP ";
CM_ SG_ 2566776064 Maximum_Vehicle_Speed_Limit_2 "Description:The highest of the two lowest vehicle speed limits
Note: Parsed from J1939DA.";
CM_ SG_ 2566776064 Maximum_Vehicle_Speed_Limit_7 "Description:The highest of the seven lowest vehicle speed limits
Note: Parsed from J1939DA.";
CM_ SG_ 2566776064 Maximum_Vehicle_Speed_Limit_3 "Description:The highest of the three lowest vehicle speed limits
Note: Parsed from J1939DA.";
CM_ BO_ 2566905088 "Name: DL: Datalist 21
Description:";
CM_ SG_ 2566905088 cylinder_0_weighted_misfire_coun "Description:";
CM_ SG_ 2566905088 cylinder_1_weighted_misfire_coun "Description:";
CM_ SG_ 2566905088 cylinder_2_weighted_misfire_coun "Description:";
CM_ SG_ 2566905088 cylinder_3_weighted_misfire_coun "Description:";
CM_ BO_ 2566838784 "Name: DL: Software Ident
Description:";
CM_ BO_ 2566854656 "Name: FI: FlagItems6
Description:";
CM_ SG_ 2566854656 Intercooler_Fan_Driver_1 "Description:";
CM_ SG_ 2566854656 Intercooler_Fan_Driver_2 "Description:";
CM_ SG_ 2566854656 Fan_Driver_2_State "Description:MY18 Dual Radiator Fan Output";
CM_ SG_ 2566854656 AC_Module_Command_Status "Description:00b - active/enabled 01b - inactive/disabled 10b - error 11b - not available";
CM_ SG_ 2566854656 AC_Compressor_Clutch_Status "Description:00b - active/enabled 01b - inactive/disabled 10b - error 11b - not available";
CM_ SG_ 2566854656 AC_Condensor_Fan_Status "Description:00b - active/enabled 01b - inactive/disabled 10b - error 11b - not available";
CM_ SG_ 2566854656 Alternator_Charge_Disable_Status "Description:00b - active/enabled 01b - inactive/disabled 10b - error 11b - not available";
CM_ BO_ 2566912000 "Name: DL: DataList8
Description:";
CM_ SG_ 2566912000 Lambda_Sensor_Voltage_Bank_1_F "Description:";
CM_ SG_ 2566912000 Actual_Lambda_Bank_1_F "Description:";
CM_ SG_ 2566912000 Desired_Lambda_Bank_1_F "Description:";
CM_ SG_ 2566912000 Mixture_Adaption_High_Load_Bank_ "Description:fra_w";
CM_ SG_ 2566912000 Mixture_Adaption_Low_Load_Bank_1 "Description:rka_w_msg";
CM_ SG_ 2566912000 Closed_Loop_Adjustment_Factor_1_ "Description:";
CM_ SG_ 2566912000 Average_Closed_Loop_Adjustment_F "Description:frm_w";
CM_ SG_ 2566912000 Lambda_Sensor_Heater_Output_Bank "Description:";
CM_ SG_ 2566912000 ClosedLoop_Mixture_Control_Bank_ "Description:b_lr";
CM_ SG_ 2566912000 AirFuel_Mixture_Status_Bank_1_F "Description:b_leanvk";
CM_ BO_ 2566910976 "Name: FI: FlagItems2
Description:";
CM_ SG_ 2566910976 ADC_Output "Description:";
CM_ SG_ 2566910976 Turf_Mode_Output_diff_unlocked "Description:";
CM_ SG_ 2566910976 AWD_Output "Description:";
CM_ SG_ 2566910976 Brake_Switch_1_Input "Description:";
CM_ SG_ 2566910976 ADC_Switch_Input "Description:";
CM_ SG_ 2566910976 Turf_Mode_Input "Description:";
CM_ SG_ 2566910976 AWD_Switch_Input "Description:";
CM_ SG_ 2566910976 Reverse_Switch_Input "Description:";
CM_ SG_ 2566910976 Reverse_Limit_Switch_Input "Description:";
CM_ SG_ 2566910976 Forward_Limit_Switch_Input "Description:";
CM_ SG_ 2566910976 Engine_Direction "Description:";
CM_ SG_ 2566910976 Reverse_Speed_Limit_Override_Inp "Description:";
CM_ SG_ 2566910976 Reverse_Overspeed_Signal "Description:";
CM_ SG_ 2566910976 Reverse_Motor_Drive_Input "Description:";
CM_ SG_ 2566910976 Low_Range_Switch_Input "Description:";
CM_ SG_ 2566910976 Right_Turn_Signal_Input "Description:";
CM_ SG_ 2566910976 Left_Turn_Signal_Input "Description:";
CM_ SG_ 2566910976 Park_Brake_Switch_Input "Description:";
CM_ SG_ 2566910976 PTO_Engagement_Status "Description:";
CM_ SG_ 2566910976 Kickstand_Switch_Input "Description:";
CM_ SG_ 2566910976 System_On_Input "Description:";
CM_ SG_ 2566910976 Neutral_Switch_Input "Description:";
CM_ SG_ 2566910976 Throttle_Limphome_Operation_Cond "Description:";
CM_ SG_ 2566910976 Reflash_Enable_Input_Signal "Description:";
CM_ SG_ 2566910976 TPS_Learn_Input_Signal "Description:";
CM_ SG_ 2566910976 Throttle_Body_Initialization__Le "Description:";
CM_ SG_ 2566910976 Throttle_Body_Initialization__Le "Description:";
CM_ SG_ 2566910976 Safety_Fuel_Cutoff_Condition "Description:";
CM_ SG_ 2566910976 Reversible_Injection_Cutoff_Cond "Description:";
CM_ SG_ 2566910976 Irreversible_Injection_Cutoff_Co "Description:";
CM_ SG_ 2566910976 ETC_Function_Monitoring_Irrevers "Description:";
CM_ BO_ 2566913024 "Name: DL: DataList4
Description:";
CM_ SG_ 2566913024 Injector_1_Front "Description:";
CM_ SG_ 2566913024 Ignition_Coil_Primary_Driver_1_F "Description:";
CM_ SG_ 2566913024 Ignition_Timing_Cylinder_1_Front "Description:";
CM_ SG_ 2566913024 Air_Injector_Duration_Cylinder_1 "Description:";
CM_ SG_ 2566913024 Injector_2_Rear "Description:";
CM_ SG_ 2566913024 Ignition_Coil_Primary_Driver_2_R "Description:";
CM_ SG_ 2566913024 Ignition_Timing_Cylinder_2_Rear "Description:";
CM_ SG_ 2566913024 Air_Injector_Duration_Cylinder_2 "Description:";
CM_ BO_ 2566912768 "Name: DL: DataList5
Description:";
CM_ SG_ 2566912768 Injector_3 "Description:";
CM_ SG_ 2566912768 Ignition_Coil_Primary_Driver_3 "Description:";
CM_ SG_ 2566912768 Ignition_Timing_Cylinder_3 "Description:";
CM_ SG_ 2566912768 Air_Injector_Duration_Cylinder_3 "Description:";
CM_ SG_ 2566912768 Injector_4 "Description:";
CM_ SG_ 2566912768 Ignition_Coil_Primary_Driver_4 "Description:";
CM_ SG_ 2566912768 Ignition_Timing_Cylinder_4 "Description:";
CM_ SG_ 2566912768 Air_Injector_Duration_Cylinder_4 "Description:";
BA_DEF_ SG_  "SigType" ENUM  "Default","Range","RangeSigned","ASCII","Discrete","Control","ReferencePGN","DTC","StringDelimiter","StringLength","StringLengthControl";
BA_DEF_ SG_  "GenSigEVName" STRING ;
BA_DEF_ SG_  "GenSigILSupport" ENUM  "No","Yes";
BA_DEF_ SG_  "GenSigSendType" ENUM  "Cyclic","OnWrite","OnWriteWithRepetition","OnChange","OnChangeWithRepetition","IfActive","IfActiveWithRepetition","NoSigSendType";
BA_DEF_ BO_  "GenMsgCycleTimeFast" INT 0 3600000;
BA_DEF_ BO_  "GenMsgILSupport" ENUM  "No","Yes";
BA_DEF_ BO_  "GenMsgSendType" ENUM  "cyclic","spontaneous","cyclicIfActive","spontaneousWithDelay","cyclicAndSpontaneous","cyclicAndSpontaneousWithDelay","spontaneousWithRepetition","cyclicIfActiveAndSpontaneousWD","OnRequest";
BA_DEF_ BO_  "GenMsgRequestable" INT 0 1;
BA_DEF_ BO_  "GenMsgCycleTime" INT 0 3600000;
BA_DEF_ SG_  "SPN" INT 0 524287;
BA_DEF_ BO_  "VFrameFormat" ENUM  "StandardCAN","ExtendedCAN","reserved","J1939PG";
BA_DEF_DEF_  "SigType" "Default";
BA_DEF_DEF_  "GenSigEVName" "Env@Nodename_@Signame";
BA_DEF_DEF_  "GenSigILSupport" "Yes";
BA_DEF_DEF_  "GenSigSendType" "NoSigSendType";
BA_DEF_DEF_  "GenMsgCycleTimeFast" 0;
BA_DEF_DEF_  "GenMsgILSupport" "Yes";
BA_DEF_DEF_  "GenMsgSendType" "noMsgSendType";
BA_DEF_DEF_  "GenMsgRequestable" 1;
BA_DEF_DEF_  "GenMsgCycleTime" 0;
BA_DEF_DEF_  "SPN" 0;
BA_DEF_DEF_  "VFrameFormat" "J1939PG";
BA_ "SPN" SG_ 2365526259 pSOH 524223;
BA_ "SPN" SG_ 2365526259 pBattery_Temp_Max 524224;
BA_ "SPN" SG_ 2365526259 pK_battemp 524225;
BA_ "SPN" SG_ 2365526259 pFloat_State 524226;
BA_ "SPN" SG_ 2365526259 pBattery_Temp_Min 524282;
BA_ "SPN" SG_ 2365526259 pTraction_Battery_Status_Message 524254;
BA_ "SPN" SG_ 2566846451 Key_Switch_Battery_Potential 158;
BA_ "SPN" SG_ 2566846451 Alternator_Current 115;
BA_ "SPN" SG_ 2566846451 Charging_System_Potential_Voltag 167;
BA_ "SPN" SG_ 2566846451 SLI_Battery_1_Net_Current 114;
BA_ "SPN" SG_ 2566846451 Battery_Potential__Power_Input_1 168;
BA_ "SPN" SG_ 2365526771 pCharger_Temp 524236;
BA_ "SPN" SG_ 2365526771 pCharger_Voltage 524235;
BA_ "SPN" SG_ 2365526771 pCharger_Status_Counter 524237;
BA_ "SPN" SG_ 2365526771 pCharger_State 524239;
BA_ "SPN" SG_ 2365526771 pCharger_Status_Message_Checksum 524256;
BA_ "SPN" SG_ 2365526771 pAC_Status 524238;
BA_ "SPN" SG_ 2365526771 pCharger_Current 524234;
BA_ "SPN" SG_ 2297441780 Vertical_Acceleration_Figure_of_ 5352;
BA_ "SPN" SG_ 2297441780 Lateral_Acceleration_Figure_of_M 5350;
BA_ "SPN" SG_ 2297441780 Longitudinal_Acceleration_Extend 5348;
BA_ "SPN" SG_ 2297441780 Lateral_Acceleration_Extended_Ra 5347;
BA_ "SPN" SG_ 2297441780 Longitudinal_Acceleration_Figure 5351;
BA_ "SPN" SG_ 2297441780 Vertical_Acceleration_Extended_R 5349;
BA_ "SPN" SG_ 2297441780 Support_Variable_Transmission_Re 5353;
BA_ "SPN" SG_ 2365526004 pSOC 524220;
BA_ "SPN" SG_ 2365526004 pAvailable_Wh 524221;
BA_ "SPN" SG_ 2365526004 pWh_in_Since_key_on 524222;
BA_ "SPN" SG_ 2365526004 pEnergy_Message_Checksum 524253;
BA_ "SPN" SG_ 2365525748 pPack_Voltage 524217;
BA_ "SPN" SG_ 2365525748 pDischarge_Limit 524218;
BA_ "SPN" SG_ 2365525748 pPack_Current 524216;
BA_ "SPN" SG_ 2365525748 pBMC_Power_Message_Checksum 524252;
BA_ "SPN" SG_ 2365525748 pCharge_Limit 524219;
BA_ "SPN" SG_ 2365526516 pBMC_Temp 524227;
BA_ "SPN" SG_ 2365526516 pDCDC_State 524233;
BA_ "SPN" SG_ 2365526516 pBattery_Type 520404;
BA_ "SPN" SG_ 2365526516 pBalance_Error 524228;
BA_ "SPN" SG_ 2365526516 pKEY_State 524232;
BA_ "SPN" SG_ 2365526516 pBMC_Status_Counter 524273;
BA_ "SPN" SG_ 2365526516 pBalance_State 524229;
BA_ "SPN" SG_ 2365526516 pWAKE_State 524230;
BA_ "SPN" SG_ 2365526516 pBMC_Status_Message_Checksum 524255;
BA_ "SPN" SG_ 2365526260 pSOH 524223;
BA_ "SPN" SG_ 2365526260 pBattery_Temp_Max 524224;
BA_ "SPN" SG_ 2365526260 pK_battemp 524225;
BA_ "SPN" SG_ 2365526260 pFloat_State 524226;
BA_ "SPN" SG_ 2365526260 pBattery_Temp_Min 524282;
BA_ "SPN" SG_ 2365526260 pTraction_Battery_Status_Message 524254;
BA_ "SPN" SG_ 2566846452 Key_Switch_Battery_Potential 158;
BA_ "SPN" SG_ 2566846452 Alternator_Current 115;
BA_ "SPN" SG_ 2566846452 Charging_System_Potential_Voltag 167;
BA_ "SPN" SG_ 2566846452 SLI_Battery_1_Net_Current 114;
BA_ "SPN" SG_ 2566846452 Battery_Potential__Power_Input_1 168;
BA_ "SPN" SG_ 2365526772 pCharger_Temp 524236;
BA_ "SPN" SG_ 2365526772 pCharger_Voltage 524235;
BA_ "SPN" SG_ 2365526772 pCharger_Status_Counter 524237;
BA_ "SPN" SG_ 2365526772 pCharger_State 524239;
BA_ "SPN" SG_ 2365526772 pCharger_Status_Message_Checksum 524256;
BA_ "SPN" SG_ 2365526772 pAC_Status 524238;
BA_ "SPN" SG_ 2365526772 pCharger_Current 524234;
BA_ "SPN" SG_ 2298415350 pController_Thermal_Cutback_Stat 524259;
BA_ "SPN" SG_ 2298415350 pCapacitor_Voltage 524196;
BA_ "SPN" SG_ 2298415350 pMotor_Power_Cutback_Status 524240;
BA_ "SPN" SG_ 2298415350 pInput_Current 524195;
BA_ "SPN" SG_ 2298415350 pMotor_Thermal_Cutback_Status 524260;
BA_ "SPN" SG_ 2298415350 pInput_DC_Current_Cutback_Status 524257;
BA_ "SPN" SG_ 2298415350 pSpeed_Limit_Cutback_Status 524258;
BA_ "SPN" SG_ 2298415350 pPower_Message_Checksum 524250;
BA_ "SPN" SG_ 2298415606 pJunction_Temp 524203;
BA_ "SPN" SG_ 2298415606 pCapacitor_Temp 524202;
BA_ "SPN" SG_ 2298415606 pMotor_Temp_Margin 524198;
BA_ "SPN" SG_ 2298415606 pBaseplate_Temp 524199;
BA_ "SPN" SG_ 2298415606 pBoard_Temp 524200;
BA_ "SPN" SG_ 2298415606 pController_Temp_Margin 524197;
BA_ "SPN" SG_ 2298415606 pTemperature_Message_Checksum 524251;
BA_ "SPN" SG_ 2298415606 pMotor_Temp 524201;
BA_ "SPN" SG_ 2298415094 pPerformance_Message_Checksum 524249;
BA_ "SPN" SG_ 2298415094 pLower_Available_Torque_Limit 524193;
BA_ "SPN" SG_ 2298415094 pPerformance_State 524190;
BA_ "SPN" SG_ 2298415094 pActual_Motor_Torque 524191;
BA_ "SPN" SG_ 2298415094 pUpper_Available_Torque_Limit 524192;
BA_ "SPN" SG_ 2298415094 pActual_Motor_Velocity 524194;
BA_ "SPN" SG_ 2298415094 pPer_Msg_Count 520606;
BA_ "SPN" SG_ 2298415607 pJunction_Temp 524203;
BA_ "SPN" SG_ 2298415607 pCapacitor_Temp 524202;
BA_ "SPN" SG_ 2298415607 pMotor_Temp_Margin 524198;
BA_ "SPN" SG_ 2298415607 pBaseplate_Temp 524199;
BA_ "SPN" SG_ 2298415607 pBoard_Temp 524200;
BA_ "SPN" SG_ 2298415607 pController_Temp_Margin 524197;
BA_ "SPN" SG_ 2298415607 pTemperature_Message_Checksum 524251;
BA_ "SPN" SG_ 2298415607 pMotor_Temp 524201;
BA_ "SPN" SG_ 2298415095 pPerformance_Message_Checksum 524249;
BA_ "SPN" SG_ 2298415095 pLower_Available_Torque_Limit 524193;
BA_ "SPN" SG_ 2298415095 pPerformance_State 524190;
BA_ "SPN" SG_ 2298415095 pActual_Motor_Torque 524191;
BA_ "SPN" SG_ 2298415095 pUpper_Available_Torque_Limit 524192;
BA_ "SPN" SG_ 2298415095 pActual_Motor_Velocity 524194;
BA_ "SPN" SG_ 2298415095 pPer_Msg_Count 520606;
BA_ "SPN" SG_ 2298415351 pController_Thermal_Cutback_Stat 524259;
BA_ "SPN" SG_ 2298415351 pCapacitor_Voltage 524196;
BA_ "SPN" SG_ 2298415351 pMotor_Power_Cutback_Status 524240;
BA_ "SPN" SG_ 2298415351 pInput_Current 524195;
BA_ "SPN" SG_ 2298415351 pMotor_Thermal_Cutback_Status 524260;
BA_ "SPN" SG_ 2298415351 pInput_DC_Current_Cutback_Status 524257;
BA_ "SPN" SG_ 2298415351 pSpeed_Limit_Cutback_Status 524258;
BA_ "SPN" SG_ 2298415351 pPower_Message_Checksum 524250;
BA_ "SPN" SG_ 2566834937 Flash_Malfunction_Indicator_Lamp 3038;
BA_ "SPN" SG_ 2566834937 Malfunction_Indicator_Lamp_Statu 1213;
BA_ "SPN" SG_ 2566834937 Red_Stop_Lamp_Status 623;
BA_ "SPN" SG_ 2566834937 Amber_Warning_Lamp_Status 624;
BA_ "SPN" SG_ 2566834937 Flash_Red_Stop_Lamp_RSL 3039;
BA_ "SPN" SG_ 2566834937 Flash_Amber_Warning_Lamp_AWL 3040;
BA_ "SPN" SG_ 2566834937 Flash_Protect_Lamp 3041;
BA_ "SPN" SG_ 2566834937 Protect_Lamp_Status 987;
BA_ "SPN" SG_ 2566834937 DTC_1 999990;
BA_ "SPN" SG_ 2566834937 DTC_2 999991;
BA_ "SPN" SG_ 2566834937 DTC_3 999992;
BA_ "SPN" SG_ 2566834937 DTC_4 999993;
BA_ "SPN" SG_ 2566834937 DTC_5 999994;
BA_ "SPN" SG_ 2566834937 DTC_6 999995;
BA_ "SPN" SG_ 2566834937 DTC_7 999996;
BA_ "SPN" SG_ 2566834937 DTC_8 999997;
BA_ "SPN" SG_ 2566834937 DTC_9 999998;
BA_ "SPN" SG_ 2566834937 DTC_10 999999;
BA_ "SPN" SG_ 2365523705 pModule_Control_Applied_State 516096;
BA_ "SPN" SG_ 2365523705 pModule_Control_Command_Destinat 524185;
BA_ "SPN" SG_ 2365523705 pModule_Control_Command_State 524248;
BA_ "SPN" SG_ 2365523705 pModule_Control_Message_Checksum 516097;
BA_ "SPN" SG_ 2566877689 pTemperature_Units_Selected 524266;
BA_ "SPN" SG_ 2566877689 pTPMS_Learning_Status 524104;
BA_ "SPN" SG_ 2566877689 pPressure_Units_Selected 524269;
BA_ "SPN" SG_ 2566877689 pHigh_Res_Trip_2_Distance 524264;
BA_ "SPN" SG_ 2566877689 pVolume_Units_Selected 524267;
BA_ "SPN" SG_ 2566877689 pDisplay_Status 524105;
BA_ "SPN" SG_ 2566877689 pTime_Units_Selected 524268;
BA_ "SPN" SG_ 2566877689 pDistance_Units_Selected 524265;
BA_ "SPN" SG_ 2566860071 pSpecial_Msg_12 516427;
BA_ "SPN" SG_ 2566860071 pSpecial_Msg_28 516373;
BA_ "SPN" SG_ 2566860071 pSpecial_Msg_11 516393;
BA_ "SPN" SG_ 2566860071 pSpecial_Msg_26 516465;
BA_ "SPN" SG_ 2566860071 pSpecial_Msg_24 516463;
BA_ "SPN" SG_ 2566860071 pSpecial_Msg_21 516444;
BA_ "SPN" SG_ 2566860071 pSpecial_Msg_18 516376;
BA_ "SPN" SG_ 2566860071 pSpecial_Msg_19 516442;
BA_ "SPN" SG_ 2566860071 pSpecial_Msg_1_Riding_with_Brake 516382;
BA_ "SPN" SG_ 2566860071 pSpecial_Msg_2_Regulator_Overhea 516384;
BA_ "SPN" SG_ 2566860071 pSpecial_Msg_3_Regulator_Overhea 516385;
BA_ "SPN" SG_ 2566860071 pSpecial_Msg_4_Regulator_Overhea 516386;
BA_ "SPN" SG_ 2566860071 pSpecial_Msg_5_Engine_Warmup_Com 516387;
BA_ "SPN" SG_ 2566860071 pSpecial_Msg_6_Engine_Knock__Mod 516388;
BA_ "SPN" SG_ 2566860071 pSpecial_Msg_8_Low_Coolant_Warni 516390;
BA_ "SPN" SG_ 2566860071 pSpecial_Msg_7_Engine_Knock__Mos 516389;
BA_ "SPN" SG_ 2566860071 pSpecial_Msg_9_Transmission_Temp 516391;
BA_ "SPN" SG_ 2566860071 pSpecial_Msg_10_Reverse_Speed_Li 516392;
BA_ "SPN" SG_ 2566860071 pSpecial_Msg_13_Belt_Burn_Warnin 516381;
BA_ "SPN" SG_ 2566860071 pSpecial_Msg_14_Park_Brake_Warni 516380;
BA_ "SPN" SG_ 2566860071 pSpecial_Msg_15_TCM_Comm_Loss 516379;
BA_ "SPN" SG_ 2566860071 pSpecial_Msg_16_TCM_Pump_Priming 516378;
BA_ "SPN" SG_ 2566860071 pSpecial_Msg_17_Request_User_to_ 516377;
BA_ "SPN" SG_ 2566860071 pSpecial_MSG_20_Fuel_Door_Open_E 516443;
BA_ "SPN" SG_ 2566860071 pSpecial_MSG_22_Clutch_Overtemp 516383;
BA_ "SPN" SG_ 2566860071 pSpecial_MSG_23_Exhaust_Valve_Ch 516375;
BA_ "SPN" SG_ 2566860071 pSpecial_MSG_25_Engine_Idle_Shut 516464;
BA_ "SPN" SG_ 2566860071 pSpecial_MSG_27_Overboost_Condit 516374;
BA_ "SPN" SG_ 2566860071 pSpecial_Msg_31_Engine_Tip_Over_ 516372;
BA_ "SPN" SG_ 2566860071 pSpecial_Msg_32_Engine_Tip_Over_ 516394;
BA_ "SPN" SG_ 2566908427 Wheel_Speed_Sensor_Front_Left_or 516911;
BA_ "SPN" SG_ 2566908427 Wheel_Speed_Sensor_Rear_Left_or_ 516991;
BA_ "SPN" SG_ 2566908427 ABS_Source_Voltage 516966;
BA_ "SPN" SG_ 2566908427 ABS_Pump_CommandMotor_Relay 516278;
BA_ "SPN" SG_ 2566908427 ABS_Brake_Switch 517282;
BA_ "SPN" SG_ 2566908427 ABS_Failsafe_Relay 516768;
BA_ "SPN" SG_ 2566908427 ABS_Module_Evacuation_and_Fill 516734;
BA_ "SPN" SG_ 2566908427 Red_Brake_Lamp 516763;
BA_ "SPN" SG_ 2566908427 ABS_Lamp 517068;
BA_ "SPN" SG_ 2566908427 TCS_Disabled_Lamp 516909;
BA_ "SPN" SG_ 2566908427 ESC_Disabled_Lamp 516968;
BA_ "SPN" SG_ 2566908427 ESC_Fault_Lamp_Flashing 517183;
BA_ "SPN" SG_ 2566908427 ESC_Fault_Lamp_Solid 516735;
BA_ "SPN" SG_ 2566908427 Torque_Request_to_ECM 517040;
BA_ "SPN" SG_ 2566908427 Traction_Control_Override_Switch 516905;
BA_ "SPN" SG_ 2365530123 pMessage_Counter 520564;
BA_ "SPN" SG_ 2365530123 pRequested_Engine_TorqueTorque_L 520562;
BA_ "SPN" SG_ 2365530123 pEngine_Control_Mode 520560;
BA_ "SPN" SG_ 2365530123 pRequested_Engine_SpeedSpeed_Lim 520563;
BA_ "SPN" SG_ 2365530123 WheelBased_Vehicle_Speed 84;
BA_ "SPN" SG_ 2365530123 pEngine_Control_Requestor 520561;
BA_ "SPN" SG_ 2365530123 pMessage_Checksum 520565;
BA_ "SPN" SG_ 2566879243 Wheel_Speed_Sensor_Front_Right 517265;
BA_ "SPN" SG_ 2566879243 Wheel_Speed_Sensor_Rear_Right 516514;
BA_ "SPN" SG_ 2566879243 Steering_Angle 517283;
BA_ "SPN" SG_ 2566879243 Yaw_Rate 516291;
BA_ "SPN" SG_ 2566878987 ESP_Variation 516901;
BA_ "SPN" SG_ 2566878987 Dyno_Mode 516693;
BA_ "SPN" SG_ 2566878987 Brake_Switch_Status 516904;
BA_ "SPN" SG_ 2566878987 Brake_Pressure_Sensor_Output 516523;
BA_ "SPN" SG_ 2566878987 Brake_Pressure_Sensor_Offset 516919;
BA_ "SPN" SG_ 2566834721 Flash_Malfunction_Indicator_Lamp 3038;
BA_ "SPN" SG_ 2566834721 Malfunction_Indicator_Lamp_Statu 1213;
BA_ "SPN" SG_ 2566834721 Red_Stop_Lamp_Status 623;
BA_ "SPN" SG_ 2566834721 Amber_Warning_Lamp_Status 624;
BA_ "SPN" SG_ 2566834721 Flash_Red_Stop_Lamp_RSL 3039;
BA_ "SPN" SG_ 2566834721 Flash_Amber_Warning_Lamp_AWL 3040;
BA_ "SPN" SG_ 2566834721 Flash_Protect_Lamp 3041;
BA_ "SPN" SG_ 2566834721 Protect_Lamp_Status 987;
BA_ "SPN" SG_ 2566834721 DTC_1 999990;
BA_ "SPN" SG_ 2566834721 DTC_2 999991;
BA_ "SPN" SG_ 2566834721 DTC_3 999992;
BA_ "SPN" SG_ 2566834721 DTC_4 999993;
BA_ "SPN" SG_ 2566834721 DTC_5 999994;
BA_ "SPN" SG_ 2566834721 DTC_6 999995;
BA_ "SPN" SG_ 2566834721 DTC_7 999996;
BA_ "SPN" SG_ 2566834721 DTC_8 999997;
BA_ "SPN" SG_ 2566834721 DTC_9 999998;
BA_ "SPN" SG_ 2566834721 DTC_10 999999;
BA_ "SPN" SG_ 2566856225 Switched_Power_Output_Status 517372;
BA_ "SPN" SG_ 2566856225 K15_Output_Status 517436;
BA_ "SPN" SG_ 2566856225 Lock_Motor_Driver_Status 517395;
BA_ "SPN" SG_ 2566856225 Homelink_1_Output_Status 517456;
BA_ "SPN" SG_ 2566856225 Homelink_2_Output_Status 517424;
BA_ "SPN" SG_ 2566856225 Windshield_Output_Status 517296;
BA_ "SPN" SG_ 2566856225 Puddle_Light_Driver_Status 517426;
BA_ "SPN" SG_ 2566856225 Puddle_Light_Enable_Status 517407;
BA_ "SPN" SG_ 2566856225 Fuel_Door_Switch_Input_Status 517467;
BA_ "SPN" SG_ 2566856225 VCM_Location_Pin_Status 517480;
BA_ "SPN" SG_ 2566856225 Fuel_Lock_Motor_Driver_Status 517316;
BA_ "SPN" SG_ 2566856225 Accent_Lights_Output_Status 517363;
BA_ "SPN" SG_ 2566860321 pAutonomous_Available_Status 516441;
BA_ "SPN" SG_ 2566860321 pBrake_Failure_Lamp_Status 516331;
BA_ "SPN" SG_ 2566860321 pBattery_Lamp_Status 516328;
BA_ "SPN" SG_ 2566860321 pOil_Pressure_Lamp_Status 516428;
BA_ "SPN" SG_ 2566860321 pOil_Lamp_Status 516327;
BA_ "SPN" SG_ 2566860321 pTransmission_Lamp_Status 516332;
BA_ "SPN" SG_ 2566860321 pPark_Brake_Lamp_Status 516330;
BA_ "SPN" SG_ 2566860321 pHot_Lamp_Status 516326;
BA_ "SPN" SG_ 2566860321 pHigh_Beam_Status 516429;
BA_ "SPN" SG_ 2566882849 pVCMState 523960;
BA_ "SPN" SG_ 2566882849 pFog_Light_Control_Mode 516369;
BA_ "SPN" SG_ 2566882849 pHeated_Grips_Control_Mode 516370;
BA_ "SPN" SG_ 2566882849 pLoadShedSts 516371;
BA_ "SPN" SG_ 2566910497 Hazard_Switch_Input 517413;
BA_ "SPN" SG_ 2566910497 LowHigh_Beam_Input 517402;
BA_ "SPN" SG_ 2566910497 Fog_Light_Input 517289;
BA_ "SPN" SG_ 2566910497 Horn_Input 517430;
BA_ "SPN" SG_ 2566910497 High_Beam_Output 517311;
BA_ "SPN" SG_ 2566910497 Low_Beam_Output 517381;
BA_ "SPN" SG_ 2566910497 Left_Fog_Light_Output 517337;
BA_ "SPN" SG_ 2566910497 Right_Fog_Light_Output 517293;
BA_ "SPN" SG_ 2566910497 Unlock_Input 517439;
BA_ "SPN" SG_ 2566910497 Lock_Input 517387;
BA_ "SPN" SG_ 2566910497 Windsheild_Switch_Up_Input 517334;
BA_ "SPN" SG_ 2566910497 Windsheild_Switch_Down_Input 517315;
BA_ "SPN" SG_ 2566910497 Horn_Output 517469;
BA_ "SPN" SG_ 2566910497 Hazard_Light_Output 517298;
BA_ "SPN" SG_ 2566910497 Tail_Light_Output 517420;
BA_ "SPN" SG_ 2566910497 Brake_Light_Output 517412;
BA_ "SPN" SG_ 2566910497 Left_Front_Turn_Signal_Output 517459;
BA_ "SPN" SG_ 2566910497 Right_Front_Turn_Signal_Output 517388;
BA_ "SPN" SG_ 2566910497 Left_Rear_Turn_Signal_Output 517408;
BA_ "SPN" SG_ 2566910497 Right_Rear_Turn_Signal_Output 517358;
BA_ "SPN" SG_ 2566910497 Secondary_Air_Valve_Output 517292;
BA_ "SPN" SG_ 2566910497 Secondary_Air_Valve_Command 517342;
BA_ "SPN" SG_ 2566910497 Heated_Grip_Heat_Increase_Switch 517416;
BA_ "SPN" SG_ 2566910497 Heated_Grip_Heat_Decrease_Switch 517328;
BA_ "SPN" SG_ 2566910497 pOperator_Button_1 517302;
BA_ "SPN" SG_ 2566910497 pOperator_Button_2 517401;
BA_ "SPN" SG_ 2566910497 pSide_Stand_Switch 517350;
BA_ "SPN" SG_ 2566910497 Coolant_Fluid_Level_Switch 517455;
BA_ "SPN" SG_ 2566910497 Driveline_Momentary_Left 517304;
BA_ "SPN" SG_ 2566910497 Driveline_Momentary_Right 517403;
BA_ "SPN" SG_ 2566910497 Seatbelt_Switch 517329;
BA_ "SPN" SG_ 2566910497 Brake_Fluid_Level_Switch 517305;
BA_ "SPN" SG_ 2566911632 Purge_Valve_Solenoid_Output 517195;
BA_ "SPN" SG_ 2566911632 Target_Boost_Pressure 517222;
BA_ "SPN" SG_ 2566911632 Boost_Control_Valve_Duty_Cycle 517002;
BA_ "SPN" SG_ 2566911632 Boost_Temperature 516629;
BA_ "SPN" SG_ 2566911632 High_Range_Engine_Percent_Load 516530;
BA_ "SPN" SG_ 2566911632 Boost_Pressure_Sensor 517252;
BA_ "SPN" SG_ 2566911632 Boost_Temperature_Sensor 516275;
BA_ "SPN" SG_ 2566911632 Coolant_Fan_Duty_Cycle 516751;
BA_ "SPN" SG_ 2566834832 Flash_Malfunction_Indicator_Lamp 3038;
BA_ "SPN" SG_ 2566834832 Malfunction_Indicator_Lamp_Statu 1213;
BA_ "SPN" SG_ 2566834832 Red_Stop_Lamp_Status 623;
BA_ "SPN" SG_ 2566834832 Amber_Warning_Lamp_Status 624;
BA_ "SPN" SG_ 2566834832 Flash_Red_Stop_Lamp_RSL 3039;
BA_ "SPN" SG_ 2566834832 Flash_Amber_Warning_Lamp_AWL 3040;
BA_ "SPN" SG_ 2566834832 Flash_Protect_Lamp 3041;
BA_ "SPN" SG_ 2566834832 Protect_Lamp_Status 987;
BA_ "SPN" SG_ 2566834832 DTC_1 999990;
BA_ "SPN" SG_ 2566834832 DTC_2 999991;
BA_ "SPN" SG_ 2566834832 DTC_3 999992;
BA_ "SPN" SG_ 2566834832 DTC_4 999993;
BA_ "SPN" SG_ 2566834832 DTC_5 999994;
BA_ "SPN" SG_ 2566834832 DTC_6 999995;
BA_ "SPN" SG_ 2566834832 DTC_7 999996;
BA_ "SPN" SG_ 2566834832 DTC_8 999997;
BA_ "SPN" SG_ 2566834832 DTC_9 999998;
BA_ "SPN" SG_ 2566834832 DTC_10 999999;
BA_ "SPN" SG_ 2566856336 Switched_Power_Output_Status 517372;
BA_ "SPN" SG_ 2566856336 K15_Output_Status 517436;
BA_ "SPN" SG_ 2566856336 Lock_Motor_Driver_Status 517395;
BA_ "SPN" SG_ 2566856336 Homelink_1_Output_Status 517456;
BA_ "SPN" SG_ 2566856336 Homelink_2_Output_Status 517424;
BA_ "SPN" SG_ 2566856336 Windshield_Output_Status 517296;
BA_ "SPN" SG_ 2566856336 Puddle_Light_Driver_Status 517426;
BA_ "SPN" SG_ 2566856336 Puddle_Light_Enable_Status 517407;
BA_ "SPN" SG_ 2566856336 Fuel_Door_Switch_Input_Status 517467;
BA_ "SPN" SG_ 2566856336 VCM_Location_Pin_Status 517480;
BA_ "SPN" SG_ 2566856336 Fuel_Lock_Motor_Driver_Status 517316;
BA_ "SPN" SG_ 2566856336 Accent_Lights_Output_Status 517363;
BA_ "SPN" SG_ 2566910608 Hazard_Switch_Input 517413;
BA_ "SPN" SG_ 2566910608 LowHigh_Beam_Input 517402;
BA_ "SPN" SG_ 2566910608 Fog_Light_Input 517289;
BA_ "SPN" SG_ 2566910608 Horn_Input 517430;
BA_ "SPN" SG_ 2566910608 High_Beam_Output 517311;
BA_ "SPN" SG_ 2566910608 Low_Beam_Output 517381;
BA_ "SPN" SG_ 2566910608 Left_Fog_Light_Output 517337;
BA_ "SPN" SG_ 2566910608 Right_Fog_Light_Output 517293;
BA_ "SPN" SG_ 2566910608 Unlock_Input 517439;
BA_ "SPN" SG_ 2566910608 Lock_Input 517387;
BA_ "SPN" SG_ 2566910608 Windsheild_Switch_Up_Input 517334;
BA_ "SPN" SG_ 2566910608 Windsheild_Switch_Down_Input 517315;
BA_ "SPN" SG_ 2566910608 Horn_Output 517469;
BA_ "SPN" SG_ 2566910608 Hazard_Light_Output 517298;
BA_ "SPN" SG_ 2566910608 Tail_Light_Output 517420;
BA_ "SPN" SG_ 2566910608 Brake_Light_Output 517412;
BA_ "SPN" SG_ 2566910608 Left_Front_Turn_Signal_Output 517459;
BA_ "SPN" SG_ 2566910608 Right_Front_Turn_Signal_Output 517388;
BA_ "SPN" SG_ 2566910608 Left_Rear_Turn_Signal_Output 517408;
BA_ "SPN" SG_ 2566910608 Right_Rear_Turn_Signal_Output 517358;
BA_ "SPN" SG_ 2566910608 Secondary_Air_Valve_Output 517292;
BA_ "SPN" SG_ 2566910608 Secondary_Air_Valve_Command 517342;
BA_ "SPN" SG_ 2566910608 Heated_Grip_Heat_Increase_Switch 517416;
BA_ "SPN" SG_ 2566910608 Heated_Grip_Heat_Decrease_Switch 517328;
BA_ "SPN" SG_ 2566910608 pOperator_Button_1 517302;
BA_ "SPN" SG_ 2566910608 pOperator_Button_2 517401;
BA_ "SPN" SG_ 2566910608 pSide_Stand_Switch 517350;
BA_ "SPN" SG_ 2566910608 Coolant_Fluid_Level_Switch 517455;
BA_ "SPN" SG_ 2566910608 Driveline_Momentary_Left 517304;
BA_ "SPN" SG_ 2566910608 Driveline_Momentary_Right 517403;
BA_ "SPN" SG_ 2566910608 Seatbelt_Switch 517329;
BA_ "SPN" SG_ 2566910608 Brake_Fluid_Level_Switch 517305;
BA_ "SPN" SG_ 2566856337 Switched_Power_Output_Status 517372;
BA_ "SPN" SG_ 2566856337 K15_Output_Status 517436;
BA_ "SPN" SG_ 2566856337 Lock_Motor_Driver_Status 517395;
BA_ "SPN" SG_ 2566856337 Homelink_1_Output_Status 517456;
BA_ "SPN" SG_ 2566856337 Homelink_2_Output_Status 517424;
BA_ "SPN" SG_ 2566856337 Windshield_Output_Status 517296;
BA_ "SPN" SG_ 2566856337 Puddle_Light_Driver_Status 517426;
BA_ "SPN" SG_ 2566856337 Puddle_Light_Enable_Status 517407;
BA_ "SPN" SG_ 2566856337 Fuel_Door_Switch_Input_Status 517467;
BA_ "SPN" SG_ 2566856337 VCM_Location_Pin_Status 517480;
BA_ "SPN" SG_ 2566856337 Fuel_Lock_Motor_Driver_Status 517316;
BA_ "SPN" SG_ 2566856337 Accent_Lights_Output_Status 517363;
BA_ "SPN" SG_ 2566882961 pVCMState 523960;
BA_ "SPN" SG_ 2566882961 pFog_Light_Control_Mode 516369;
BA_ "SPN" SG_ 2566882961 pHeated_Grips_Control_Mode 516370;
BA_ "SPN" SG_ 2566882961 pLoadShedSts 516371;
BA_ "SPN" SG_ 2566834833 Flash_Malfunction_Indicator_Lamp 3038;
BA_ "SPN" SG_ 2566834833 Malfunction_Indicator_Lamp_Statu 1213;
BA_ "SPN" SG_ 2566834833 Red_Stop_Lamp_Status 623;
BA_ "SPN" SG_ 2566834833 Amber_Warning_Lamp_Status 624;
BA_ "SPN" SG_ 2566834833 Flash_Red_Stop_Lamp_RSL 3039;
BA_ "SPN" SG_ 2566834833 Flash_Amber_Warning_Lamp_AWL 3040;
BA_ "SPN" SG_ 2566834833 Flash_Protect_Lamp 3041;
BA_ "SPN" SG_ 2566834833 Protect_Lamp_Status 987;
BA_ "SPN" SG_ 2566834833 DTC_1 999990;
BA_ "SPN" SG_ 2566834833 DTC_2 999991;
BA_ "SPN" SG_ 2566834833 DTC_3 999992;
BA_ "SPN" SG_ 2566834833 DTC_4 999993;
BA_ "SPN" SG_ 2566834833 DTC_5 999994;
BA_ "SPN" SG_ 2566834833 DTC_6 999995;
BA_ "SPN" SG_ 2566834833 DTC_7 999996;
BA_ "SPN" SG_ 2566834833 DTC_8 999997;
BA_ "SPN" SG_ 2566834833 DTC_9 999998;
BA_ "SPN" SG_ 2566834833 DTC_10 999999;
BA_ "SPN" SG_ 2566799505 High_Beam_Head_Light_Data 2348;
BA_ "SPN" SG_ 2566799505 Low_Beam_Head_Light_Data 2350;
BA_ "SPN" SG_ 2566799505 Running_Light 2404;
BA_ "SPN" SG_ 2566799505 Left_Turn_Signal_Lights 2368;
BA_ "SPN" SG_ 2566799505 Right_Turn_Signal_Lights 2370;
BA_ "SPN" SG_ 2566799505 Left_Stop_Light 2372;
BA_ "SPN" SG_ 2566799505 Right_Stop_Light 2374;
BA_ "SPN" SG_ 2566799505 Tractor_Front_Fog_Lights 2388;
BA_ "SPN" SG_ 2566799505 Implement_OEM_Option_1_Light 2396;
BA_ "SPN" SG_ 2566799505 Implement_OEM_Option_2_Light 2398;
BA_ "SPN" SG_ 2566909952 Lifetime_Engine_Running_Time_Acc 516724;
BA_ "SPN" SG_ 2566909952 Engine_Running_Time_Since_Key_On 517168;
BA_ "SPN" SG_ 2566909952 Engine_Oil_Pressure 516318;
BA_ "SPN" SG_ 2566909952 Engine_Oil_Pressure_Sensor 517224;
BA_ "SPN" SG_ 2566909952 Intercooler_Fan_Driver_1_Duty_Cy 516581;
BA_ "SPN" SG_ 2566912512 Gear_RNLH3456 516238;
BA_ "SPN" SG_ 2566912512 Rollover_Sensor 517052;
BA_ "SPN" SG_ 2566912512 Throttle_Release_Input 516906;
BA_ "SPN" SG_ 2566912512 Fuel_Type_Sensor_Voltage 516705;
BA_ "SPN" SG_ 2566912512 PTO_Speed_LSB 517102;
BA_ "SPN" SG_ 2566912512 PTO_Speed_MSB 517184;
BA_ "SPN" SG_ 2566912512 Two_Speed_Shift_Coil_Duty_Cycle 517025;
BA_ "SPN" SG_ 2566912512 Fuel_Level_Sensor_Voltage 517281;
BA_ "SPN" SG_ 2566911232 Fuel_Pump_Driver_Circuit_OnOff 517410;
BA_ "SPN" SG_ 2566911232 Rollover_Switch 517326;
BA_ "SPN" SG_ 2566911232 Crankshaft_Sensor_Signal_SDI_2X 517368;
BA_ "SPN" SG_ 2566911232 Camshaft_Sensor_Signal_SDI_5X 517376;
BA_ "SPN" SG_ 2566911232 RPM_Limit_Active 517313;
BA_ "SPN" SG_ 2566911232 Idle_Switch 517471;
BA_ "SPN" SG_ 2566911232 Cycle_Synchronization 517312;
BA_ "SPN" SG_ 2566911232 Idle_Speed_Control_Status 517482;
BA_ "SPN" SG_ 2566911232 Ignition_Switch_Input 517318;
BA_ "SPN" SG_ 2566911232 RunStop_Switch_Input 517330;
BA_ "SPN" SG_ 2566911232 Start_Switch_Input 517331;
BA_ "SPN" SG_ 2566911232 Throttle_Release_Switch_Input 517308;
BA_ "SPN" SG_ 2566911232 Fan_Relay_Output 517475;
BA_ "SPN" SG_ 2566911232 Intercooler_Fan_Output 517321;
BA_ "SPN" SG_ 2566911232 Reverse_Alarm_Output 517364;
BA_ "SPN" SG_ 2566911232 Main_Relay_Output 517335;
BA_ "SPN" SG_ 2566911232 Start_Solenoid_OutputLSD 517399;
BA_ "SPN" SG_ 2566911232 Ignition_Relay_Output 517386;
BA_ "SPN" SG_ 2566911232 Chassis_Relay_Output 517444;
BA_ "SPN" SG_ 2566911232 Starter_Enable_OutputHSD 517462;
BA_ "SPN" SG_ 2566911232 Exhaust_Valve_Output 517419;
BA_ "SPN" SG_ 2566911232 Battery_Charge_Relay_Output 517301;
BA_ "SPN" SG_ 2566911232 HeaterAccessory_Relay 517478;
BA_ "SPN" SG_ 2566911232 Intercooler_Pump_Driver_Circuit_ 517473;
BA_ "SPN" SG_ 2566911232 MIL_Lamp_Output 517418;
BA_ "SPN" SG_ 2566911232 Over_Temperature_Lamp_Output 517391;
BA_ "SPN" SG_ 2566911232 KnockDetination_Lamp_Output 517307;
BA_ "SPN" SG_ 2566911232 Clutch_Switch_Input_1BOT 517303;
BA_ "SPN" SG_ 2566911232 Electronic_Oil_Pump_Driver_Circu 517353;
BA_ "SPN" SG_ 2566911232 Fuel_Pull_Solenoid_Status 517288;
BA_ "SPN" SG_ 2566911232 Clutch_Switch_Input_2TOT 517333;
BA_ "SPN" SG_ 2566911232 Turbo_Oil_Pump_Driver_Circuit 516771;
BA_ "SPN" SG_ 2566904832 misfiring_detected_from_multiple 517151;
BA_ "SPN" SG_ 2566904832 cat_damaging_misfire_rate_exceed 516286;
BA_ "SPN" SG_ 2566904832 Detection_of_Misfiring_for_Fuel_ 516920;
BA_ "SPN" SG_ 2566904832 statee_flag_fuel_cutoff_by_catal 517286;
BA_ "SPN" SG_ 2566904832 DMD_counter_in_exhaust_interval_ 517127;
BA_ "SPN" SG_ 2566904832 DMD_counter_in_exhaust_interval_ 516234;
BA_ "SPN" SG_ 2566913536 Throttle_Position 516621;
BA_ "SPN" SG_ 2566913536 Engine_Temperature 517259;
BA_ "SPN" SG_ 2566913536 Intake_Air_Temperature 517271;
BA_ "SPN" SG_ 2566913536 Manifold_Absolute_Pressure 516563;
BA_ "SPN" SG_ 2566913536 Boost_Pressure 517225;
BA_ "SPN" SG_ 2566913536 Barometric_Pressure 516749;
BA_ "SPN" SG_ 2566913536 Vehicle_Speed 516772;
BA_ "SPN" SG_ 2566913536 Barometric_Pressure_Sensor 516994;
BA_ "SPN" SG_ 2566905856 Actual_Lambda_Bank 517243;
BA_ "SPN" SG_ 2566905856 Desired_Lambda_Bank 517185;
BA_ "SPN" SG_ 2566905856 Actual_Lambda_Heater_Temperature 516961;
BA_ "SPN" SG_ 2566905856 Desired_Lambda_Heater_Temperatur 516257;
BA_ "SPN" SG_ 2566905856 Heater_Duty_Cycle 516281;
BA_ "SPN" SG_ 2566905856 O2_Value_LSB 516316;
BA_ "SPN" SG_ 2566905856 O2_Value_MSB 517212;
BA_ "SPN" SG_ 2566905856 Fuel_Adaptation_Active 516300;
BA_ "SPN" SG_ 2566883328 Fuel_Temperature 517030;
BA_ "SPN" SG_ 2566883328 Fuel_Rail_Pressure_Sensor_Voltag 516945;
BA_ "SPN" SG_ 2566883328 Scaled_Fuel_Absolute_Pressure_Se 517173;
BA_ "SPN" SG_ 2566883328 Desired_Fuel_Rail_Absolute_Press 516492;
BA_ "SPN" SG_ 2566883328 Actual_Fuel_Pump_Control_PWM 516938;
BA_ "SPN" SG_ 2566883328 Expected_Fuel_Pump_Power_PWM 516511;
BA_ "SPN" SG_ 2566910720 Drive_Mode_1_Input 517385;
BA_ "SPN" SG_ 2566910720 Drive_Mode_2_Input 517332;
BA_ "SPN" SG_ 2566910720 Drive_Mode_3_Input 517452;
BA_ "SPN" SG_ 2566910720 Drive_Mode_4_Input 517435;
BA_ "SPN" SG_ 2566910720 Drive_Mode_1_Output 517428;
BA_ "SPN" SG_ 2566910720 Drive_Mode_2_Output 517394;
BA_ "SPN" SG_ 2566910720 Drive_Mode_3_Output 517441;
BA_ "SPN" SG_ 2566910720 Drive_Mode_4_Output 517466;
BA_ "SPN" SG_ 2566910720 PTO_Mode_Input 517484;
BA_ "SPN" SG_ 2566910720 PTO_Mode_Output 517443;
BA_ "SPN" SG_ 2566910720 Drivers_Net 517405;
BA_ "SPN" SG_ 2566910720 Drivers_Seatbelt 517322;
BA_ "SPN" SG_ 2566910720 Tilt_Lock_Input 517479;
BA_ "SPN" SG_ 2566910720 Work_Group_Lock_Input 517300;
BA_ "SPN" SG_ 2566910720 Operator_Presence_Input 517361;
BA_ "SPN" SG_ 2566910720 Work_Mode_Input 517393;
BA_ "SPN" SG_ 2566910720 Tilt_Lock_Output 517380;
BA_ "SPN" SG_ 2566910720 Work_Group_Lock_Output 517347;
BA_ "SPN" SG_ 2566910720 Operator_Presence_Output 517423;
BA_ "SPN" SG_ 2566910720 Tether_Switch_Status 517453;
BA_ "SPN" SG_ 2566910720 Foot_on_Cruise_Control_Input 517297;
BA_ "SPN" SG_ 2566910720 Cruise_Input 517446;
BA_ "SPN" SG_ 2566910720 Treadle_Input 517352;
BA_ "SPN" SG_ 2566910720 Cruise_Speed_SetDecel_Input 517324;
BA_ "SPN" SG_ 2566910720 Foot_on_Cruise_Control_Output 517421;
BA_ "SPN" SG_ 2566910720 Cruise_Output 517310;
BA_ "SPN" SG_ 2566910720 Cruise_Control_to_Set_Speed_Outp 517306;
BA_ "SPN" SG_ 2566910720 Cruise_Control_ResumeAccel_Outpu 517483;
BA_ "SPN" SG_ 2566910720 Cruise_Control_ResumeAccel_Input 517390;
BA_ "SPN" SG_ 2566910720 Cruise_Control_Cancel_Input 517425;
BA_ "SPN" SG_ 2566910720 Brake_Switch_2_Input 517404;
BA_ "SPN" SG_ 2566910720 Oil_Pressure_Switch_Input 517445;
BA_ "SPN" SG_ 2566912256 Throttle_Position_Sensor_2 516671;
BA_ "SPN" SG_ 2566912256 Sensor_Supply_Voltage_1 517031;
BA_ "SPN" SG_ 2566912256 Sensor_Supply_Voltage_2 516272;
BA_ "SPN" SG_ 2566912256 Sensor_Supply_Voltage_3 516270;
BA_ "SPN" SG_ 2566912256 ECU_Output_Supply_Voltage_1 516626;
BA_ "SPN" SG_ 2566912256 ECU_Output_Supply_Voltage_2 516535;
BA_ "SPN" SG_ 2566912256 Engine_Running_Mode 517218;
BA_ "SPN" SG_ 2566912256 Fuel_Type_Selected 516686;
BA_ "SPN" SG_ 2566912256 Boost_Launch_Status 517048;
BA_ "SPN" SG_ 2566913280 Idle_Air_Control_Position_Step_M 517154;
BA_ "SPN" SG_ 2566913280 Desired_IAC_Position 517177;
BA_ "SPN" SG_ 2566913280 Idle_Air_Solenoid_DC_Solenoid_Sy 517132;
BA_ "SPN" SG_ 2566913280 Engine_Percent_Load_if_applicabl 517148;
BA_ "SPN" SG_ 2566913280 Idle_Target_RPM 517163;
BA_ "SPN" SG_ 2566913280 Absolute_Throttle_Percent 516683;
BA_ "SPN" SG_ 2566913280 Throttle_Position_Sensor_HR 516491;
BA_ "SPN" SG_ 2566908672 Accelerator_Position_Sensor_1 516462;
BA_ "SPN" SG_ 2566908672 Accelerator_Position_Sensor_2 516137;
BA_ "SPN" SG_ 2566908672 Brake_Position_Sensor_1 516657;
BA_ "SPN" SG_ 2566908672 Brake_Position_Sensor_2 517088;
BA_ "SPN" SG_ 2566911488 Purge_Valve_Solenoid_Output 517195;
BA_ "SPN" SG_ 2566911488 Target_Boost_Pressure 517222;
BA_ "SPN" SG_ 2566911488 Boost_Control_Valve_Duty_Cycle 517002;
BA_ "SPN" SG_ 2566911488 Boost_Temperature 516629;
BA_ "SPN" SG_ 2566911488 High_Range_Engine_Percent_Load 516530;
BA_ "SPN" SG_ 2566911488 Boost_Pressure_Sensor 517252;
BA_ "SPN" SG_ 2566911488 Boost_Temperature_Sensor 516275;
BA_ "SPN" SG_ 2566911488 Coolant_Fan_Duty_Cycle 516751;
BA_ "SPN" SG_ 2566910464 Hazard_Switch_Input 517413;
BA_ "SPN" SG_ 2566910464 LowHigh_Beam_Input 517402;
BA_ "SPN" SG_ 2566910464 Fog_Light_Input 517289;
BA_ "SPN" SG_ 2566910464 Horn_Input 517430;
BA_ "SPN" SG_ 2566910464 High_Beam_Output 517311;
BA_ "SPN" SG_ 2566910464 Low_Beam_Output 517381;
BA_ "SPN" SG_ 2566910464 Left_Fog_Light_Output 517337;
BA_ "SPN" SG_ 2566910464 Right_Fog_Light_Output 517293;
BA_ "SPN" SG_ 2566910464 Unlock_Input 517439;
BA_ "SPN" SG_ 2566910464 Lock_Input 517387;
BA_ "SPN" SG_ 2566910464 Windsheild_Switch_Up_Input 517334;
BA_ "SPN" SG_ 2566910464 Windsheild_Switch_Down_Input 517315;
BA_ "SPN" SG_ 2566910464 Horn_Output 517469;
BA_ "SPN" SG_ 2566910464 Hazard_Light_Output 517298;
BA_ "SPN" SG_ 2566910464 Tail_Light_Output 517420;
BA_ "SPN" SG_ 2566910464 Brake_Light_Output 517412;
BA_ "SPN" SG_ 2566910464 Left_Front_Turn_Signal_Output 517459;
BA_ "SPN" SG_ 2566910464 Right_Front_Turn_Signal_Output 517388;
BA_ "SPN" SG_ 2566910464 Left_Rear_Turn_Signal_Output 517408;
BA_ "SPN" SG_ 2566910464 Right_Rear_Turn_Signal_Output 517358;
BA_ "SPN" SG_ 2566910464 Secondary_Air_Valve_Output 517292;
BA_ "SPN" SG_ 2566910464 Secondary_Air_Valve_Command 517342;
BA_ "SPN" SG_ 2566910464 Heated_Grip_Heat_Increase_Switch 517416;
BA_ "SPN" SG_ 2566910464 Heated_Grip_Heat_Decrease_Switch 517328;
BA_ "SPN" SG_ 2566910464 pOperator_Button_1 517302;
BA_ "SPN" SG_ 2566910464 pOperator_Button_2 517401;
BA_ "SPN" SG_ 2566910464 pSide_Stand_Switch 517350;
BA_ "SPN" SG_ 2566910464 Coolant_Fluid_Level_Switch 517455;
BA_ "SPN" SG_ 2566910464 Driveline_Momentary_Left 517304;
BA_ "SPN" SG_ 2566910464 Driveline_Momentary_Right 517403;
BA_ "SPN" SG_ 2566910464 Seatbelt_Switch 517329;
BA_ "SPN" SG_ 2566910464 Brake_Fluid_Level_Switch 517305;
BA_ "SPN" SG_ 2566908160 Desired_Torque_Change_for_Idle_S 517081;
BA_ "SPN" SG_ 2566908160 Throttle_Angle_Mass_Flow_Correct 517113;
BA_ "SPN" SG_ 2566908160 Drag_Torque_Adaptation 517142;
BA_ "SPN" SG_ 2566908160 Throttle_Body_Learning_Step 516931;
BA_ "SPN" SG_ 2566913792 Throttle_Position_Sensor_1 517134;
BA_ "SPN" SG_ 2566913792 Engine_Speed 517150;
BA_ "SPN" SG_ 2566913792 Engine_Temperature_Sensor 516965;
BA_ "SPN" SG_ 2566913792 Manifold_Absolute_Pressure_Senso 516976;
BA_ "SPN" SG_ 2566913792 Intake_Air_Temperature_Sensor 516728;
BA_ "SPN" SG_ 2566913792 Vehicle_Electric_Power 516289;
BA_ "SPN" SG_ 2566776064 Maximum_Vehicle_Speed_Limit_6 2593;
BA_ "SPN" SG_ 2566776064 Applied_Vehicle_Speed_Limit 2595;
BA_ "SPN" SG_ 2566776064 Maximum_Vehicle_Speed_Limit_5 2592;
BA_ "SPN" SG_ 2566776064 Maximum_Vehicle_Speed_Limit_4 2591;
BA_ "SPN" SG_ 2566776064 Maximum_Vehicle_Speed_Limit_1 2588;
BA_ "SPN" SG_ 2566776064 Maximum_Vehicle_Speed_Limit_2 2589;
BA_ "SPN" SG_ 2566776064 Maximum_Vehicle_Speed_Limit_7 2594;
BA_ "SPN" SG_ 2566776064 Maximum_Vehicle_Speed_Limit_3 2590;
BA_ "SPN" SG_ 2566905088 cylinder_0_weighted_misfire_coun 516572;
BA_ "SPN" SG_ 2566905088 cylinder_1_weighted_misfire_coun 516785;
BA_ "SPN" SG_ 2566905088 cylinder_2_weighted_misfire_coun 516644;
BA_ "SPN" SG_ 2566905088 cylinder_3_weighted_misfire_coun 517070;
BA_ "SPN" SG_ 2566854656 Intercooler_Fan_Driver_1 517400;
BA_ "SPN" SG_ 2566854656 Intercooler_Fan_Driver_2 517309;
BA_ "SPN" SG_ 2566854656 Fan_Driver_2_State 517325;
BA_ "SPN" SG_ 2566854656 AC_Module_Command_Status 517411;
BA_ "SPN" SG_ 2566854656 AC_Compressor_Clutch_Status 517294;
BA_ "SPN" SG_ 2566854656 AC_Condensor_Fan_Status 517344;
BA_ "SPN" SG_ 2566854656 Alternator_Charge_Disable_Status 517451;
BA_ "SPN" SG_ 2566912000 Lambda_Sensor_Voltage_Bank_1_F 517179;
BA_ "SPN" SG_ 2566912000 Actual_Lambda_Bank_1_F 516934;
BA_ "SPN" SG_ 2566912000 Desired_Lambda_Bank_1_F 517055;
BA_ "SPN" SG_ 2566912000 Mixture_Adaption_High_Load_Bank_ 517216;
BA_ "SPN" SG_ 2566912000 Mixture_Adaption_Low_Load_Bank_1 516520;
BA_ "SPN" SG_ 2566912000 Closed_Loop_Adjustment_Factor_1_ 516933;
BA_ "SPN" SG_ 2566912000 Average_Closed_Loop_Adjustment_F 516784;
BA_ "SPN" SG_ 2566912000 Lambda_Sensor_Heater_Output_Bank 516732;
BA_ "SPN" SG_ 2566912000 ClosedLoop_Mixture_Control_Bank_ 517250;
BA_ "SPN" SG_ 2566912000 AirFuel_Mixture_Status_Bank_1_F 517487;
BA_ "SPN" SG_ 2566910976 ADC_Output 517437;
BA_ "SPN" SG_ 2566910976 Turf_Mode_Output_diff_unlocked 517349;
BA_ "SPN" SG_ 2566910976 AWD_Output 517345;
BA_ "SPN" SG_ 2566910976 Brake_Switch_1_Input 517377;
BA_ "SPN" SG_ 2566910976 ADC_Switch_Input 517458;
BA_ "SPN" SG_ 2566910976 Turf_Mode_Input 517339;
BA_ "SPN" SG_ 2566910976 AWD_Switch_Input 517374;
BA_ "SPN" SG_ 2566910976 Reverse_Switch_Input 517369;
BA_ "SPN" SG_ 2566910976 Reverse_Limit_Switch_Input 517351;
BA_ "SPN" SG_ 2566910976 Forward_Limit_Switch_Input 517373;
BA_ "SPN" SG_ 2566910976 Engine_Direction 517440;
BA_ "SPN" SG_ 2566910976 Reverse_Speed_Limit_Override_Inp 517359;
BA_ "SPN" SG_ 2566910976 Reverse_Overspeed_Signal 517389;
BA_ "SPN" SG_ 2566910976 Reverse_Motor_Drive_Input 517397;
BA_ "SPN" SG_ 2566910976 Low_Range_Switch_Input 517295;
BA_ "SPN" SG_ 2566910976 Right_Turn_Signal_Input 517460;
BA_ "SPN" SG_ 2566910976 Left_Turn_Signal_Input 517414;
BA_ "SPN" SG_ 2566910976 Park_Brake_Switch_Input 517398;
BA_ "SPN" SG_ 2566910976 PTO_Engagement_Status 517291;
BA_ "SPN" SG_ 2566910976 Kickstand_Switch_Input 517465;
BA_ "SPN" SG_ 2566910976 System_On_Input 517367;
BA_ "SPN" SG_ 2566910976 Neutral_Switch_Input 517427;
BA_ "SPN" SG_ 2566910976 Throttle_Limphome_Operation_Cond 517406;
BA_ "SPN" SG_ 2566910976 Reflash_Enable_Input_Signal 517348;
BA_ "SPN" SG_ 2566910976 TPS_Learn_Input_Signal 517434;
BA_ "SPN" SG_ 2566910976 Throttle_Body_Initialization__Le 517448;
BA_ "SPN" SG_ 2566910976 Throttle_Body_Initialization__Le 517468;
BA_ "SPN" SG_ 2566910976 Safety_Fuel_Cutoff_Condition 517422;
BA_ "SPN" SG_ 2566910976 Reversible_Injection_Cutoff_Cond 517383;
BA_ "SPN" SG_ 2566910976 Irreversible_Injection_Cutoff_Co 517327;
BA_ "SPN" SG_ 2566910976 ETC_Function_Monitoring_Irrevers 517341;
BA_ "SPN" SG_ 2566913024 Injector_1_Front 517249;
BA_ "SPN" SG_ 2566913024 Ignition_Coil_Primary_Driver_1_F 516647;
BA_ "SPN" SG_ 2566913024 Ignition_Timing_Cylinder_1_Front 516494;
BA_ "SPN" SG_ 2566913024 Air_Injector_Duration_Cylinder_1 516685;
BA_ "SPN" SG_ 2566913024 Injector_2_Rear 516622;
BA_ "SPN" SG_ 2566913024 Ignition_Coil_Primary_Driver_2_R 516539;
BA_ "SPN" SG_ 2566913024 Ignition_Timing_Cylinder_2_Rear 516265;
BA_ "SPN" SG_ 2566913024 Air_Injector_Duration_Cylinder_2 517039;
BA_ "SPN" SG_ 2566912768 Injector_3 516983;
BA_ "SPN" SG_ 2566912768 Ignition_Coil_Primary_Driver_3 516524;
BA_ "SPN" SG_ 2566912768 Ignition_Timing_Cylinder_3 516661;
BA_ "SPN" SG_ 2566912768 Air_Injector_Duration_Cylinder_3 516457;
BA_ "SPN" SG_ 2566912768 Injector_4 517202;
BA_ "SPN" SG_ 2566912768 Ignition_Coil_Primary_Driver_4 517138;
BA_ "SPN" SG_ 2566912768 Ignition_Timing_Cylinder_4 517152;
BA_ "SPN" SG_ 2566912768 Air_Injector_Duration_Cylinder_4 516320;
BA_ "GenMsgCycleTime" BO_ 2365526259 1000;
BA_ "GenMsgCycleTime" BO_ 2566846451 1000;
BA_ "GenMsgCycleTime" BO_ 2365526771 100;
BA_ "GenMsgCycleTime" BO_ 2297441780 20;
BA_ "GenMsgCycleTimeFast" BO_ 2297441780 10;
BA_ "GenMsgCycleTime" BO_ 2365526004 100;
BA_ "GenMsgCycleTime" BO_ 2365525748 10;
BA_ "GenMsgCycleTime" BO_ 2365526516 100;
BA_ "GenMsgCycleTime" BO_ 2365526260 1000;
BA_ "GenMsgCycleTime" BO_ 2566846452 1000;
BA_ "GenMsgCycleTime" BO_ 2365526772 100;
BA_ "GenMsgCycleTime" BO_ 2298415350 100;
BA_ "GenMsgCycleTime" BO_ 2298415606 100;
BA_ "GenMsgCycleTime" BO_ 2298415094 10;
BA_ "GenMsgCycleTime" BO_ 2298415607 100;
BA_ "GenMsgCycleTime" BO_ 2298415095 10;
BA_ "GenMsgCycleTime" BO_ 2298415351 100;
BA_ "GenMsgCycleTime" BO_ 2566834937 1000;
BA_ "GenMsgCycleTime" BO_ 2365523705 5000;
BA_ "GenMsgCycleTimeFast" BO_ 2365523705 50;
BA_ "GenMsgCycleTime" BO_ 2566877689 1000;
BA_ "GenMsgCycleTime" BO_ 2566860071 1000;
BA_ "GenMsgCycleTimeFast" BO_ 2566860071 500;
BA_ "GenMsgCycleTime" BO_ 2365530123 10;
BA_ "GenMsgCycleTime" BO_ 2566834721 1000;
BA_ "GenMsgCycleTime" BO_ 2566860321 1000;
BA_ "GenMsgCycleTimeFast" BO_ 2566860321 500;
BA_ "GenMsgCycleTime" BO_ 2566882849 100;
BA_ "GenMsgCycleTime" BO_ 2566834832 1000;
BA_ "GenMsgCycleTime" BO_ 2566882961 100;
BA_ "GenMsgCycleTime" BO_ 2566834833 1000;
BA_ "GenMsgCycleTime" BO_ 2566799505 1000;
BA_ "GenMsgCycleTimeFast" BO_ 2566799505 100;
BA_ "GenMsgCycleTime" BO_ 2566776064 1000;
VAL_ 2365526259 pFloat_State 2 "Error" 0 "Electrolyte Level Ok" 1 "Low Electrolyte Level Detected" 3 "Not Available" ;
VAL_ 2365526771 pCharger_State 17 "Bulk Phase" 5 "Over Temp Shutdown" 24 "Charge Complete" 2 "Low V Shutdown" 16 "Recovery Phase" 19 "Finish Phase" 1 "High V Shutdown" 6 "Internal Fault Shutdown" 4 "Charge Timeout" 0 "Off" 26 " Equalize/Balance Charging" 20 "Reduced Performance" 31 "Not Available" 25 "Float Charging" 27 "Maintenance Charging" 3 "Check battery shutdown" 18 "Absorption Phase" ;
VAL_ 2365526771 pAC_Status 4 "220 AC, reduced power due to low V" 7 "Not Available" 2 "110 AC, reduced power due to low V" 3 "110 AC" 0 "No AC present" 1 "AC Present, voltage level not available" 6 "Error" 5 "220 AC" ;
VAL_ 2365526516 pDCDC_State 6 "Error" 0 "Off" 7 "Not Available" 4 "Powered, Disabled" 5 "Powered, Enabled" ;
VAL_ 2365526516 pKEY_State 2 "Error" 0 "Off" 1 "On" 3 "Not-Available" ;
VAL_ 2365526516 pBalance_State 4 "Charging" 8 "Relaxing" 15 "Not Available" 2 "Resting" 1 "Driving" 0 "Power Up" ;
VAL_ 2365526516 pWAKE_State 2 "Error" 0 "Off" 1 "On" 3 "Not-Available" ;
VAL_ 2365526260 pFloat_State 2 "Error" 0 "Electrolyte Level Ok" 1 "Low Electrolyte Level Detected" 3 "Not Available" ;
VAL_ 2365526772 pCharger_State 17 "Bulk Phase" 5 "Over Temp Shutdown" 24 "Charge Complete" 2 "Low V Shutdown" 16 "Recovery Phase" 19 "Finish Phase" 1 "High V Shutdown" 6 "Internal Fault Shutdown" 4 "Charge Timeout" 0 "Off" 26 " Equalize/Balance Charging" 20 "Reduced Performance" 31 "Not Available" 25 "Float Charging" 27 "Maintenance Charging" 3 "Check battery shutdown" 18 "Absorption Phase" ;
VAL_ 2365526772 pAC_Status 4 "220 AC, reduced power due to low V" 7 "Not Available" 2 "110 AC, reduced power due to low V" 3 "110 AC" 0 "No AC present" 1 "AC Present, voltage level not available" 6 "Error" 5 "220 AC" ;
VAL_ 2298415350 pController_Thermal_Cutback_Stat 0 "Inactive" 1 "Active" ;
VAL_ 2298415350 pMotor_Power_Cutback_Status 0 "Inactive" 1 "Active" ;
VAL_ 2298415350 pMotor_Thermal_Cutback_Status 0 "Inactive" 1 "Active" ;
VAL_ 2298415350 pInput_DC_Current_Cutback_Status 0 "Inactive" 1 "Active" ;
VAL_ 2298415350 pSpeed_Limit_Cutback_Status 0 "Inactive" 1 "Active" ;
VAL_ 2298415094 pPerformance_State 1 "Shutdown" 2 "Precharge" 0 "Initialize" 3 "Energized" 15 "Not Available" 5 "Fault Off" 4 "Enabled" 6 "Fault Reaction" ;
VAL_ 2298415095 pPerformance_State 1 "Shutdown" 2 "Precharge" 0 "Initialize" 3 "Energized" 15 "Not Available" 5 "Fault Off" 4 "Enabled" 6 "Fault Reaction" ;
VAL_ 2298415351 pController_Thermal_Cutback_Stat 0 "Inactive" 1 "Active" ;
VAL_ 2298415351 pMotor_Power_Cutback_Status 0 "Inactive" 1 "Active" ;
VAL_ 2298415351 pMotor_Thermal_Cutback_Status 0 "Inactive" 1 "Active" ;
VAL_ 2298415351 pInput_DC_Current_Cutback_Status 0 "Inactive" 1 "Active" ;
VAL_ 2298415351 pSpeed_Limit_Cutback_Status 0 "Inactive" 1 "Active" ;
VAL_ 2365523705 pModule_Control_Applied_State 1 "Partial Wakeup Applied " 0 "No Change Applied" 2 "Full Wakeup Applied" 3 "Power Down Applied " 13 "No Change - Checksum Error " 4 "Stay Awake Applied " 14 "Error State" 15 "Not Available" 5 "Alarm Activation Applied " ;
VAL_ 2365523705 pModule_Control_Command_State 3 "Power Down Requested" 2 "Full Wakeup Requested" 15 "Not Available" 14 "Error" 5 "Alarm Activation Requested" 1 "Partial Wakeup Requested" 4 "Stay Awake Requested" 0 "No Change Requested" ;
VAL_ 2566877689 pTemperature_Units_Selected 0 "Fahrenheit" 1 "Celsius" 3 "Not Available" 2 "Error" ;
VAL_ 2566877689 pTPMS_Learning_Status 7 "Learning Spare Tire" 3 "Learning right front" 1 "Request to start" 13 "Request to end learning process" 14 "Error failed to complete learning process" 2 "Learning left front" 0 "Not started" 5 "Learning right rear" 4 "Learning left rear" 6 "Learning processes successfully completed" 12 "Erase TPMS Sensors" 15 "Not Available" ;
VAL_ 2566877689 pPressure_Units_Selected 3 "Not Available" 1 "Kilopascal (KPa)" 2 "Error" 0 "Pounds Per Square Inch (PSI)" ;
VAL_ 2566877689 pVolume_Units_Selected 6 "Error" 1 "Liters" 0 "Gallons" 7 "Not Avialable" 2 "Imperial Gallons" ;
VAL_ 2566877689 pDisplay_Status 2 "Infotainment can override to full screen" 1 "User has requested full screen" 0 "Infotainment cannot override to full screen" 14 "Infotainment data not being shown" 15 "Not Available" ;
VAL_ 2566877689 pTime_Units_Selected 1 "24 Hour" 3 "Not Available" 0 "12 Hour" 2 "Error" ;
VAL_ 2566877689 pDistance_Units_Selected 1 "Kilometers" 0 "Miles" 3 "Not Available " 2 "Error" ;
VAL_ 2566860071 pSpecial_Msg_12 2 "Error" 0 "Off" 1 "On" 3 "Not-Available" ;
VAL_ 2566860071 pSpecial_Msg_28 2 "Error" 0 "Off" 1 "On" 3 "Not-Available" ;
VAL_ 2566860071 pSpecial_Msg_11 2 "Error" 0 "Off" 1 "On" 3 "Not-Available" ;
VAL_ 2566860071 pSpecial_Msg_26 2 "Error" 0 "Off" 1 "On" 3 "Not-Available" ;
VAL_ 2566860071 pSpecial_Msg_24 2 "Error" 0 "Off" 1 "On" 3 "Not-Available" ;
VAL_ 2566860071 pSpecial_Msg_21 2 "Error" 0 "Off" 1 "On" 3 "Not-Available" ;
VAL_ 2566860071 pSpecial_Msg_18 2 "Error" 0 "Off" 1 "On" 3 "Not-Available" ;
VAL_ 2566860071 pSpecial_Msg_19 2 "Error" 0 "Off" 1 "On" 3 "Not-Available" ;
VAL_ 2566860071 pSpecial_Msg_1_Riding_with_Brake 2 "Error" 0 "Off" 1 "On" 3 "Not-Available" ;
VAL_ 2566860071 pSpecial_Msg_2_Regulator_Overhea 2 "Error" 0 "Off" 1 "On" 3 "Not-Available" ;
VAL_ 2566860071 pSpecial_Msg_3_Regulator_Overhea 2 "Error" 0 "Off" 1 "On" 3 "Not-Available" ;
VAL_ 2566860071 pSpecial_Msg_4_Regulator_Overhea 2 "Error" 0 "Off" 1 "On" 3 "Not-Available" ;
VAL_ 2566860071 pSpecial_Msg_5_Engine_Warmup_Com 2 "Error" 0 "Off" 1 "On" 3 "Not-Available" ;
VAL_ 2566860071 pSpecial_Msg_6_Engine_Knock__Mod 2 "Error" 0 "Off" 1 "On" 3 "Not-Available" ;
VAL_ 2566860071 pSpecial_Msg_8_Low_Coolant_Warni 2 "Error" 0 "Off" 1 "On" 3 "Not-Available" ;
VAL_ 2566860071 pSpecial_Msg_7_Engine_Knock__Mos 2 "Error" 0 "Off" 1 "On" 3 "Not-Available" ;
VAL_ 2566860071 pSpecial_Msg_9_Transmission_Temp 2 "Error" 0 "Off" 1 "On" 3 "Not-Available" ;
VAL_ 2566860071 pSpecial_Msg_10_Reverse_Speed_Li 2 "Error" 0 "Off" 1 "On" 3 "Not-Available" ;
VAL_ 2566860071 pSpecial_Msg_13_Belt_Burn_Warnin 2 "Error" 0 "Off" 1 "On" 3 "Not-Available" ;
VAL_ 2566860071 pSpecial_Msg_14_Park_Brake_Warni 2 "Error" 0 "Off" 1 "On" 3 "Not-Available" ;
VAL_ 2566860071 pSpecial_Msg_15_TCM_Comm_Loss 2 "Error" 0 "Off" 1 "On" 3 "Not-Available" ;
VAL_ 2566860071 pSpecial_Msg_16_TCM_Pump_Priming 2 "Error" 0 "Off" 1 "On" 3 "Not-Available" ;
VAL_ 2566860071 pSpecial_Msg_17_Request_User_to_ 2 "Error" 0 "Off" 1 "On" 3 "Not-Available" ;
VAL_ 2566860071 pSpecial_MSG_20_Fuel_Door_Open_E 2 "Error" 0 "Off" 1 "On" 3 "Not-Available" ;
VAL_ 2566860071 pSpecial_MSG_22_Clutch_Overtemp 2 "Error" 0 "Off" 1 "On" 3 "Not-Available" ;
VAL_ 2566860071 pSpecial_MSG_23_Exhaust_Valve_Ch 2 "Error" 0 "Off" 1 "On" 3 "Not-Available" ;
VAL_ 2566860071 pSpecial_MSG_25_Engine_Idle_Shut 2 "Error" 0 "Off" 1 "On" 3 "Not-Available" ;
VAL_ 2566860071 pSpecial_MSG_27_Overboost_Condit 2 "Error" 0 "Off" 1 "On" 3 "Not-Available" ;
VAL_ 2566860071 pSpecial_Msg_31_Engine_Tip_Over_ 2 "Error" 0 "Off" 1 "On" 3 "Not-Available" ;
VAL_ 2566860071 pSpecial_Msg_32_Engine_Tip_Over_ 2 "Error" 0 "Off" 1 "On" 3 "Not-Available" ;
VAL_ 2365530123 pEngine_Control_Mode 14 "Error" 3 "Engine Torque Request" 2 " Engine Speed Limit" 0 "No Control Request" 15 "Not Available" 1 "Engine Speed Request" 4 "Engine Torque Limit" ;
VAL_ 2365530123 pEngine_Control_Requestor 11 "Remote Accelerator" 8 "Torque Limiting" 9 "High Speed Governor" 15 "Not available" 1 "Accelerator Pedal/Operator Selection" 4 "Road Speed Governor" 0 "Low Idle Governor/No Request" 6 "Transmission Control" 7 "ABS Control" 10 "Braking System" 2 "Cruise Control" 5 "ASR Control" 3 "PTO Governor" ;
VAL_ 2566860321 pAutonomous_Available_Status 2 "Error" 0 "Off" 1 "On" 3 "Not-Available" ;
VAL_ 2566860321 pBrake_Failure_Lamp_Status 2 "Slow Flash (1 Hz, 50% duty cycle)" 7 "Not Available" 1 "On" 3 "Fast Flash (2 HZ or faster, 50% Duty Cycle)" 0 "Off" 6 "Error" ;
VAL_ 2566860321 pBattery_Lamp_Status 2 "Slow Flash (1 Hz, 50% duty cycle)" 7 "Not Available" 1 "On" 3 "Fast Flash (2 HZ or faster, 50% Duty Cycle)" 0 "Off" 6 "Error" ;
VAL_ 2566860321 pOil_Pressure_Lamp_Status 2 "Slow Flash (1 Hz, 50% duty cycle)" 7 "Not Available" 1 "On" 3 "Fast Flash (2 HZ or faster, 50% Duty Cycle)" 0 "Off" 6 "Error" ;
VAL_ 2566860321 pOil_Lamp_Status 2 "Slow Flash (1 Hz, 50% duty cycle)" 7 "Not Available" 1 "On" 3 "Fast Flash (2 HZ or faster, 50% Duty Cycle)" 0 "Off" 6 "Error" ;
VAL_ 2566860321 pTransmission_Lamp_Status 2 "Slow Flash (1 Hz, 50% duty cycle)" 7 "Not Available" 1 "On" 3 "Fast Flash (2 HZ or faster, 50% Duty Cycle)" 0 "Off" 6 "Error" ;
VAL_ 2566860321 pPark_Brake_Lamp_Status 2 "Slow Flash (1 Hz, 50% duty cycle)" 7 "Not Available" 1 "On" 3 "Fast Flash (2 HZ or faster, 50% Duty Cycle)" 0 "Off" 6 "Error" ;
VAL_ 2566860321 pHot_Lamp_Status 2 "Slow Flash (1 Hz, 50% duty cycle)" 7 "Not Available" 1 "On" 3 "Fast Flash (2 HZ or faster, 50% Duty Cycle)" 0 "Off" 6 "Error" ;
VAL_ 2566860321 pHigh_Beam_Status 2 "Slow Flash (1 Hz, 50% duty cycle)" 7 "Not Available" 1 "On" 3 "Fast Flash (2 HZ or faster, 50% Duty Cycle)" 0 "Off" 6 "Error" ;
VAL_ 2566882849 pVCMState 7 "Partial System Off, Neutral Warning" 14 "Error" 5 "Saftey Shut Off, Engine Off" 3 "Ignition On, Engine Off" 0 "System Off" 2 "Accessory" 1 "Car Finder" 15 "Not Available" 6 "Partial System Off, Hazards On" 4 " Ignition On, Engine On" ;
VAL_ 2566882849 pFog_Light_Control_Mode 3 "Auto Off" 2 "Auto On" 1 "Normal" 0 "Disabled" ;
VAL_ 2566882849 pLoadShedSts 7 "Not Available" 1 "Level 1" 0 "Level 0 " 6 "ERROR" 2 "Level 2" 3 "Level 3" ;
VAL_ 2566882961 pVCMState 7 "Partial System Off, Neutral Warning" 14 "Error" 5 "Saftey Shut Off, Engine Off" 3 "Ignition On, Engine Off" 0 "System Off" 2 "Accessory" 1 "Car Finder" 15 "Not Available" 6 "Partial System Off, Hazards On" 4 " Ignition On, Engine On" ;
VAL_ 2566882961 pFog_Light_Control_Mode 3 "Auto Off" 2 "Auto On" 1 "Normal" 0 "Disabled" ;
VAL_ 2566882961 pLoadShedSts 7 "Not Available" 1 "Level 1" 0 "Level 0 " 6 "ERROR" 2 "Level 2" 3 "Level 3" ;
VAL_ 2566911232 Turbo_Oil_Pump_Driver_Circuit 3 "NA" 0 "Active" 2 "Error" 1 "Inactive" ;
